VERSION "hnnbnnnynnnnnnnnnnnnnnnnnnnnnnnnnnnnnnnnnn/4/%%%/4/'%**4nnn///"

NS_ :

BS_:

BU_: BAP_Tester Fahrerdisplay_Kombi HUD ICAS1_X_Gateway ICAS3_Gateway ICC_IO_Node Kombi SmartLight_01 ZR_MIB_TOP_ab_Gen3

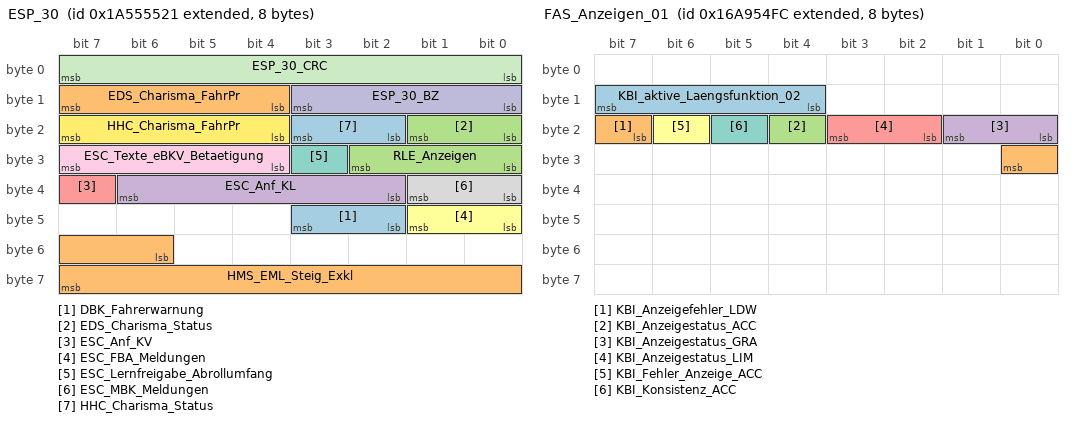
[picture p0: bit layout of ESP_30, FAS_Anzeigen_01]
BO_ 2589283617 ESP_30: 8 ICAS1_X_Gateway
	SG_ DBK_Fahrerwarnung : 42|2@1+ (1,0) [0|3] ""  Fahrerdisplay_Kombi,Kombi
	SG_ EDS_Charisma_FahrPr : 12|4@1+ (1,0) [0|15] ""  Vector__XXX
	SG_ EDS_Charisma_Status : 16|2@1+ (1,0) [0|3] ""  Vector__XXX
	SG_ ESC_Anf_KL : 34|5@1+ (3.22580645,0) [0|99.99999995] "PerCent"  Vector__XXX
	SG_ ESC_Anf_KV : 39|1@1+ (1,0) [0|1] ""  Vector__XXX
	SG_ ESC_FBA_Meldungen : 40|2@1+ (1,0) [0|3] ""  Vector__XXX
	SG_ ESC_Lernfreigabe_Abrollumfang : 27|1@1+ (1,0) [0|1] ""  Vector__XXX
	SG_ ESC_MBK_Meldungen : 32|2@1+ (1,0) [0|3] ""  Kombi
	SG_ ESC_Texte_eBKV_Betaetigung : 28|4@1+ (1,0) [0|15] ""  Vector__XXX
	SG_ ESP_30_BZ : 8|4@1+ (1,0) [0|15] ""  Fahrerdisplay_Kombi,Kombi
	SG_ ESP_30_CRC : 0|8@1+ (1,0) [0|255] ""  Fahrerdisplay_Kombi,Kombi
	SG_ HHC_Charisma_FahrPr : 20|4@1+ (1,0) [0|15] ""  Vector__XXX
	SG_ HHC_Charisma_Status : 18|2@1+ (1,0) [0|3] ""  Vector__XXX
	SG_ HMS_EML_Steig_Exkl : 54|10@1+ (0.2,-102.2) [-102|102.2] "PerCent"  Vector__XXX
	SG_ RLE_Anzeigen : 24|3@1+ (1,0) [0|7] ""  Kombi

BO_ 2527679740 FAS_Anzeigen_01: 8 Kombi
	SG_ KBI_aktive_Laengsfunktion_02 : 12|4@1+ (1,0) [0|15] ""  ICAS1_X_Gateway
	SG_ KBI_Anzeigefehler_LDW : 23|2@1+ (1,0) [0|3] ""  ICAS1_X_Gateway
	SG_ KBI_Anzeigestatus_ACC : 20|1@1+ (1,0) [0|1] ""  ICAS1_X_Gateway
	SG_ KBI_Anzeigestatus_GRA : 16|2@1+ (1,0) [0|3] ""  ICAS1_X_Gateway
	SG_ KBI_Anzeigestatus_LIM : 18|2@1+ (1,0) [0|3] ""  ICAS1_X_Gateway
	SG_ KBI_Fehler_Anzeige_ACC : 22|1@1+ (1,0) [0|1] ""  ICAS1_X_Gateway
	SG_ KBI_Konsistenz_ACC : 21|1@1+ (1,0) [0|1] ""  ICAS1_X_Gateway

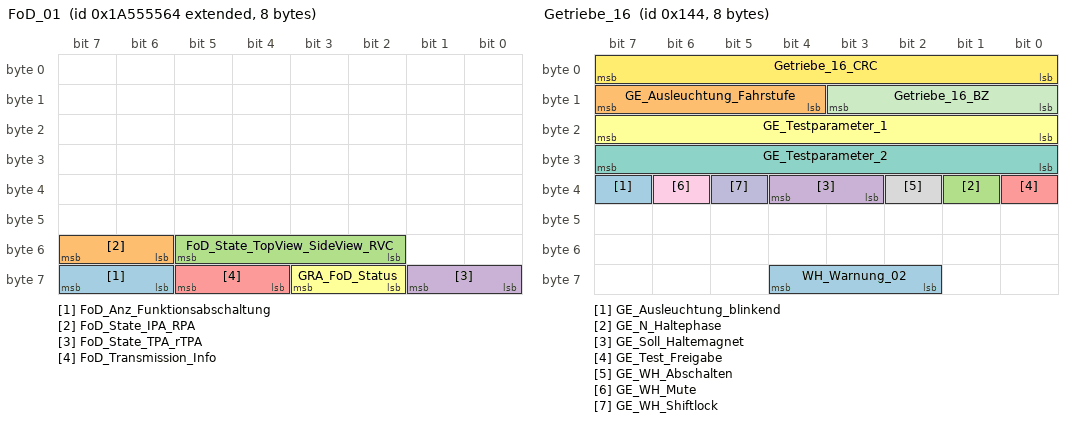
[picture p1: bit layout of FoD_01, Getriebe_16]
BO_ 2589283684 FoD_01: 8 ICAS1_X_Gateway
	SG_ FoD_Anz_Funktionsabschaltung : 62|2@1+ (1,0) [0|3] ""  Kombi
	SG_ FoD_State_IPA_RPA : 54|2@1+ (1,0) [0|3] ""  Vector__XXX
	SG_ FoD_State_TopView_SideView_RVC : 50|4@1+ (1,0) [0|15] ""  Vector__XXX
	SG_ FoD_State_TPA_rTPA : 56|2@1+ (1,0) [0|3] ""  Vector__XXX
	SG_ FoD_Transmission_Info : 60|2@1+ (1,0) [0|3] ""  ICAS3_Gateway,ZR_MIB_TOP_ab_Gen3
	SG_ GRA_FoD_Status : 58|2@1+ (1,0) [0|3] ""  Vector__XXX

BO_ 2549875476 FoD_Kombi_Req: 8 ICAS1_X_Gateway
	SG_ FoD_Kombi_Req_Data : 0|64@1+ (1,0) [0|18446744073709551616] ""  Kombi

BO_ 2550006548 FoD_Kombi_Resp: 8 Kombi
	SG_ FoD_Kombi_Resp_Data : 0|64@1+ (1,0) [0|18446744073709551616] ""  ICAS1_X_Gateway

BO_ 2549875571 FoD_ZR_Req: 8 ICAS1_X_Gateway
	SG_ FoD_ZR_Req_Data : 0|64@1+ (1,0) [0|18446744073709551616] ""  ICAS3_Gateway,ICC_IO_Node,ZR_MIB_TOP_ab_Gen3

BO_ 2550006643 FoD_ZR_Resp: 8 ICAS3_Gateway
	SG_ FoD_ZR_Resp_Data : 0|64@1+ (1,0) [0|18446744073709551616] ""  ICAS1_X_Gateway

BO_ 986 Gateway_71: 8 Vector__XXX
	SG_ ABS_Bremsung : 13|1@1+ (1,0) [0|1] ""  Vector__XXX
	SG_ ECD_Bremslicht : 8|1@1+ (1,0) [0|1] ""  Vector__XXX
	SG_ EPB_01_alt : 1|1@1+ (1,0) [0|1] ""  Vector__XXX
	SG_ EPB_Pedalweg_Kuppl : 16|8@1+ (0.4,0) [8|92] "PerCent"  Vector__XXX
	SG_ EPB_QBit_Pedalweg_Kuppl : 11|1@1+ (1,0) [0|1] ""  Vector__XXX
	SG_ EPB_Status : 9|2@1+ (1,0) [0|3] ""  Vector__XXX
	SG_ ESP_05_alt : 0|1@1+ (1,0) [0|1] ""  Vector__XXX
	SG_ ESP_21_alt : 2|1@1+ (1,0) [0|1] ""  ZR_MIB_TOP_ab_Gen3
	SG_ ESP_Eingriff : 14|1@1+ (1,0) [0|1] ""  Vector__XXX
	SG_ ESP_HDC_Standby : 6|1@1+ (1,0) [0|1] ""  Vector__XXX
	SG_ ESP_MKB_Abbruch_Geschw : 62|1@1+ (1,0) [0|1] ""  Vector__XXX
	SG_ ESP_QBit_v_Signal : 12|1@1+ (1,0) [0|1] ""  ZR_MIB_TOP_ab_Gen3
	SG_ ESP_v_Signal : 24|16@1+ (0.01,0) [0|655.32] "KiloMeterPerHour"  ZR_MIB_TOP_ab_Gen3
	SG_ Kamera_FSH_aktiv : 15|1@1+ (1,0) [0|1] ""  Vector__XXX
	SG_ Kamera_Status_alt : 5|1@1+ (1,0) [0|1] ""  Vector__XXX
	SG_ LWI_01_alt : 3|1@1+ (1,0) [0|1] ""  Vector__XXX
	SG_ LWI_Lenkradwinkel : 43|13@1+ (0.1,0) [0|800] "DegreOfArc"  Vector__XXX
	SG_ LWI_QBit_Lenkradwinkel : 40|1@1+ (1,0) [0|1] ""  Vector__XXX
	SG_ LWI_Sensorstatus : 41|1@1+ (1,0) [0|1] ""  Vector__XXX
	SG_ LWI_VZ_Lenkradwinkel : 42|1@1+ (1,0) [0|1] ""  Vector__XXX
	SG_ Parkhilfe_01_alt : 4|1@1+ (1,0) [0|1] ""  Vector__XXX
	SG_ PH_Anf_Audioabsenkung : 56|1@1+ (1,0) [0|1] ""  Vector__XXX
	SG_ PH_Systemzustand : 57|3@1+ (1,0) [0|7] ""  Vector__XXX
	SG_ PH_Taster : 60|2@1+ (1,0) [0|3] ""  Vector__XXX
	SG_ PLA_Anf_Aufschaltung_RVC : 63|1@1+ (1,0) [0|1] ""  Vector__XXX

BO_ 988 Gateway_73: 8 ICAS1_X_Gateway
	SG_ ACC_18_alt : 59|1@1+ (1,0) [0|1] ""  Vector__XXX
	SG_ ACC_Status_ACC : 56|3@1+ (1,0) [0|7] ""  Vector__XXX
	SG_ EPB_Status_02 : 53|3@1+ (1,0) [0|7] ""  Vector__XXX
	SG_ ESP_07_alt : 1|1@1+ (1,0) [0|1] ""  ICAS3_Gateway,Kombi,ZR_MIB_TOP_ab_Gen3
	SG_ ESP_50_alt : 7|1@1+ (1,0) [0|1] ""  Vector__XXX
	SG_ ESP_Rollenmodus_Deaktivieren : 46|1@1+ (1,0) [0|1] ""  ICAS3_Gateway,Kombi,ZR_MIB_TOP_ab_Gen3
	SG_ ESP_Status_Bremsentemp_02 : 62|2@1+ (1,0) [0|3] ""  Vector__XXX
	SG_ GE_Fahrstufe : 40|4@1+ (1,0) [0|15] ""  ZR_MIB_TOP_ab_Gen3
	SG_ GE_Freilauf_Status : 47|3@1+ (1,0) [0|7] ""  Vector__XXX
	SG_ GE_Notlauf : 45|1@1+ (1,0) [0|1] ""  Vector__XXX
	SG_ GE_Sperr_Info_WFS : 50|1@1+ (1,0) [0|1] ""  Vector__XXX
	SG_ GE_Ursache_Fahrstufe_N : 44|1@1+ (1,0) [0|1] ""  Vector__XXX
	SG_ Getriebe_11_alt : 2|1@1+ (1,0) [0|1] ""  Vector__XXX
	SG_ Getriebe_13_alt : 3|1@1+ (1,0) [0|1] ""  Vector__XXX
	SG_ Getriebe_14_alt : 6|1@1+ (1,0) [0|1] ""  Vector__XXX
	SG_ Getriebe_17_alt : 4|1@1+ (1,0) [0|1] ""  Vector__XXX
	SG_ MKE_Stufe : 11|3@1+ (1,0) [0|7] ""  Vector__XXX
	SG_ MKE_Texte : 9|2@1+ (1,0) [0|3] ""  Vector__XXX
	SG_ MO_Drehzahl_01 : 16|16@1+ (0.25,0) [0|16383] "MinutInver"  Vector__XXX
	SG_ MO_QBit_Drehzahl_01 : 8|1@1+ (1,0) [0|1] ""  ZR_MIB_TOP_ab_Gen3
	SG_ Motor_12_alt : 0|1@1+ (1,0) [0|1] ""  ZR_MIB_TOP_ab_Gen3
	SG_ TSK_06_alt : 5|1@1+ (1,0) [0|1] ""  Vector__XXX
	SG_ TSK_Hauptschalter_GRA_ACC : 14|2@1+ (1,0) [0|3] ""  Vector__XXX
	SG_ TSK_Limiter_ausgewaehlt : 51|1@1+ (1,0) [0|1] ""  Vector__XXX

BO_ 324 Getriebe_16: 8 ICAS1_X_Gateway
	SG_ GE_Ausleuchtung_blinkend : 39|1@1+ (1,0) [0|1] ""  Vector__XXX
	SG_ GE_Ausleuchtung_Fahrstufe : 12|4@1+ (1,0) [0|15] ""  Fahrerdisplay_Kombi,Kombi
	SG_ GE_N_Haltephase : 33|1@1+ (1,0) [0|1] ""  Vector__XXX
	SG_ GE_Soll_Haltemagnet : 35|2@1+ (1,0) [0|3] ""  Vector__XXX
	SG_ GE_Test_Freigabe : 32|1@1+ (1,0) [0|1] ""  Vector__XXX
	SG_ GE_Testparameter_1 : 16|8@1+ (1,0) [0|255] ""  Vector__XXX
	SG_ GE_Testparameter_2 : 24|8@1+ (1,0) [0|255] ""  Vector__XXX
	SG_ GE_WH_Abschalten : 34|1@1+ (1,0) [0|1] ""  Vector__XXX
	SG_ GE_WH_Mute : 38|1@1+ (1,0) [0|1] ""  Vector__XXX
	SG_ GE_WH_Shiftlock : 37|1@1+ (1,0) [0|1] ""  Vector__XXX
	SG_ Getriebe_16_BZ : 8|4@1+ (1,0) [0|15] ""  Fahrerdisplay_Kombi,Kombi
	SG_ Getriebe_16_CRC : 0|8@1+ (1,0) [0|255] ""  Fahrerdisplay_Kombi,Kombi
	SG_ WH_Warnung_02 : 58|3@1+ (1,0) [0|7] ""  Vector__XXX

BO_ 588 Heckradar_01: 16 ICAS1_X_Gateway
	SG_ ASW_Kombiausgabe : 56|3@1+ (1,0) [0|7] ""  Vector__XXX
	SG_ ASW_Kombitexte : 94|3@1+ (1,0) [0|7] ""  Kombi
	SG_ ASW_Modus : 98|3@1+ (1,0) [0|7] ""  Vector__XXX
	SG_ ASW_Status : 86|2@1+ (1,0) [0|3] ""  Vector__XXX
	SG_ ASW_Ton_Richtung_HL : 36|1@1+ (1,0) [0|1] ""  ICAS3_Gateway,ZR_MIB_TOP_ab_Gen3
	SG_ ASW_Ton_Richtung_HR : 37|1@1+ (1,0) [0|1] ""  ICAS3_Gateway,ZR_MIB_TOP_ab_Gen3
	SG_ ASW_Ton_Richtung_VL : 34|1@1+ (1,0) [0|1] ""  ICAS3_Gateway,ZR_MIB_TOP_ab_Gen3
	SG_ ASW_Ton_Richtung_VR : 35|1@1+ (1,0) [0|1] ""  ICAS3_Gateway,ZR_MIB_TOP_ab_Gen3
	SG_ ASW_Warnung_BFS : 93|1@1+ (1,0) [0|1] ""  Vector__XXX
	SG_ ASW_Warnung_FS : 92|1@1+ (1,0) [0|1] ""  Vector__XXX
	SG_ Heckradar_Kombitexte : 120|5@1+ (1,0) [0|31] ""  Kombi
	SG_ HRE_Anzeigetexte : 108|4@1+ (1,0) [0|15] ""  Kombi
	SG_ RCTA_Kombitexte : 125|3@1+ (1,0) [0|7] ""  Kombi
	SG_ SWA_Anzeigen : 76|4@1+ (1,0) [0|15] ""  Kombi
	SG_ SWA_Blindheit_erkannt : 80|1@1+ (1,0) [0|1] ""  Vector__XXX
	SG_ SWA_Blindheitsverdacht : 119|1@1+ (1,0) [0|1] ""  Vector__XXX
	SG_ SWA_Brightness_Mode_FPM : 40|4@1+ (1,0) [0|15] ""  Vector__XXX
	SG_ SWA_FT_RueckLED : 85|1@1+ (1,0) [0|1] ""  Vector__XXX
	SG_ SWA_Gischtzaehler : 112|7@1+ (1,0) [0|100] "PerCent"  Vector__XXX
	SG_ SWA_Infostufe_Assist_li : 46|1@1+ (1,0) [0|1] ""  Vector__XXX
	SG_ SWA_Infostufe_Assist_re : 47|1@1+ (1,0) [0|1] ""  Vector__XXX
	SG_ SWA_Kombiausgabe : 53|3@1+ (1,0) [0|7] ""  Vector__XXX
	SG_ SWA_LED_Hell_BFS : 12|7@1+ (1,0) [0|100] "PerCent"  Vector__XXX
	SG_ SWA_LED_Hell_FS : 19|7@1+ (1,0) [0|100] "PerCent"  Vector__XXX
	SG_ SWA_LED_Modus_BFS : 26|3@1+ (1,0) [0|7] ""  Vector__XXX
	SG_ SWA_LED_Modus_FS : 29|3@1+ (1,0) [0|7] ""  Vector__XXX
	SG_ SWA_Modus : 101|3@1+ (1,0) [0|7] ""  Vector__XXX
	SG_ SWA_Modus_System : 50|3@1+ (1,0) [0|7] ""  Vector__XXX
	SG_ SWA_rel_Fehler : 82|1@1+ (1,0) [0|1] ""  Vector__XXX
	SG_ SWA_rel_Nichtverf : 81|1@1+ (1,0) [0|1] ""  Vector__XXX
	SG_ SWA_Sta_aktiv : 83|1@1+ (1,0) [0|1] ""  Kombi
	SG_ SWA_Sta_passiv : 84|1@1+ (1,0) [0|1] ""  Kombi
	SG_ SWA_Standziele_li : 88|1@1+ (1,0) [0|1] ""  Vector__XXX
	SG_ SWA_Standziele_re : 104|1@1+ (1,0) [0|1] ""  Vector__XXX
	SG_ SWA_Status : 32|2@1+ (1,0) [0|3] ""  Vector__XXX
	SG_ SWA_Status_KuFu : 44|2@1+ (1,0) [0|3] ""  Vector__XXX
	SG_ SWA_Status_System : 38|2@1+ (1,0) [0|3] ""  Vector__XXX
	SG_ SWA_Warnstufe_Assist_li : 48|1@1+ (1,0) [0|1] ""  Vector__XXX
	SG_ SWA_Warnstufe_Assist_re : 49|1@1+ (1,0) [0|1] ""  Vector__XXX

BO_ 589 Heckradar_02: 64 ICAS1_X_Gateway
	SG_ SWA_Infostufe_SWA_li : 60|1@1+ (1,0) [0|1] ""  Kombi
	SG_ SWA_Infostufe_SWA_re : 61|1@1+ (1,0) [0|1] ""  Kombi
	SG_ SWA_Kolonne_li : 57|1@1+ (1,0) [0|1] ""  Vector__XXX
	SG_ SWA_Kolonne_mi : 58|1@1+ (1,0) [0|1] ""  Vector__XXX
	SG_ SWA_Kolonne_re : 59|1@1+ (1,0) [0|1] ""  Vector__XXX
	SG_ SWA_Obj_01_Breite : 137|7@1+ (0.03125,0) [0|3.9375] "Meter"  Vector__XXX
	SG_ SWA_Obj_01_Existenzwahrsch : 153|7@1+ (1,0) [0|100] "PerCent"  Vector__XXX
	SG_ SWA_Obj_01_Gemessen : 92|1@1+ (1,0) [0|1] ""  Vector__XXX
	SG_ SWA_Obj_01_GeschwRelX : 128|9@1+ (0.25,-37.5) [-37.5|90] "MeterPerSecon"  Vector__XXX
	SG_ SWA_Obj_01_GeschwRelY : 144|9@1+ (0.03125,-7.9375) [-7.9375|8] "MeterPerSecon"  Vector__XXX
	SG_ SWA_Obj_01_ID : 93|5@1+ (1,0) [1|30] ""  Vector__XXX
	SG_ SWA_Obj_01_Laenge : 177|7@1+ (0.25,0) [0|31.5] "Meter"  Vector__XXX
	SG_ SWA_Obj_01_Objektklasse : 160|4@1+ (1,0) [0|15] ""  Vector__XXX
	SG_ SWA_Obj_01_PositionX : 168|9@1+ (0.25,-102.5) [-102.5|25] "Meter"  Vector__XXX
	SG_ SWA_Obj_01_PositionY : 184|8@1+ (0.125,-16) [-16|15.75] "Meter"  Vector__XXX
	SG_ SWA_Obj_01_ReferenzPkt : 164|4@1+ (1,0) [0|15] ""  Vector__XXX
	SG_ SWA_Obj_02_Breite : 201|7@1+ (0.03125,0) [0|3.9375] "Meter"  Vector__XXX
	SG_ SWA_Obj_02_Existenzwahrsch : 217|7@1+ (1,0) [0|100] "PerCent"  Vector__XXX
	SG_ SWA_Obj_02_Gemessen : 98|1@1+ (1,0) [0|1] ""  Vector__XXX
	SG_ SWA_Obj_02_GeschwRelX : 192|9@1+ (0.25,-37.5) [-37.5|90] "MeterPerSecon"  Vector__XXX
	SG_ SWA_Obj_02_GeschwRelY : 208|9@1+ (0.03125,-7.9375) [-7.9375|8] "MeterPerSecon"  Vector__XXX
	SG_ SWA_Obj_02_ID : 99|5@1+ (1,0) [1|30] ""  Vector__XXX
	SG_ SWA_Obj_02_Laenge : 241|7@1+ (0.25,0) [0|31.5] "Meter"  Vector__XXX
	SG_ SWA_Obj_02_Objektklasse : 224|4@1+ (1,0) [0|15] ""  Vector__XXX
	SG_ SWA_Obj_02_PositionX : 232|9@1+ (0.25,-102.5) [-102.5|25] "Meter"  Vector__XXX
	SG_ SWA_Obj_02_PositionY : 248|8@1+ (0.125,-16) [-16|15.75] "Meter"  Vector__XXX
	SG_ SWA_Obj_02_ReferenzPkt : 228|4@1+ (1,0) [0|15] ""  Vector__XXX
	SG_ SWA_Obj_03_Breite : 265|7@1+ (0.03125,0) [0|3.9375] "Meter"  Vector__XXX
	SG_ SWA_Obj_03_Existenzwahrsch : 281|7@1+ (1,0) [0|100] "PerCent"  Vector__XXX
	SG_ SWA_Obj_03_Gemessen : 104|1@1+ (1,0) [0|1] ""  Vector__XXX
	SG_ SWA_Obj_03_GeschwRelX : 256|9@1+ (0.25,-37.5) [-37.5|90] "MeterPerSecon"  Vector__XXX
	SG_ SWA_Obj_03_GeschwRelY : 272|9@1+ (0.03125,-7.9375) [-7.9375|8] "MeterPerSecon"  Vector__XXX
	SG_ SWA_Obj_03_ID : 105|5@1+ (1,0) [1|30] ""  Vector__XXX
	SG_ SWA_Obj_03_Laenge : 305|7@1+ (0.25,0) [0|31.5] "Meter"  Vector__XXX
	SG_ SWA_Obj_03_Objektklasse : 288|4@1+ (1,0) [0|15] ""  Vector__XXX
	SG_ SWA_Obj_03_PositionX : 296|9@1+ (0.25,-102.5) [-102.5|25] "Meter"  Vector__XXX
	SG_ SWA_Obj_03_PositionY : 312|8@1+ (0.125,-16) [-16|15.75] "Meter"  Vector__XXX
	SG_ SWA_Obj_03_ReferenzPkt : 292|4@1+ (1,0) [0|15] ""  Vector__XXX
	SG_ SWA_Obj_04_Breite : 329|7@1+ (0.03125,0) [0|3.9375] "Meter"  Vector__XXX
	SG_ SWA_Obj_04_Existenzwahrsch : 345|7@1+ (1,0) [0|100] "PerCent"  Vector__XXX
	SG_ SWA_Obj_04_Gemessen : 110|1@1+ (1,0) [0|1] ""  Vector__XXX
	SG_ SWA_Obj_04_GeschwRelX : 320|9@1+ (0.25,-37.5) [-37.5|90] "MeterPerSecon"  Vector__XXX
	SG_ SWA_Obj_04_GeschwRelY : 336|9@1+ (0.03125,-7.9375) [-7.9375|8] "MeterPerSecon"  Vector__XXX
	SG_ SWA_Obj_04_ID : 111|5@1+ (1,0) [1|30] ""  Vector__XXX
	SG_ SWA_Obj_04_Laenge : 369|7@1+ (0.25,0) [0|31.5] "Meter"  Vector__XXX
	SG_ SWA_Obj_04_Objektklasse : 352|4@1+ (1,0) [0|15] ""  Vector__XXX
	SG_ SWA_Obj_04_PositionX : 360|9@1+ (0.25,-102.5) [-102.5|25] "Meter"  Vector__XXX
	SG_ SWA_Obj_04_PositionY : 376|8@1+ (0.125,-16) [-16|15.75] "Meter"  Vector__XXX
	SG_ SWA_Obj_04_ReferenzPkt : 356|4@1+ (1,0) [0|15] ""  Vector__XXX
	SG_ SWA_Obj_05_Breite : 393|7@1+ (0.03125,0) [0|3.9375] "Meter"  Vector__XXX
	SG_ SWA_Obj_05_Existenzwahrsch : 409|7@1+ (1,0) [0|100] "PerCent"  Vector__XXX
	SG_ SWA_Obj_05_Gemessen : 116|1@1+ (1,0) [0|1] ""  Vector__XXX
	SG_ SWA_Obj_05_GeschwRelX : 384|9@1+ (0.25,-37.5) [-37.5|90] "MeterPerSecon"  Vector__XXX
	SG_ SWA_Obj_05_GeschwRelY : 400|9@1+ (0.03125,-7.9375) [-7.9375|8] "MeterPerSecon"  Vector__XXX
	SG_ SWA_Obj_05_ID : 117|5@1+ (1,0) [1|30] ""  Vector__XXX
	SG_ SWA_Obj_05_Laenge : 433|7@1+ (0.25,0) [0|31.5] "Meter"  Vector__XXX
	SG_ SWA_Obj_05_Objektklasse : 416|4@1+ (1,0) [0|15] ""  Vector__XXX
	SG_ SWA_Obj_05_PositionX : 424|9@1+ (0.25,-102.5) [-102.5|25] "Meter"  Vector__XXX
	SG_ SWA_Obj_05_PositionY : 440|8@1+ (0.125,-16) [-16|15.75] "Meter"  Vector__XXX
	SG_ SWA_Obj_05_ReferenzPkt : 420|4@1+ (1,0) [0|15] ""  Vector__XXX
	SG_ SWA_Obj_06_Breite : 457|7@1+ (0.03125,0) [0|3.9375] "Meter"  Vector__XXX
	SG_ SWA_Obj_06_Existenzwahrsch : 473|7@1+ (1,0) [0|100] "PerCent"  Vector__XXX
	SG_ SWA_Obj_06_Gemessen : 122|1@1+ (1,0) [0|1] ""  Vector__XXX
	SG_ SWA_Obj_06_GeschwRelX : 448|9@1+ (0.25,-37.5) [-37.5|90] "MeterPerSecon"  Vector__XXX
	SG_ SWA_Obj_06_GeschwRelY : 464|9@1+ (0.03125,-7.9375) [-7.9375|8] "MeterPerSecon"  Vector__XXX
	SG_ SWA_Obj_06_ID : 123|5@1+ (1,0) [1|30] ""  Vector__XXX
	SG_ SWA_Obj_06_Laenge : 497|7@1+ (0.25,0) [0|31.5] "Meter"  Vector__XXX
	SG_ SWA_Obj_06_Objektklasse : 480|4@1+ (1,0) [0|15] ""  Vector__XXX
	SG_ SWA_Obj_06_PositionX : 488|9@1+ (0.25,-102.5) [-102.5|25] "Meter"  Vector__XXX
	SG_ SWA_Obj_06_PositionY : 504|8@1+ (0.125,-16) [-16|15.75] "Meter"  Vector__XXX
	SG_ SWA_Obj_06_ReferenzPkt : 484|4@1+ (1,0) [0|15] ""  Vector__XXX
	SG_ SWA_Obj_Kurvenradius : 64|16@1+ (1,-32767) [-32767|32767] "Meter"  Vector__XXX
	SG_ SWA_StrukturLinks_querAbstand : 12|9@1+ (0.03125,0) [0|15.9375] "Meter"  Vector__XXX
	SG_ SWA_StrukturLinks_Typ : 21|3@1+ (1,0) [0|7] ""  Vector__XXX
	SG_ SWA_StrukturRechts_querAbstand : 80|9@1+ (0.03125,0) [0|15.9375] "Meter"  Vector__XXX
	SG_ SWA_StrukturRechts_Typ : 89|3@1+ (1,0) [0|7] ""  Vector__XXX
	SG_ SWA_Umfeld_Zeitstempel : 24|16@1+ (0.1,0) [0|6553.5] "MilliSecon"  Vector__XXX
	SG_ SWA_Umfeld_Zeitstempel_Status : 54|3@1+ (1,0) [0|7] ""  Vector__XXX
	SG_ SWA_Warnung_SWA_li : 62|1@1+ (1,0) [0|1] ""  Kombi
	SG_ SWA_Warnung_SWA_re : 63|1@1+ (1,0) [0|1] ""  Kombi

BO_ 2635073907 HID_DispKBI_FS_ZR_Req_FD: 64 Fahrerdisplay_Kombi
	SG_ HID_DispKBI_FS_ZR_Req_FD_Data : 0|512@1+ (1,0) [0|13407807929942597099574024998205846127479365820592393377723561443721764030073546976801874298166903427690031858186486050853753882811946569946433649006084096] ""  ICAS3_Gateway

BO_ 2635204979 HID_DispKBI_FS_ZR_Resp_FD: 64 ICAS3_Gateway
	SG_ HID_DispKBI_FS_ZR_Resp_FD_Data : 0|512@1+ (1,0) [0|13407807929942597099574024998205846127479365820592393377723561443721764030073546976801874298166903427690031858186486050853753882811946569946433649006084096] ""  Fahrerdisplay_Kombi

BO_ 2634029939 HID_HUD_ZR_Req_FD: 64 HUD
	SG_ HID_HUD_ZR_Req_FD_Data : 0|512@1+ (1,0) [0|13407807929942597099574024998205846127479365820592393377723561443721764030073546976801874298166903427690031858186486050853753882811946569946433649006084096] ""  ICAS3_Gateway,ICC_IO_Node,ZR_MIB_TOP_ab_Gen3

BO_ 2634161011 HID_HUD_ZR_Resp_FD: 64 ICAS3_Gateway
	SG_ HID_HUD_ZR_Resp_FD_Data : 0|512@1+ (1,0) [0|13407807929942597099574024998205846127479365820592393377723561443721764030073546976801874298166903427690031858186486050853753882811946569946433649006084096] ""  HUD

BO_ 2634314505 HID_ZR_DispKBI_FS_Req_FD: 64 ICAS3_Gateway
	SG_ HID_ZR_DispKBI_FS_Req_FD_Data : 0|512@1+ (1,0) [0|13407807929942597099574024998205846127479365820592393377723561443721764030073546976801874298166903427690031858186486050853753882811946569946433649006084096] ""  Fahrerdisplay_Kombi

BO_ 2634445577 HID_ZR_DispKBI_FS_Resp_FD: 64 Fahrerdisplay_Kombi
	SG_ HID_ZR_DispKBI_FS_Resp_FD_Data : 0|512@1+ (1,0) [0|13407807929942597099574024998205846127479365820592393377723561443721764030073546976801874298166903427690031858186486050853753882811946569946433649006084096] ""  ICAS3_Gateway

BO_ 2634052379 HID_ZR_HUD_Req_FD: 64 ICAS3_Gateway
	SG_ HID_ZR_HUD_Req_FD_Data : 0|512@1+ (1,0) [0|13407807929942597099574024998205846127479365820592393377723561443721764030073546976801874298166903427690031858186486050853753882811946569946433649006084096] ""  HUD

BO_ 2634183451 HID_ZR_HUD_Resp_FD: 64 HUD
	SG_ HID_ZR_HUD_Resp_FD_Data : 0|512@1+ (1,0) [0|13407807929942597099574024998205846127479365820592393377723561443721764030073546976801874298166903427690031858186486050853753882811946569946433649006084096] ""  ICAS3_Gateway,ICC_IO_Node,ZR_MIB_TOP_ab_Gen3

BO_ 2629835579 HUD_ARC_Req_FD: 64 HUD
	SG_ HUD_ARC_Req_FD_Data : 0|512@1+ (1,0) [0|13407807929942597099574024998205846127479365820592393377723561443721764030073546976801874298166903427690031858186486050853753882811946569946433649006084096] ""  ICAS3_Gateway,ICC_IO_Node,ZR_MIB_TOP_ab_Gen3

BO_ 2629966651 HUD_ARC_Resp_FD: 64 ICAS3_Gateway
	SG_ HUD_ARC_Resp_FD_Data : 0|512@1+ (1,0) [0|13407807929942597099574024998205846127479365820592393377723561443721764030073546976801874298166903427690031858186486050853753882811946569946433649006084096] ""  HUD

BO_ 1283 HVK_01: 8 ICAS1_X_Gateway
	SG_ HV_Bordnetz_aktiv : 41|1@1+ (1,0) [0|1] ""  Vector__XXX
	SG_ HV_Bordnetz_Fehler : 42|1@1+ (1,0) [0|1] ""  Vector__XXX
	SG_ HVK_01_BZ : 8|4@1+ (1,0) [0|15] ""  Fahrerdisplay_Kombi
	SG_ HVK_01_CRC : 0|8@1+ (1,0) [0|255] ""  Fahrerdisplay_Kombi
	SG_ HVK_AktiveEntladung_Anf : 45|1@1+ (1,0) [0|1] ""  Vector__XXX
	SG_ HVK_BMS_Sollmodus : 24|3@1+ (1,0) [0|7] ""  Vector__XXX
	SG_ HVK_DCDC_Sollmodus : 27|3@1+ (1,0) [0|7] ""  Vector__XXX
	SG_ HVK_EKK_Sollmodus : 30|3@1+ (1,0) [0|7] ""  Vector__XXX
	SG_ HVK_Gesamtst_Spgfreiheit : 43|2@1+ (1,0) [0|3] ""  Kombi
	SG_ HVK_HV_Netz_Warnungen : 39|2@1+ (1,0) [0|3] ""  Fahrerdisplay_Kombi,Kombi
	SG_ HVK_HVEM_Freigabe : 46|2@1+ (1,0) [0|3] ""  Vector__XXX
	SG_ HVK_HVLM_Sollmodus : 36|3@1+ (1,0) [0|7] ""  Vector__XXX
	SG_ HVK_HVPTC_Sollmodus : 33|3@1+ (1,0) [0|7] ""  Vector__XXX
	SG_ HVK_Iso_Messung_Start : 50|3@1+ (1,0) [0|7] ""  Vector__XXX
	SG_ HVK_Istmodus_Anf : 12|1@1+ (1,0) [0|1] ""  Vector__XXX
	SG_ HVK_Ladebereit : 53|3@1+ (1,0) [0|7] ""  Vector__XXX
	SG_ HVK_Notabschaltung_Anf : 48|2@1+ (1,0) [0|3] ""  Vector__XXX
	SG_ HVK_PPulsFreigabe : 56|2@1+ (1,0) [0|3] ""  Vector__XXX
	SG_ HVK_TN1_Sollmodus : 13|2@1+ (1,0) [0|3] ""  Vector__XXX
	SG_ HVK_Vorladung_aktiv : 15|1@1+ (1,0) [0|1] ""  Vector__XXX

BO_ 2527679583 IPA_02: 8 ICAS1_X_Gateway
	SG_ FoD_DTC_IPA_EPH : 17|1@1+ (1,0) [0|1] ""  Vector__XXX
	SG_ FoD_DTC_RPA_EPH : 16|1@1+ (1,0) [0|1] ""  Vector__XXX
	SG_ FoD_DTC_TPA_rTPA_EPH : 18|2@1+ (1,0) [0|3] ""  Vector__XXX
	SG_ IPA_02_BZ : 8|4@1+ (1,0) [0|15] ""  Vector__XXX
	SG_ IPA_02_CRC : 0|8@1+ (1,0) [0|255] ""  Vector__XXX
	SG_ IPA_Anf_Meldungen : 56|8@1+ (1,0) [0|255] ""  Kombi
	SG_ Parken_aktives_System_02 : 24|5@1+ (1,0) [0|31] ""  Vector__XXX
	SG_ Parken_Aktivierungslicht_Anf : 36|1@1+ (1,0) [0|1] ""  Vector__XXX
	SG_ Parken_Bestaetigungsblinken_Anf : 52|2@1+ (1,0) [0|3] ""  Vector__XXX
	SG_ Parken_Fahrbereitschaftlicht_Anf : 54|1@1+ (1,0) [0|1] ""  Vector__XXX
	SG_ Parken_Fahrerhinweise_Anf : 51|1@1+ (1,0) [0|1] ""  Vector__XXX
	SG_ Parken_Fahrtrichtungslicht_Anf : 37|2@1+ (1,0) [0|3] ""  Vector__XXX
	SG_ Parken_FFB_LED_Anf : 32|2@1+ (1,0) [0|3] ""  Vector__XXX
	SG_ Parken_Lichtnachlauf_Anf : 39|1@1+ (1,0) [0|1] ""  Vector__XXX
	SG_ Parken_Lichtsteuerung_Anf : 55|1@1+ (1,0) [0|1] ""  Vector__XXX
	SG_ Parken_Schluesselsuche_Anf : 31|1@1+ (1,0) [0|1] ""  Vector__XXX
	SG_ Parken_Seitenspiegel_Anf : 20|2@1+ (1,0) [0|3] ""  Vector__XXX
	SG_ Parken_Wegfahrsperren_Anf : 34|2@1+ (1,0) [0|3] ""  Vector__XXX
	SG_ Parken_ZR_Sondermodus_Anf : 29|2@1+ (1,0) [0|3] ""  Vector__XXX
	SG_ Parken_ZV_Schliessen : 22|2@1+ (1,0) [0|3] ""  Vector__XXX
	SG_ RA_Anf_Meldung : 40|7@1+ (1,0) [0|127] ""  Vector__XXX

BO_ 1792 ISO_Funktionaler_Req_All: 8 ICAS1_X_Gateway
	SG_ ISO_ALL_01_Req_Data : 0|64@1+ (1,0) [0|18446744073709551616] ""  Fahrerdisplay_Kombi,HUD,ICAS3_Gateway,ICC_IO_Node,Kombi,SmartLight_01,ZR_MIB_TOP_ab_Gen3

BO_ 1819 ISO_HUD_Req: 8 ICAS1_X_Gateway
	SG_ ISO_HUD_Req_Data : 0|64@1+ (1,0) [0|18446744073709551616] ""  HUD

BO_ 1925 ISO_HUD_Resp: 8 HUD
	SG_ ISO_HUD_Resp_Data : 0|64@1+ (1,0) [0|18446744073709551616] ""  ICAS1_X_Gateway

BO_ 1812 ISO_Kombi_Req: 8 ICAS1_X_Gateway
	SG_ ISO_Kombi_Req_Data : 0|64@1+ (1,0) [0|18446744073709551616] ""  Kombi

BO_ 1918 ISO_Kombi_Resp: 8 Kombi
	SG_ ISO_Kombi_Resp_Data : 0|64@1+ (1,0) [0|18446744073709551616] ""  ICAS1_X_Gateway

BO_ 2549358366 ISO_NFCIApp_NFCIServ_Req: 8 Vector__XXX
	SG_ ISO_NFCIApp_NFCIServ_Req_Data : 0|64@1+ (1,0) [0|18446744073709551616] ""  ICAS1_X_Gateway

BO_ 2549489183 ISO_NFCIApp_NFCIServ_Resp: 8 ICAS1_X_Gateway
	SG_ ISO_NFCIApp_NFCIServ_Resp_Data : 0|64@1+ (1,0) [0|18446744073709551616] ""  Vector__XXX

BO_ 2549358111 ISO_NFCIServ_NFCIApp_Req: 8 ICAS1_X_Gateway
	SG_ ISO_NFCIServ_NFCIApp_Req_Data : 0|64@1+ (1,0) [0|18446744073709551616] ""  Vector__XXX

BO_ 2549489438 ISO_NFCIServ_NFCIApp_Resp: 8 Vector__XXX
	SG_ ISO_NFCIServ_NFCIApp_Resp_Data : 0|64@1+ (1,0) [0|18446744073709551616] ""  ICAS1_X_Gateway

BO_ 1901 ISO_TV_Tuner_Req: 8 ICAS1_X_Gateway
	SG_ ISO_TV_Tuner_Req_Data : 0|64@1+ (1,0) [0|18446744073709551616] ""  ZR_MIB_TOP_ab_Gen3

BO_ 2007 ISO_TV_Tuner_Resp: 8 ZR_MIB_TOP_ab_Gen3
	SG_ ISO_TV_Tuner_Resp_Data : 0|64@1+ (1,0) [0|18446744073709551616] ""  ICAS1_X_Gateway

BO_ 2550398985 ISOx_DispKBI_FS_Req: 8 ICAS1_X_Gateway
	SG_ ISOx_DispKBI_FS_Req_Data : 0|64@1+ (1,0) [0|18446744073709551616] ""  Fahrerdisplay_Kombi

BO_ 2621702153 ISOx_DispKBI_FS_Req_FD: 64 ICAS1_X_Gateway
	SG_ ISOx_DispKBI_FS_Req_FD_Data : 0|512@1+ (1,0) [0|13407807929942597099574024998205846127479365820592393377723561443721764030073546976801874298166903427690031858186486050853753882811946569946433649006084096] ""  Fahrerdisplay_Kombi

BO_ 2550530057 ISOx_DispKBI_FS_Resp: 8 Fahrerdisplay_Kombi
	SG_ ISOx_DispKBI_FS_Resp_Data : 0|64@1+ (1,0) [0|18446744073709551616] ""  ICAS1_X_Gateway

BO_ 2621833225 ISOx_DispKBI_FS_Resp_FD: 64 Fahrerdisplay_Kombi
	SG_ ISOx_DispKBI_FS_Resp_FD_Data : 0|512@1+ (1,0) [0|13407807929942597099574024998205846127479365820592393377723561443721764030073546976801874298166903427690031858186486050853753882811946569946433649006084096] ""  ICAS1_X_Gateway

BO_ 2621505536 ISOx_Funkt_Req_All_FD: 64 ICAS1_X_Gateway
	SG_ ISOx_Funkt_Req_All_FD_Data : 0|512@1+ (1,0) [0|13407807929942597099574024998205846127479365820592393377723561443721764030073546976801874298166903427690031858186486050853753882811946569946433649006084096] ""  Fahrerdisplay_Kombi,HUD,ICAS3_Gateway,Kombi,SmartLight_01,ZR_MIB_TOP_ab_Gen3

BO_ 2621440027 ISOx_HUD_Req_FD: 64 ICAS1_X_Gateway
	SG_ ISOx_HUD_Req_FD_Data : 0|512@1+ (1,0) [0|13407807929942597099574024998205846127479365820592393377723561443721764030073546976801874298166903427690031858186486050853753882811946569946433649006084096] ""  HUD

BO_ 2621571099 ISOx_HUD_Resp_FD: 64 HUD
	SG_ ISOx_HUD_Resp_FD_Data : 0|512@1+ (1,0) [0|13407807929942597099574024998205846127479365820592393377723561443721764030073546976801874298166903427690031858186486050853753882811946569946433649006084096] ""  ICAS1_X_Gateway

BO_ 2621440020 ISOx_Kombi_Req_FD: 64 ICAS1_X_Gateway
	SG_ ISOx_Kombi_Req_FD_Data : 0|512@1+ (1,0) [0|13407807929942597099574024998205846127479365820592393377723561443721764030073546976801874298166903427690031858186486050853753882811946569946433649006084096] ""  Kombi

BO_ 2621571092 ISOx_Kombi_Resp_FD: 64 Kombi
	SG_ ISOx_Kombi_Resp_FD_Data : 0|512@1+ (1,0) [0|13407807929942597099574024998205846127479365820592393377723561443721764030073546976801874298166903427690031858186486050853753882811946569946433649006084096] ""  ICAS1_X_Gateway

BO_ 2550398988 ISOx_SmLi_01_Req: 8 ICAS1_X_Gateway
	SG_ ISOx_SmLi_01_Req_Data : 0|64@1+ (1,0) [0|18446744073709551616] ""  SmartLight_01

BO_ 2621702156 ISOx_SmLi_01_Req_FD: 64 ICAS1_X_Gateway
	SG_ ISOx_SmLi_01_Req_FD_Data : 0|512@1+ (1,0) [0|13407807929942597099574024998205846127479365820592393377723561443721764030073546976801874298166903427690031858186486050853753882811946569946433649006084096] ""  SmartLight_01

BO_ 2550530060 ISOx_SmLi_01_Resp: 8 SmartLight_01
	SG_ ISOx_SmLi_01_Resp_Data : 0|64@1+ (1,0) [0|18446744073709551616] ""  ICAS1_X_Gateway

BO_ 2621833228 ISOx_SmLi_01_Resp_FD: 64 SmartLight_01
	SG_ ISOx_SmLi_01_Resp_FD_Data : 0|512@1+ (1,0) [0|13407807929942597099574024998205846127479365820592393377723561443721764030073546976801874298166903427690031858186486050853753882811946569946433649006084096] ""  ICAS1_X_Gateway

BO_ 2549874853 ISOx_WLC1_Req: 8 ICAS1_X_Gateway
	SG_ ISOx_WLC1_Req_Data : 0|64@1+ (1,0) [0|18446744073709551616] ""  ICAS3_Gateway,ICC_IO_Node,ZR_MIB_TOP_ab_Gen3

BO_ 2550005925 ISOx_WLC1_Resp: 8 ICAS3_Gateway
	SG_ ISOx_WLC1_Resp_Data : 0|64@1+ (1,0) [0|18446744073709551616] ""  ICAS1_X_Gateway

BO_ 1426 Kessy_04: 8 ICAS1_X_Gateway
	SG_ KY_Aktive_LFScans : 38|4@1+ (1,0) [0|15] ""  Vector__XXX
	SG_ KY_AnzKoord_Info : 43|2@1+ (1,0) [0|3] ""  Vector__XXX
	SG_ KY_EasyClose_Abbruch : 32|1@1+ (1,0) [0|1] ""  Vector__XXX
	SG_ KY_EasyClose_Status : 33|3@1+ (1,0) [0|7] ""  Vector__XXX
	SG_ KY_Fzg_Verlassen_erkannt : 30|1@1+ (1,0) [0|1] ""  Vector__XXX
	SG_ KY_Fzg_Zugang_erkannt : 31|1@1+ (1,0) [0|1] ""  Vector__XXX
	SG_ KY_Gestik_HD : 27|1@1+ (1,0) [0|1] ""  Vector__XXX
	SG_ KY_Gong_600 : 22|1@1+ (1,0) [0|1] ""  Vector__XXX
	SG_ KY_HD_Auffahrt : 36|1@1+ (1,0) [0|1] ""  Vector__XXX
	SG_ KY_HD_Zufahrt : 37|1@1+ (1,0) [0|1] ""  Vector__XXX
	SG_ KY_ID_Geber1_im_Fzg : 12|1@1+ (1,0) [0|1] ""  Vector__XXX
	SG_ KY_ID_Geber2_im_Fzg : 13|1@1+ (1,0) [0|1] ""  Vector__XXX
	SG_ KY_ID_Geber3_im_Fzg : 14|1@1+ (1,0) [0|1] ""  Vector__XXX
	SG_ KY_ID_Geber4_im_Fzg : 15|1@1+ (1,0) [0|1] ""  Vector__XXX
	SG_ KY_ID_Geber_Suche : 17|1@1+ (1,0) [0|1] ""  Vector__XXX
	SG_ KY_LF_Aktiv : 42|1@1+ (1,0) [0|1] ""  ICAS3_Gateway,ICC_IO_Node,ZR_MIB_TOP_ab_Gen3
	SG_ KY_Meldungen : 18|4@1+ (1,0) [0|15] ""  Vector__XXX
	SG_ KY_Passiv_Autolock : 25|1@1+ (1,0) [0|1] ""  Vector__XXX
	SG_ KY_Passiv_Autolock_Akt : 24|1@1+ (1,0) [0|1] ""  Vector__XXX
	SG_ KY_Passiv_Autolock_Menue : 23|1@1+ (1,0) [0|1] ""  Vector__XXX
	SG_ KY_Passiv_Autounlock : 26|1@1+ (1,0) [0|1] ""  Vector__XXX
	SG_ KY_Schluesselposition_1 : 48|2@1+ (1,0) [0|3] ""  Vector__XXX
	SG_ KY_Schluesselposition_2 : 50|2@1+ (1,0) [0|3] ""  Vector__XXX
	SG_ KY_Schluesselposition_3 : 52|2@1+ (1,0) [0|3] ""  Vector__XXX
	SG_ KY_Schluesselposition_4 : 54|2@1+ (1,0) [0|3] ""  Vector__XXX
	SG_ KY_Schluesselposition_5 : 56|2@1+ (1,0) [0|3] ""  Vector__XXX
	SG_ KY_Schluesselposition_6 : 58|2@1+ (1,0) [0|3] ""  Vector__XXX
	SG_ KY_Schluesselposition_7 : 60|2@1+ (1,0) [0|3] ""  Vector__XXX
	SG_ KY_Schluesselposition_8 : 62|2@1+ (1,0) [0|3] ""  Vector__XXX
	SG_ KY_Schluesselposition_9 : 45|2@1+ (1,0) [0|3] ""  Vector__XXX
	SG_ KY_Startknopf_Bel : 16|1@1+ (1,0) [0|1] ""  Vector__XXX
	SG_ KY_StartStopp_Info : 28|2@1+ (1,0) [0|3] ""  Vector__XXX

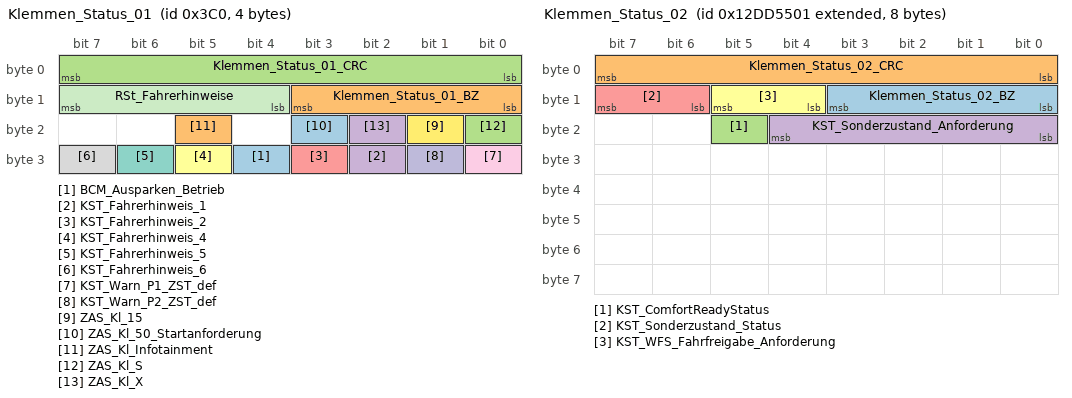
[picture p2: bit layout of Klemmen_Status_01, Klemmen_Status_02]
BO_ 960 Klemmen_Status_01: 4 ICAS1_X_Gateway
	SG_ BCM_Ausparken_Betrieb : 28|1@1+ (1,0) [0|1] ""  ICAS3_Gateway,ICC_IO_Node,ZR_MIB_TOP_ab_Gen3
	SG_ Klemmen_Status_01_BZ : 8|4@1+ (1,0) [0|15] ""  ICAS3_Gateway,ICC_IO_Node,Kombi,ZR_MIB_TOP_ab_Gen3
	SG_ Klemmen_Status_01_CRC : 0|8@1+ (1,0) [0|255] ""  ICAS3_Gateway,ICC_IO_Node,Kombi,ZR_MIB_TOP_ab_Gen3
	SG_ KST_Fahrerhinweis_1 : 26|1@1+ (1,0) [0|1] ""  ICAS3_Gateway,ICC_IO_Node,ZR_MIB_TOP_ab_Gen3
	SG_ KST_Fahrerhinweis_2 : 27|1@1+ (1,0) [0|1] ""  ICAS3_Gateway,ICC_IO_Node,ZR_MIB_TOP_ab_Gen3
	SG_ KST_Fahrerhinweis_4 : 29|1@1+ (1,0) [0|1] ""  ICAS3_Gateway,ICC_IO_Node,ZR_MIB_TOP_ab_Gen3
	SG_ KST_Fahrerhinweis_5 : 30|1@1+ (1,0) [0|1] ""  ICAS3_Gateway,ICC_IO_Node,ZR_MIB_TOP_ab_Gen3
	SG_ KST_Fahrerhinweis_6 : 31|1@1+ (1,0) [0|1] ""  ICAS3_Gateway,ICC_IO_Node,ZR_MIB_TOP_ab_Gen3
	SG_ KST_Warn_P1_ZST_def : 24|1@1+ (1,0) [0|1] ""  ICAS3_Gateway,ICC_IO_Node,ZR_MIB_TOP_ab_Gen3
	SG_ KST_Warn_P2_ZST_def : 25|1@1+ (1,0) [0|1] ""  ICAS3_Gateway,ICC_IO_Node,ZR_MIB_TOP_ab_Gen3
	SG_ RSt_Fahrerhinweise : 12|4@1+ (1,0) [0|15] ""  ICAS3_Gateway,ICC_IO_Node,ZR_MIB_TOP_ab_Gen3
	SG_ ZAS_Kl_15 : 17|1@1+ (1,0) [0|1] ""  Fahrerdisplay_Kombi,HUD,ICAS3_Gateway,ICC_IO_Node,Kombi,SmartLight_01,ZR_MIB_TOP_ab_Gen3
	SG_ ZAS_Kl_50_Startanforderung : 19|1@1+ (1,0) [0|1] ""  ICAS3_Gateway,ICC_IO_Node,ZR_MIB_TOP_ab_Gen3
	SG_ ZAS_Kl_Infotainment : 21|1@1+ (1,0) [0|1] ""  ICAS3_Gateway,ICC_IO_Node,ZR_MIB_TOP_ab_Gen3
	SG_ ZAS_Kl_S : 16|1@1+ (1,0) [0|1] ""  HUD,ICAS3_Gateway,ICC_IO_Node,Kombi,ZR_MIB_TOP_ab_Gen3
	SG_ ZAS_Kl_X : 18|1@1+ (1,0) [0|1] ""  ICAS3_Gateway,ICC_IO_Node,ZR_MIB_TOP_ab_Gen3

BO_ 2463978753 Klemmen_Status_02: 8 ICAS1_X_Gateway
	SG_ Klemmen_Status_02_BZ : 8|4@1+ (1,0) [0|15] ""  Vector__XXX
	SG_ Klemmen_Status_02_CRC : 0|8@1+ (1,0) [0|255] ""  Vector__XXX
	SG_ KST_ComfortReadyStatus : 21|1@1+ (1,0) [0|1] ""  Vector__XXX
	SG_ KST_Sonderzustand_Anforderung : 16|5@1+ (1,0) [0|31] ""  Vector__XXX
	SG_ KST_Sonderzustand_Status : 14|2@1+ (1,0) [0|3] ""  Vector__XXX
	SG_ KST_WFS_Fahrfreigabe_Anforderung : 12|2@1+ (1,0) [0|3] ""  Vector__XXX

BO_ 1420 Klemmen_Steuerung_01: 8 ICAS1_X_Gateway
	SG_ Klemmen_Steuerung_01_BZ : 8|4@1+ (1,0) [0|15] ""  Vector__XXX
	SG_ Klemmen_Steuerung_01_CRC : 0|8@1+ (1,0) [0|255] ""  Vector__XXX
	SG_ KST_Anf_Klemme_15 : 12|1@1+ (1,0) [0|1] ""  Vector__XXX
	SG_ KST_Anf_Klemme_50 : 13|1@1+ (1,0) [0|1] ""  Vector__XXX
	SG_ KST_Anf_Klemme_S : 14|1@1+ (1,0) [0|1] ""  Vector__XXX
	SG_ KST_Anf_Klemmenfreigabe_ELV : 18|1@1+ (1,0) [0|1] ""  Vector__XXX
	SG_ KST_Anf_Klemmenfreigabe_WFS : 23|1@1+ (1,0) [0|1] ""  Vector__XXX
	SG_ KST_Anf_ZV_Verriegelung : 24|1@1+ (1,0) [0|1] ""  Vector__XXX
	SG_ KST_aut_Abschaltung_Zuendung : 22|1@1+ (1,0) [0|1] ""  Vector__XXX
	SG_ KST_Fahrer_Info_Text : 31|3@1+ (1,0) [0|7] ""  Kombi
	SG_ KST_KL15LockStatus : 34|2@1+ (1,0) [0|3] ""  Vector__XXX
	SG_ KST_Txt_Komfortabschaltung : 19|1@1+ (1,0) [0|1] ""  Vector__XXX
	SG_ KST_Txt_P_Gang : 16|1@1+ (1,0) [0|1] ""  Vector__XXX
	SG_ KST_Txt_Panikabschaltung : 17|1@1+ (1,0) [0|1] ""  Kombi
	SG_ KST_Txt_Werkstatt : 15|1@1+ (1,0) [0|1] ""  Kombi
	SG_ KST_Unterdr_Zuendungsmeldung : 21|1@1+ (1,0) [0|1] ""  Vector__XXX
	SG_ KST_ZAT_betaetigt : 20|1@1+ (1,0) [0|1] ""  Vector__XXX
	SG_ KST_Zuendungswarnung : 29|2@1+ (1,0) [0|3] ""  Kombi
	SG_ Relais_VoKo_angesteuert : 25|1@1+ (1,0) [0|1] ""  Vector__XXX
	SG_ RSt_Anforderung_HMS : 26|3@1+ (1,0) [0|7] ""  Vector__XXX

BO_TX_BU_ 2589283617 :ICAS1_X_Gateway;
BO_TX_BU_ 2527679740 :Kombi;
BO_TX_BU_ 2589283684 :ICAS1_X_Gateway;
BO_TX_BU_ 2549875476 :ICAS1_X_Gateway;
BO_TX_BU_ 2550006548 :Kombi;
BO_TX_BU_ 2549875571 :ICAS1_X_Gateway;
BO_TX_BU_ 2550006643 :ICAS3_Gateway,ICC_IO_Node,ZR_MIB_TOP_ab_Gen3;
BO_TX_BU_ 988 :ICAS1_X_Gateway;
BO_TX_BU_ 324 :ICAS1_X_Gateway;
BO_TX_BU_ 588 :ICAS1_X_Gateway;
BO_TX_BU_ 589 :ICAS1_X_Gateway;
BO_TX_BU_ 2635073907 :Fahrerdisplay_Kombi;
BO_TX_BU_ 2635204979 :ICAS3_Gateway;
BO_TX_BU_ 2634029939 :HUD;
BO_TX_BU_ 2634161011 :ICAS3_Gateway,ICC_IO_Node,ZR_MIB_TOP_ab_Gen3;
BO_TX_BU_ 2634314505 :ICAS3_Gateway;
BO_TX_BU_ 2634445577 :Fahrerdisplay_Kombi;
BO_TX_BU_ 2634052379 :ICAS3_Gateway,ICC_IO_Node,ZR_MIB_TOP_ab_Gen3;
BO_TX_BU_ 2634183451 :HUD;
BO_TX_BU_ 2629835579 :HUD;
BO_TX_BU_ 2629966651 :ICAS3_Gateway,ICC_IO_Node,ZR_MIB_TOP_ab_Gen3;
BO_TX_BU_ 1283 :ICAS1_X_Gateway;
BO_TX_BU_ 2527679583 :ICAS1_X_Gateway;
BO_TX_BU_ 1792 :ICAS1_X_Gateway;
BO_TX_BU_ 1819 :ICAS1_X_Gateway;
BO_TX_BU_ 1925 :HUD;
BO_TX_BU_ 1812 :ICAS1_X_Gateway;
BO_TX_BU_ 1918 :Kombi;
BO_TX_BU_ 2549489183 :ICAS1_X_Gateway;
BO_TX_BU_ 2549358111 :ICAS1_X_Gateway;
BO_TX_BU_ 1901 :ICAS1_X_Gateway;
BO_TX_BU_ 2007 :ZR_MIB_TOP_ab_Gen3;
BO_TX_BU_ 2550398985 :ICAS1_X_Gateway;
BO_TX_BU_ 2621702153 :ICAS1_X_Gateway;
BO_TX_BU_ 2550530057 :Fahrerdisplay_Kombi;
BO_TX_BU_ 2621833225 :Fahrerdisplay_Kombi;
BO_TX_BU_ 2621505536 :ICAS1_X_Gateway;
BO_TX_BU_ 2621440027 :ICAS1_X_Gateway;
BO_TX_BU_ 2621571099 :HUD;
BO_TX_BU_ 2621440020 :ICAS1_X_Gateway;
BO_TX_BU_ 2621571092 :Kombi;
BO_TX_BU_ 2550398988 :ICAS1_X_Gateway;
BO_TX_BU_ 2621702156 :ICAS1_X_Gateway;
BO_TX_BU_ 2550530060 :SmartLight_01;
BO_TX_BU_ 2621833228 :SmartLight_01;
BO_TX_BU_ 2549874853 :ICAS1_X_Gateway;
BO_TX_BU_ 2550005925 :ICAS3_Gateway,ICC_IO_Node,ZR_MIB_TOP_ab_Gen3;
BO_TX_BU_ 1426 :ICAS1_X_Gateway;
BO_TX_BU_ 960 :ICAS1_X_Gateway;
BO_TX_BU_ 2463978753 :ICAS1_X_Gateway;
BO_TX_BU_ 1420 :ICAS1_X_Gateway;
CM_ BO_ 986 "Fahrwerk, Extended -> Komfort, Infotainment";
CM_ BO_ 988 "Antrieb, Fahrwerk -> Extended, Infotainment, Komfort";
CM_ BO_ 2527679583 "ehemals ZFAS_01";
CM_ BO_ 2621505536 "VWAG Diagnose funktionaler Request auf CANFD";
CM_ BO_ 960 "MQB";
CM_ SG_ 2589283617 DBK_Fahrerwarnung "Warnt den Fahrer bei erkannter Dampfblase in der Bremsflï?½ssigkeit und fordert ihn zum Anhalten sowie Werkstattbesuch auf (2 Bit):\n0: kein Anfordern (Initwert)\n1: Warnereignis 1 - fordert Warnlampe, Warnmeldung (Aufforderung Anhalten) und Warnton sowie F";
CM_ SG_ 2589283617 EDS_Charisma_FahrPr "Aktuelles Fahrprogramm des Charisma-Teilnehmers Elektronische Differentialsperre EDS";
CM_ SG_ 2589283617 EDS_Charisma_Status "Systemstatus des Charismateilnehmers Elektronische Differentialsperre EDS";
CM_ SG_ 2589283617 ESC_Anf_KL "Nachricht an Motor- bzw. Antriebssteuergerï?½t zur Festlegung der Motorluefterdrehzahl\nAngabe in Prozent der Maximaldrehzahl";
CM_ SG_ 2589283617 ESC_Anf_KV "Nachricht an Motor bzw. Antriebssteuergerï?½t zum ï?½ffnen der Kï?½hlerjalousie.";
CM_ SG_ 2589283617 ESC_FBA_Meldungen "Hinweis an den Fahrer ï?½ber das Kombi, bei dauerhafter Bergabfahrt einen Gang einzulegen um die Motorbremse zu nutzen.\nUnterscheidung zwischen: \nHandschalterfahrzeugen (FBA_Warnung_aktiv_MT)\nAutomatikfahrzeugen (FBA_Warnung_aktiv_AT)";
CM_ SG_ 2589283617 ESC_Lernfreigabe_Abrollumfang "Meldet einen Fahrdynamikzustand, der es zulï?½sst, dass der Abrollumfang der Rï?½der genauer errechnet werden darf.\nDie Verwendung des Signals ist ausschlieï?½lich fï?½r die MQB-Plattform zugelassen.";
CM_ SG_ 2589283617 ESC_MBK_Meldungen "Das Signal steuert die Schaltempfehlung im Kombi, die bei Bergabfahrt den Fahrer darauf hinweist in eine geeignete Fahrstufe zu schalten um eine Rekuperation zu ermï?½glichen.";
CM_ SG_ 2589283617 ESC_Texte_eBKV_Betaetigung "Anweisungen an den Fahrer fï?½r die Betï?½tigung der Bremse ï?½ber den eBKV unter Verwendung der Schaltwippen am Lenkrad.";
CM_ SG_ 2589283617 ESP_30_BZ "4bit Botschaftszï?½hler, wird mit jeder Sendebotschaft inkrementiert";
CM_ SG_ 2589283617 ESP_30_CRC "Fï?½r MLB:\nBerechnung siehe Lastenheft 'Kommunikationsabsicherung fï?½r FlexRay und CAN'\nAb MQB und MLBevo:\nBerechnung siehe Lastenheft 'End-to-End Kommunikationsabsicherung'\n\nEndwerte siehe Begleitdokument 'S-PDU Kennungsfolgen'";
CM_ SG_ 2589283617 HHC_Charisma_FahrPr "Aktuelles Fahrprogramm des Charisma-Teilnehmers Berganfahrassistent HHC";
CM_ SG_ 2589283617 HHC_Charisma_Status "Systemstatus des Charismateilnehmers Berganfahrassistent HHC";
CM_ SG_ 2589283617 HMS_EML_Steig_Exkl "Steigung in Prozent. Das Signal dient der Weiterleitung der Steigung an den Basisdienst EML. \nPositive Werte > bergauf; \nNegative Werte < bergab\n\nBitte Beachten: Das Signal darf  von Kundenfunktionen nicht genutzt werden. Dieses Signal nutzt niemand a";
CM_ SG_ 2589283617 RLE_Anzeigen "Anzeigen fï?½r die Radlï?½seerkennung";
CM_ SG_ 2527679740 KBI_aktive_Laengsfunktion_02 "Auswahl, der vom Fahrer gewï?½nschten Laengsregelfunktion";
CM_ SG_ 2527679740 KBI_Anzeigestatus_ACC "Status der ACC-Anzeige im nicht permanenten Displaybereich";
CM_ SG_ 2527679740 KBI_Anzeigestatus_GRA "Anzeigestatus der GRA High Wunschgeschwindigkeitsanzeige im Kombiinstrument.\nBei VW bedeutet 'nicht vorhanden' GRA-low fï?½hig (LED immer verbaut).\n0 = nicht vorhanden\n1 = Wunschgeschwindigkeits-Anzeigemï?½glichkeit vorhanden\n2 = reserviert\n3 = Fehler (B";
CM_ SG_ 2527679740 KBI_Anzeigestatus_LIM "Anzeigestatus der Speedlimiter Wunschgeschwindigkeitsanzeige im Kombiinstrument (permanenter Anzeigebereich)\n0 = nicht vorhanden\n1 = Wunschgeschwindigkeits-Anzeigemï?½glichkeit vorhanden\n2 = reserviert\n3 = Fehler (Botschaftsï?½berwachung, Timeout, Akustik";
CM_ SG_ 2527679740 KBI_Fehler_Anzeige_ACC "Rï?½ckmeldung an ACC, dass mindestens eine der ACC-relevanten Anzeigen -rote Fahrerï?½bernahme, Mitteldisplay, Gong - fehlerhaft sind.";
CM_ SG_ 2527679740 KBI_Konsistenz_ACC "Rï?½ckmeldung an ACC, dass die Botschaften zur Ansteuerung von Anzeigen nicht bzw. nicht konsistent empfangen wurden (Timeout-, BZ-, CHK- und DLC-Fehler)                                                                                                        ";
CM_ SG_ 2589283684 FoD_Anz_Funktionsabschaltung "Signal triggert Aufschaltung eines Popups, um dem Fahrer die Abschaltung einer Funktion zu melden.";
CM_ SG_ 2589283684 FoD_State_IPA_RPA "Function on Demand Activation State for IPA and RPA";
CM_ SG_ 2589283684 FoD_State_TopView_SideView_RVC "Function on Demand State for TopView and SideView and RearView";
CM_ SG_ 2589283684 FoD_State_TPA_rTPA "Function on Demand Activation State for TPA and rTPA from Function Master";
CM_ SG_ 2589283684 FoD_Transmission_Info "Mit dem Signal zeigt der FoD-Master allen FoD-Slaves den Beginn und das Ende eines Freischaltuebertragungszykluses (FS-ID-Zyklus) an.";
CM_ SG_ 2589283684 GRA_FoD_Status "Verortung des FOD-Slaves fï?½r die Funktion GRA erfolgt im Gateway. Signal ï?½bermittelt den FOD-Status an das MSG.";
CM_ SG_ 2549875476 FoD_Kombi_Req_Data "Function on demand request an Kombiinstrument";
CM_ SG_ 2550006548 FoD_Kombi_Resp_Data "Function on demand response vom Kombiinstrument";
CM_ SG_ 2549875571 FoD_ZR_Req_Data "FoD - Function On Demand\nISO-TP Datenkanal - FID2NA\nRequest Funktion 0x03 FoD-Master\n\nFoD-Master an Zentralrechner";
CM_ SG_ 2550006643 FoD_ZR_Resp_Data "FoD - Function On Demand\nISO-TP Datenkanal - FID2NA\nResponse Knoten 0x73 Zentralrechner\n\nZentralrechner an FoD Master";
CM_ SG_ 986 ABS_Bremsung "Antiblockiersystem, Bit zeigt auch Druckabbau an (z.B. ESP hat zuviel Druck aufgebaut oder ungebremste Regelung auf Bahnï?½bergang)\nWeiterfï?½hrende Informationen im Lastenheft spezifiziert und in der entsprechenden Fachabteilung zu erfragen.";
CM_ SG_ 986 ECD_Bremslicht "Bremslichtansteuerung durch ECD-Funktion";
CM_ SG_ 986 EPB_Pedalweg_Kuppl "Signal entspricht Tastverhï?½ltnis des PWM. Gesamtweg Kupplungspedal 10% bis 90%, damit zu erwartende Werte 25 bis 225. 25 bei Kupplungspedal nicht getreten, 225 bei Kupplungspedal voll durchgetreten.\n2% Toleranz wird im Wertebereich ermï?½glicht (8%-92%).\n";
CM_ SG_ 986 EPB_Status "Gibt den Zustand der EPB-Aktuatoren an.\n\nNur VW526/PAG E2: Wert 0x3 bedeutet 'unbekannt'\n\n";
CM_ SG_ 986 ESP_Eingriff "Eingriff des Fahrdynamikreglers";
CM_ SG_ 986 ESP_HDC_Standby "Verwendung/Bedienung im MQB und AU57x Allroad:\nFlag wird vom ESP gesetzt, wenn ï?½ber den HDC-Taster die HDC-Funktion eingeschalten wurde";
CM_ SG_ 986 ESP_MKB_Abbruch_Geschw "Im Falle einer Multikollisionsbremsung teilt das ESP den Abbruch der MKB aufgrund der unteren Geschwindigkeitsschwelle mit.";
CM_ SG_ 986 ESP_QBit_v_Signal "Geschwindigkeit wird vom ABS/ASR oder ESP aus Ersatzwerten errechnet, wenn Bit gesetzt ist. Gï?½te des Signals ist verï?½ndert.";
CM_ SG_ 986 ESP_v_Signal "Geschwindigkeitssignal vom ABS/ASR oder ESP. Mittelwert der angetriebenen Rï?½der.\nBei MSR oder ABS Eingriffen wird die ABS-Referenzgeschwindigkeit fï?½r >= 200ms eingespiegelt (Zeit wird mit Aktiv-Flanke der Funktionsbits getriggert)\n\nMQB: Bei Frontantrie";
CM_ SG_ 986 Kamera_FSH_aktiv "Bei aktivierter (lokaler) Frontscheibenheizung wird die Scheibentemperaturmessung des Klimafeuchtesensors beeinflusst. ï?½ber das Signal wird dem Klima-SG mitgeteilt, dass die lokale Scheibenheizung aktiviert ist, um entsprechende Korrekturwerte bei der Sch";
CM_ SG_ 986 LWI_Lenkradwinkel "Wertebereich = +/- 800 Grad\nAuflï?½sung = 0,1 Grad\nACHTUNG: spezifizierte Interne Auflï?½sung des Sensors betrï?½gt aber nur Schrittweite 0,5 Grad!\n\nHinweis:\nMLB: Zusï?½tzlich gestellte Winkel bei Dynamiklenkung beachten !\nMQB: Nicht konstante Lenkï?½bersetzu";
CM_ SG_ 986 LWI_QBit_Lenkradwinkel "Das QBit wird auch bei nicht abgeglichenem Lenkradwinkelsensor gesetzt";
CM_ SG_ 986 LWI_VZ_Lenkradwinkel "Vorzeichen Lenkradwinkel gemï?½ss DIN70000; \nNullstellung = +0";
CM_ SG_ 986 PH_Anf_Audioabsenkung "Es gibt zwei unterschiedliche Nachlauftimer fï?½r dieses Bit:\n1. normale Funktion\n2. Demotonausgabe";
CM_ SG_ 986 PH_Systemzustand "Aktivierungsursache wird fï?½r die Dauer der Aktivierung gemeldet.\nIm Fehlerfall bei atkviem System wechselt das Signal auf '7'\n(siehe auch 'Abschaltursache')";
CM_ SG_ 986 PH_Taster "Taster Status (fï?½r RVC/TopView)";
CM_ SG_ 986 PLA_Anf_Aufschaltung_RVC "Anforderung der Aufschaltung RVC durch PLA";
CM_ SG_ 988 ACC_18_alt "Veraltet-Bit";
CM_ SG_ 988 ACC_Status_ACC "'ACC OFF' bedeutet ACC-Hauptschalter ist 'Gerastet Aus\n\n'ACC Reversibler Fehler' bedeutet, daï?½ das ACC aktuell einen \nreversiblen Fehler im ACC-SG selbst oder in einem zum \nACC-System gehï?½renden SG erkennt.\n\n'ACC irreversibler Fehler' bedeutet, daï?½ ";
CM_ SG_ 988 EPB_Status_02 "Erweiterung der Zustï?½nde um ein genaueres Bild des aktuellen Zustandes zu erhalten fï?½r weitergehende Funktionen ( Stillstandsmanager)\n";
CM_ SG_ 988 ESP_50_alt "Veraltet-Bit";
CM_ SG_ 988 ESP_Rollenmodus_Deaktivieren "Zwang zum Abbruch des Rollenmodus mit anschlieï?½ender ESP-Vollfunktion.\nMQB: Zwang zum Abbruch des Rollenmodus in allen Funktionsteilnehmern (Empfï?½nger) mit anschlieï?½ender ESP-Vollfunktion (Sender).\nSignal wird vom ESP dauerhaft mit gï?½ltigen Werten bedat";
CM_ SG_ 988 ESP_Status_Bremsentemp_02 "Bremsscheibentemperaturmodell. Rï?½ckmeldung fï?½r Sender einer Verzï?½gerungsanforderung";
CM_ SG_ 988 GE_Fahrstufe "Fahrprogramm des Getriebes\n\nHinweis: Zwischenstellung '0x0' darf nur fï?½r Zustandswechsel P/R, R/N, N/D ausgegeben werden, nicht fï?½r D/S oder D/Tippgasse wegen Abschaltkriterium GRA/ACC";
CM_ SG_ 988 GE_Freilauf_Status "Freilauf-Status-Signal vom Frailauf-Master an aktive Freilauf-Teilnehmer. In diesem Signal zeigt der Freilauf-Master an, welchen aktuellen Status die Freilauf-Betriebsstrategie hat.";
CM_ SG_ 988 GE_Notlauf "AL/DL: Signalisiert wenn sich das Getriebe (bei DL ein Teilgetriebe) im Notlauf befindet.\nVL: Wird gesetzt wenn kein Kraftschluss mï?½glich ist.";
CM_ SG_ 988 GE_Sperr_Info_WFS "WFS-Sperrinformation";
CM_ SG_ 988 GE_Ursache_Fahrstufe_N "Zeigt an, warum Fahrstufe N angenommen wurde. So kann z.B. die Rollsicherung im Verlassenskonzept aktiv bleiben, wenn das Schalten nach N ohne Fahrerwunsch erfolgte (z.B. Fehlerreaktion).\n\nACHTUNG: Das Signal darf nur ausgewertet werden, wenn GE_Fahrstu";
CM_ SG_ 988 MKE_Stufe "Das Signal bildet die Mï?½digkeitsstufe im Kombi ab:\n0 - deaktiviert\n1 - nicht_verfï?½gbar\n2 - Stufe_1\n3 - Stufe_2\n4 - Stufe_3\n5 - Stufe_4\n6 - reserviert\n7 - reserviert";
CM_ SG_ 988 MKE_Texte "Systemhinweis und Sicherheitshinweis fï?½r Anzeige im Kombi";
CM_ SG_ 988 MO_Drehzahl_01 "Im Fehlerfall wird die Motordrehzahl ï?½ber die Nockenwellendrehzahl als Ersatzgrï?½sse ausgegeben\n\nBei Parallelhybrid: Getriebeeingangsdrehzahl (=E-Maschinen Drehzahl)\n\nHinweis: \nEhemaliger Fehlerwert 0xFFFF wird senderseitig nicht unterstï?½tzt. \nDiesen";
CM_ SG_ 988 MO_QBit_Drehzahl_01 "AUDI D4: Zykluszeit: 10ms (siehe Zykluszeit schnell/Cycletime Fast)\n\nAchtung:\nReduktion der Zykluszeit Motor_03 auf 10ms geplant.\nProjektabhï?½ngig soll kï?½nftig mit 10ms gesendet werden.\nEmpfï?½nger die in weiteren Konzern-Projekten eingesetzt werden mï?½s";
CM_ SG_ 988 TSK_06_alt "Veraltet-Bit fï?½r die BotschaftTSK_06_alt";
CM_ SG_ 988 TSK_Hauptschalter_GRA_ACC "Stellung des GRA/ACC Hauptschalters. Das Signal wird auch bei Fehlerabschaltungen von GRA/ACC weiterhin bedient und ermï?½glicht fï?½r ACC die Steuerung der ACC-Anzeige auch in Fehlerfï?½llen.";
CM_ SG_ 988 TSK_Limiter_ausgewaehlt "ACC/GRA-Betrieb nur bei nicht ausgewï?½hltem Limiter mï?½glich";
CM_ SG_ 324 GE_Ausleuchtung_blinkend "Anforderung einer blinkenden Fahrstufenausleuchtung in der Schaltbetï?½tigung";
CM_ SG_ 324 GE_Ausleuchtung_Fahrstufe "Fahrstufe zur Anzeige in der Schaltbetï?½tigung. Ist die Fahrstufe ungï?½ltig, wird keine Fahrstufe angezeigt.";
CM_ SG_ 324 GE_N_Haltephase "Das Getriebe signalisiert dem Waehlhebel, dass die N-Haltephase aktiv ist. \nDanach kann der Waehlhebel ein Abschalten des I-CAN ermï?½glichen";
CM_ SG_ 324 GE_Soll_Haltemagnet "Sollposition des Parksperren-Haltemagneten fï?½r die Ansteuerung durch den Waehlhebel";
CM_ SG_ 324 GE_Test_Freigabe "Das Bit wird auf 1 gesetzt, wenn gï?½ltige Testparameter gesendet werden.";
CM_ SG_ 324 GE_Testparameter_1 "Testparameter 1 (Frage) zur ï?½berwachung des Wï?½hlhebel-SG";
CM_ SG_ 324 GE_Testparameter_2 "Testparameter 2 (Frage) zur ï?½berwachung des Wï?½hlhebel-SG";
CM_ SG_ 324 GE_WH_Abschalten "Mit diesem Bit kann das Getriebe das Wï?½hlhebel-SG reseten bzw. dauerhaft deaktivieren. Der Wï?½hlhebel geht dann in einen Standby-Modus. ";
CM_ SG_ 324 GE_WH_Mute "Anforderung an die Schaltbetï?½tigung, den Sendebetrieb einzustellen.";
CM_ SG_ 324 GE_WH_Shiftlock "Bit wird auf 1 gesetzt, wenn getriebeseitigen Bedingungen erfï?½llt sind, um Wï?½hlhebel zu bewegen.";
CM_ SG_ 324 Getriebe_16_CRC "Fï?½r MLB:\n'Berechnung siehe Lastenheft 'Kommunikationsabsicherung fï?½r FlexRay und CAN''\n\nAb MQB und MLBevo:\n'Berechnung siehe Lastenheft 'End-to-End Kommunikationsabsicherung''\n\nEndwerte siehe Begleitdokument 'S-PDU Kennungsfolgen'";
CM_ SG_ 324 WH_Warnung_02 "Warnmeldungen vom Waehlhebel an das Kombi";
CM_ SG_ 588 ASW_Kombiausgabe "ASW_Kombiausgabe bestimmt, welcher Text im Kombi angezeigt wird. Darï?½ber hinaus werden auch Kombi-Akkustik durch dieses Signal ausgelï?½st.";
CM_ SG_ 588 ASW_Kombitexte "ASW_Kombitexte bestimmt welcher Text im Kombi angezeigt wird. Darï?½ber hinaus werden auch Kombi-Akkustik durch dieses Signal ausgelï?½st.\n\nDieses Signal ersetzt SWA_Anzeigen fï?½r den ASW-Anteil. Der SWA-Anteil des alten Signals findet sich in SWA-Kombitexte";
CM_ SG_ 588 ASW_Modus "gibt die Verfï?½gbarkeit der ASW Modus an";
CM_ SG_ 588 ASW_Status "Funktionsstatus Ausstiegswarnung (ASW)";
CM_ SG_ 588 ASW_Ton_Richtung_HL "ASW-Warntonausgabe hinten links";
CM_ SG_ 588 ASW_Ton_Richtung_HR "ASW_Warntonausgabe hinten rechts";
CM_ SG_ 588 ASW_Ton_Richtung_VL "ASW-Warntonausgabe vorne links";
CM_ SG_ 588 ASW_Ton_Richtung_VR "ASW-Warntonausgabe vorne rechts";
CM_ SG_ 588 ASW_Warnung_BFS "Modus Beifahrerseite der Funktion Ausstiegswarnung (ASW)";
CM_ SG_ 588 ASW_Warnung_FS "Modus Beifahrerseite der Funktion Ausstiegswarnung (ASW)";
CM_ SG_ 588 Heckradar_Kombitexte "Heckradar_Kombitexte bestimmt welcher Text im Kombi angezeigt wird. Darï?½ber hinaus werden auch Kombi-Akkustik durch dieses Signal ausgelï?½st.\n\nDieses Signal ersetzt SWA_Anzeigen und deckt alle Kombinationsmï?½glichkeiten der Heckradarfunktionen ab. Die Fun";
CM_ SG_ 588 HRE_Anzeigetexte "HRE-Texte und -Akustik zur Anzeige im Kombiinstrument";
CM_ SG_ 588 RCTA_Kombitexte "RCTA_Kombitexte bestimmt welcher Text im Kombi angezeigt wird. Darï?½ber hinaus werden auch Kombi-Akkustik durch dieses Signal ausgelï?½st.";
CM_ SG_ 588 SWA_Anzeigen "SWA- Texte und -Akustik zur Anzeige im Kombiinstrument\n0x7-0xF = reserviert";
CM_ SG_ 588 SWA_Blindheit_erkannt "SWA erkennt selbstï?½ndig eigene Blindheit durch ï?½uï?½ere Einflï?½sse.";
CM_ SG_ 588 SWA_Blindheitsverdacht "Signalwert wird auf Blindheitsverdacht_erkannt gesetzt, wenn ein im Datensatz parametrierbarer Schwellwert ï?½berschritten wurde.\nDas Signal dient als Vorstufe zur SWA Blindheit und schaltet nicht die SWA Funktion ab.";
CM_ SG_ 588 SWA_Brightness_Mode_FPM "Actual mode for brightness settings of function Spurwechselassistent";
CM_ SG_ 588 SWA_FT_RueckLED "SWA/ASW Rï?½ckmelde-LED. Zeigt den Aktivierungszustand der Funktionen SWA/ASW";
CM_ SG_ 588 SWA_Gischtzaehler "Zï?½hler, der die eigene Gischt bei nasser Fahrbahn misst (Kennwert)";
CM_ SG_ 588 SWA_Infostufe_Assist_li "Aktion der SWA-Funktion auf der entsprechenden Fahrzeugseite";
CM_ SG_ 588 SWA_Infostufe_Assist_re "Aktion der SWA-Funktion auf der entsprechenden Fahrzeugseite";
CM_ SG_ 588 SWA_Kombiausgabe "SWA_Kombiausgabe bestimmt, welcher Text im Kombi angezeigt wird.";
CM_ SG_ 588 SWA_LED_Hell_BFS "Helligkeitswert SWA LED Beifahrerseite";
CM_ SG_ 588 SWA_LED_Hell_FS "Helligkeitswert SWA LED Fahrerseite";
CM_ SG_ 588 SWA_LED_Modus_BFS "Ansteuerung SWA LED Beifahrerseite";
CM_ SG_ 588 SWA_LED_Modus_FS "Ansteuerung SWA LED Fahrerseite";
CM_ SG_ 588 SWA_Modus "gibt die Verfï?½gbarkeit der SWA Modus an";
CM_ SG_ 588 SWA_Modus_System "Gibt Zusatzinformationen zum SWA System Status an";
CM_ SG_ 588 SWA_rel_Fehler "Hinweis: In Zukunft das Signal SWA_Modus anstatt SWA_rel_Fehler verwenden!\n\nSWA erkennt einen Fehler, die Objektdetektion betreffend, mit FSP-Eintrag.";
CM_ SG_ 588 SWA_rel_Nichtverf "Hinweis: In Zukunft das Signal SWA_Modus anstatt SWA_rel_Nichtverf verwenden!\n\nSWA erkennt eine Nichtverfuegbarkeit, die Objektdetektion betreffend, ohne FSP-Eintrag";
CM_ SG_ 588 SWA_Sta_aktiv "SWA Status aktiv; Lampenansteuerung im Kombi";
CM_ SG_ 588 SWA_Sta_passiv "Hinweis: In Zukunft das Signal SWA_Status anstatt SWA_Sta_passiv verwenden!\n\nSWA Status passiv; Lampenansteuerung im Kombi";
CM_ SG_ 588 SWA_Standziele_li "Hinweis: In Zukunft das Signal SWA_StrukturLinks_querAbstand anstatt SWA_Standziele_li verwenden!\n\nAbstand zwischen Fahrzeug und Standziele links geringer als ein applizierbarer Wert.";
CM_ SG_ 588 SWA_Standziele_re "Hinweis: In Zukunft das Signal SWA_StrukturRechts_querAbstand anstatt SWA_Standziele_re verwenden!\n\nAbstand zwischen Fahrzeug und Standziele links geringer als ein applizierbarer Wert.";
CM_ SG_ 588 SWA_Status "gibt die Verfï?½gbarkeit der SWA_Status an";
CM_ SG_ 588 SWA_Status_KuFu "Gibt den Status der Kundenfunktion SWA an";
CM_ SG_ 588 SWA_Status_System "Gibt den Status des Systems SWA an";
CM_ SG_ 588 SWA_Warnstufe_Assist_li "Aktion der SWA-Funktion auf der entsprechenden Fahrzeugseite";
CM_ SG_ 588 SWA_Warnstufe_Assist_re "Aktion der SWA-Funktion auf der entsprechenden Fahrzeugseite";
CM_ SG_ 589 SWA_Infostufe_SWA_li "Aktion der SWA-Funktion auf der entsprechenden Fahrzeugseite";
CM_ SG_ 589 SWA_Infostufe_SWA_re "Aktion der SWA-Funktion auf der entsprechenden Fahrzeugseite";
CM_ SG_ 589 SWA_Kolonne_li "Info, dass auf der entspr. Spur mehr als zwei Fahrzeuge zu finden sind. ";
CM_ SG_ 589 SWA_Kolonne_mi "Info, dass auf der entspr. Spur mehr als zwei Fahrzeuge zu finden sind. ";
CM_ SG_ 589 SWA_Kolonne_re "Info, dass auf der entspr. Spur mehr als zwei Fahrzeuge zu finden sind. ";
CM_ SG_ 589 SWA_Obj_01_Breite "Breite des Objektes in Metern";
CM_ SG_ 589 SWA_Obj_01_Existenzwahrsch "Existenzwahrscheinlichkeit des Objektes in Prozent";
CM_ SG_ 589 SWA_Obj_01_Gemessen "Status Objekt gemessen/getrackt";
CM_ SG_ 589 SWA_Obj_01_GeschwRelX "Relative Geschwindigkeit in x (m/s)\nGeschwindigkeiten beziehen sich immer auf den Objektmittelpunkt\nMessung in Radialrichtung";
CM_ SG_ 589 SWA_Obj_01_GeschwRelY "Relative Geschwindigkeit in y (m/s)\nGeschwindigkeiten beziehen sich immer auf den Objektmittelpunkt";
CM_ SG_ 589 SWA_Obj_01_ID "ID des Objektes";
CM_ SG_ 589 SWA_Obj_01_Laenge "Lï?½nge des Objektes in Metern";
CM_ SG_ 589 SWA_Obj_01_Objektklasse "Gibt die Objektklasse an.\nUnbekannt: dynamisches oder statisches Objekt; alle nicht zu klassifizierenden nicht ï?½ber- oder unterfahrbaren Objekte, wie Spielzeug (z.B. Trettraktor) oder Sonderfahrzeuge (u.a. Trike, Quad, Straï?½enbahn, Rikschas, Kutschen)\nD";
CM_ SG_ 589 SWA_Obj_01_PositionX "Position des Objektes in x-Richtung (Referenzpunkt der 3D-Objektbox)";
CM_ SG_ 589 SWA_Obj_01_PositionY "Position des Objektes in y-Richtung (Referenzpunkt der 3D-Objektbox)";
CM_ SG_ 589 SWA_Obj_01_ReferenzPkt "Der Bezugspunkt eines detektierten Objektes zeigt den kï?½rzesten direkten Abstand zur Mitte der EGO-Vorderkante";
CM_ SG_ 589 SWA_Obj_02_Breite "Breite des Objektes in Metern";
CM_ SG_ 589 SWA_Obj_02_Existenzwahrsch "Existenzwahrscheinlichkeit des Objektes in Prozent";
CM_ SG_ 589 SWA_Obj_02_Gemessen "Status der PositionY des Objektes \n0 - ObjektpositionY_geschaetzt (Kalibrierung nicht abgeschlossen, hohe Entfernung, etc.)\n1 - ObjektpositionY_bestaetigt (Messung hinreichend genau)";
CM_ SG_ 589 SWA_Obj_02_GeschwRelX "Relative Geschwindigkeit in x (m/s)\nGeschwindigkeiten beziehen sich immer auf den Objektmittelpunkt\nMessung in Radialrichtung";
CM_ SG_ 589 SWA_Obj_02_GeschwRelY "Relative Geschwindigkeit in y (m/s)\nGeschwindigkeiten beziehen sich immer auf den Objektmittelpunkt";
CM_ SG_ 589 SWA_Obj_02_ID "ID des Objektes";
CM_ SG_ 589 SWA_Obj_02_Laenge "Lï?½nge des Objektes in Metern";
CM_ SG_ 589 SWA_Obj_02_Objektklasse "Gibt die Objektklasse an.\nUnbekannt: dynamisches oder statisches Objekt; alle nicht zu klassifizierenden nicht ï?½ber- oder unterfahrbaren Objekte, wie Spielzeug (z.B. Trettraktor) oder Sonderfahrzeuge (u.a. Trike, Quad, Straï?½enbahn, Rikschas, Kutschen)\nD";
CM_ SG_ 589 SWA_Obj_02_PositionX "Position des Objektes in x-Richtung (Referenzpunkt der 3D-Objektbox)";
CM_ SG_ 589 SWA_Obj_02_PositionY "Position des Objektes in y-Richtung (Referenzpunkt der 3D-Objektbox)";
CM_ SG_ 589 SWA_Obj_02_ReferenzPkt "Der Bezugspunkt eines detektierten Objektes zeigt den kï?½rzesten direkten Abstand zur Mitte der EGO-Vorderkante";
CM_ SG_ 589 SWA_Obj_03_Breite "Breite des Objektes in Metern";
CM_ SG_ 589 SWA_Obj_03_Existenzwahrsch "Existenzwahrscheinlichkeit des Objektes in Prozent";
CM_ SG_ 589 SWA_Obj_03_Gemessen "Status der PositionY des Objektes \n0 - ObjektpositionY_geschaetzt (Kalibrierung nicht abgeschlossen, hohe Entfernung, etc.)\n1 - ObjektpositionY_bestaetigt (Messung hinreichend genau)";
CM_ SG_ 589 SWA_Obj_03_GeschwRelX "Relative Geschwindigkeit in x (m/s)\nGeschwindigkeiten beziehen sich immer auf den Objektmittelpunkt\nMessung in Radialrichtung";
CM_ SG_ 589 SWA_Obj_03_GeschwRelY "Relative Geschwindigkeit in y (m/s)\nGeschwindigkeiten beziehen sich immer auf den Objektmittelpunkt";
CM_ SG_ 589 SWA_Obj_03_ID "ID des Objektes";
CM_ SG_ 589 SWA_Obj_03_Laenge "Lï?½nge des Objektes in Metern";
CM_ SG_ 589 SWA_Obj_03_Objektklasse "Gibt die Objektklasse an.\nUnbekannt: dynamisches oder statisches Objekt; alle nicht zu klassifizierenden nicht ï?½ber- oder unterfahrbaren Objekte, wie Spielzeug (z.B. Trettraktor) oder Sonderfahrzeuge (u.a. Trike, Quad, Straï?½enbahn, Rikschas, Kutschen)\nD";
CM_ SG_ 589 SWA_Obj_03_PositionX "Position des Objektes in x-Richtung (Referenzpunkt der 3D-Objektbox)";
CM_ SG_ 589 SWA_Obj_03_PositionY "Position des Objektes in y-Richtung (Referenzpunkt der 3D-Objektbox)";
CM_ SG_ 589 SWA_Obj_03_ReferenzPkt "Der Bezugspunkt eines detektierten Objektes zeigt den kï?½rzesten direkten Abstand zur Mitte der EGO-Vorderkante";
CM_ SG_ 589 SWA_Obj_04_Breite "Breite des Objektes in Metern";
CM_ SG_ 589 SWA_Obj_04_Existenzwahrsch "Existenzwahrscheinlichkeit des Objektes in Prozent";
CM_ SG_ 589 SWA_Obj_04_Gemessen "Status der PositionY des Objektes \n0 - ObjektpositionY_geschaetzt (Kalibrierung nicht abgeschlossen, hohe Entfernung, etc.)\n1 - ObjektpositionY_bestaetigt (Messung hinreichend genau)";
CM_ SG_ 589 SWA_Obj_04_GeschwRelX "Relative Geschwindigkeit in x (m/s)\nGeschwindigkeiten beziehen sich immer auf den Objektmittelpunkt\nMessung in Radialrichtung";
CM_ SG_ 589 SWA_Obj_04_GeschwRelY "Relative Geschwindigkeit in y (m/s)\nGeschwindigkeiten beziehen sich immer auf den Objektmittelpunkt";
CM_ SG_ 589 SWA_Obj_04_ID "ID des Objektes";
CM_ SG_ 589 SWA_Obj_04_Laenge "Lï?½nge des Objektes in Metern";
CM_ SG_ 589 SWA_Obj_04_Objektklasse "Gibt die Objektklasse an.\nUnbekannt: dynamisches oder statisches Objekt; alle nicht zu klassifizierenden nicht ï?½ber- oder unterfahrbaren Objekte, wie Spielzeug (z.B. Trettraktor) oder Sonderfahrzeuge (u.a. Trike, Quad, Straï?½enbahn, Rikschas, Kutschen)\nD";
CM_ SG_ 589 SWA_Obj_04_PositionX "Position des Objektes in x-Richtung (Referenzpunkt der 3D-Objektbox)";
CM_ SG_ 589 SWA_Obj_04_PositionY "Position des Objektes in y-Richtung (Referenzpunkt der 3D-Objektbox)";
CM_ SG_ 589 SWA_Obj_04_ReferenzPkt "Der Bezugspunkt eines detektierten Objektes zeigt den kï?½rzesten direkten Abstand zur Mitte der EGO-Vorderkante";
CM_ SG_ 589 SWA_Obj_05_Breite "Breite des Objektes in Metern";
CM_ SG_ 589 SWA_Obj_05_Existenzwahrsch "Existenzwahrscheinlichkeit des Objektes in Prozent";
CM_ SG_ 589 SWA_Obj_05_Gemessen "Status der PositionY des Objektes \n0 - ObjektpositionY_geschaetzt (Kalibrierung nicht abgeschlossen, hohe Entfernung, etc.)\n1 - ObjektpositionY_bestaetigt (Messung hinreichend genau)";
CM_ SG_ 589 SWA_Obj_05_GeschwRelX "Relative Geschwindigkeit in x (m/s)\nGeschwindigkeiten beziehen sich immer auf den Objektmittelpunkt\nMessung in Radialrichtung";
CM_ SG_ 589 SWA_Obj_05_GeschwRelY "Relative Geschwindigkeit in y (m/s)\nGeschwindigkeiten beziehen sich immer auf den Objektmittelpunkt";
CM_ SG_ 589 SWA_Obj_05_ID "ID des Objektes";
CM_ SG_ 589 SWA_Obj_05_Laenge "Lï?½nge des Objektes in Metern";
CM_ SG_ 589 SWA_Obj_05_Objektklasse "Gibt die Objektklasse an.\nUnbekannt: dynamisches oder statisches Objekt; alle nicht zu klassifizierenden nicht ï?½ber- oder unterfahrbaren Objekte, wie Spielzeug (z.B. Trettraktor) oder Sonderfahrzeuge (u.a. Trike, Quad, Straï?½enbahn, Rikschas, Kutschen)\nD";
CM_ SG_ 589 SWA_Obj_05_PositionX "Position des Objektes in x-Richtung (Referenzpunkt der 3D-Objektbox)";
CM_ SG_ 589 SWA_Obj_05_PositionY "Position des Objektes in y-Richtung (Referenzpunkt der 3D-Objektbox)";
CM_ SG_ 589 SWA_Obj_05_ReferenzPkt "Der Bezugspunkt eines detektierten Objektes zeigt den kï?½rzesten direkten Abstand zur Mitte der EGO-Vorderkante";
CM_ SG_ 589 SWA_Obj_06_Breite "Breite des Objektes in Metern";
CM_ SG_ 589 SWA_Obj_06_Existenzwahrsch "Existenzwahrscheinlichkeit des Objektes in Prozent";
CM_ SG_ 589 SWA_Obj_06_Gemessen "Status der PositionY des Objektes \n0 - ObjektpositionY_geschaetzt (Kalibrierung nicht abgeschlossen, hohe Entfernung, etc.)\n1 - ObjektpositionY_bestaetigt (Messung hinreichend genau)";
CM_ SG_ 589 SWA_Obj_06_GeschwRelX "Relative Geschwindigkeit in x (m/s)\nGeschwindigkeiten beziehen sich immer auf den Objektmittelpunkt\nMessung in Radialrichtung";
CM_ SG_ 589 SWA_Obj_06_GeschwRelY "Relative Geschwindigkeit in y (m/s)\nGeschwindigkeiten beziehen sich immer auf den Objektmittelpunkt";
CM_ SG_ 589 SWA_Obj_06_ID "ID des Objektes";
CM_ SG_ 589 SWA_Obj_06_Laenge "Lï?½nge des Objektes in Metern";
CM_ SG_ 589 SWA_Obj_06_Objektklasse "Gibt die Objektklasse an.\nUnbekannt: dynamisches oder statisches Objekt; alle nicht zu klassifizierenden nicht ï?½ber- oder unterfahrbaren Objekte, wie Spielzeug (z.B. Trettraktor) oder Sonderfahrzeuge (u.a. Trike, Quad, Straï?½enbahn, Rikschas, Kutschen)\nD";
CM_ SG_ 589 SWA_Obj_06_PositionX "Position des Objektes in x-Richtung (Referenzpunkt der 3D-Objektbox)";
CM_ SG_ 589 SWA_Obj_06_PositionY "Position des Objektes in y-Richtung (Referenzpunkt der 3D-Objektbox)";
CM_ SG_ 589 SWA_Obj_06_ReferenzPkt "Der Bezugspunkt eines detektierten Objektes zeigt den kï?½rzesten direkten Abstand zur Mitte der EGO-Vorderkante";
CM_ SG_ 589 SWA_Obj_Kurvenradius "Kurvenradius ermittelt aus dem zurï?½ckgelegten Streckenverlauf in Metern. Die aktuelle Berechnungsgrundlage fï?½r die kurvenbereinigte PositionY der ausgegebenen Objekte.";
CM_ SG_ 589 SWA_StrukturLinks_querAbstand "Abstand zur Randbebauung auf der entsprechenden Fahrzeugseite bezogen auf die Mitte der Hinterachse von dem Ego-Fahrzeug.";
CM_ SG_ 589 SWA_StrukturLinks_Typ "Typ der vom Heckradar erkannten Randbebauung";
CM_ SG_ 589 SWA_StrukturRechts_querAbstand "Abstand zur Randbebauung auf der entsprechenden Fahrzeugseite bezogen auf die Mitte der Hinterachse von dem Ego-Fahrzeug.";
CM_ SG_ 589 SWA_StrukturRechts_Typ "Typ der vom Heckradar erkannten Randbebauung";
CM_ SG_ 589 SWA_Umfeld_Zeitstempel "Das Signal beschreibt den Messzeitpunkt zu dem die Messdaten erfasst worden sind in Sekunden.";
CM_ SG_ 589 SWA_Umfeld_Zeitstempel_Status "Das Signal beschreibt die Art der Zeitsynchonisierung und ggf. die Fehlerursache bei fehlender Zeitstempelausgabe.";
CM_ SG_ 589 SWA_Warnung_SWA_li "Aktion der SWA-Funktion auf der entsprechenden Fahrzeugseite";
CM_ SG_ 589 SWA_Warnung_SWA_re "Aktion der SWA-Funktion auf der entsprechenden Fahrzeugseite";
CM_ SG_ 2635073907 HID_DispKBI_FS_ZR_Req_FD_Data "Human Interface Device Kommunikation ï?½ber ISO TP (CAN FD)\nzw. i.ID und ICAS3";
CM_ SG_ 2635204979 HID_DispKBI_FS_ZR_Resp_FD_Data "Human Interface Device Kommunikation ï?½ber ISO TP (CAN FD)\nzw. i.ID und ICAS3";
CM_ SG_ 2634029939 HID_HUD_ZR_Req_FD_Data "Human Interface Device Kommunikation ï?½ber ISO TP (CAN FD)\nzw. HUD und ICAS3";
CM_ SG_ 2634161011 HID_HUD_ZR_Resp_FD_Data "Human Interface Device Kommunikation ï?½ber ISO TP (CAN FD)\nzw. HUD und ICAS3";
CM_ SG_ 2634314505 HID_ZR_DispKBI_FS_Req_FD_Data "Human Interface Device Kommunikation ï?½ber ISO TP (CAN FD)\nzw. i.ID und ICAS3";
CM_ SG_ 2634445577 HID_ZR_DispKBI_FS_Resp_FD_Data "Human Interface Device Kommunikation ï?½ber ISO TP (CAN FD)\nzw. i.ID und ICAS3";
CM_ SG_ 2634052379 HID_ZR_HUD_Req_FD_Data "Human Interface Device Kommunikation ï?½ber ISO TP (CAN FD)\nzw. HUD und ICAS3";
CM_ SG_ 2634183451 HID_ZR_HUD_Resp_FD_Data "Human Interface Device Kommunikation ï?½ber ISO TP (CAN FD)\nzw. HUD und ICAS3";
CM_ SG_ 2629835579 HUD_ARC_Req_FD_Data "Knoten HUD (NA 0x1B) ISO-TP Request an AR-Creator (Funktionsblock mit FID 0x3B) \n- Anfrage von Daten\n\nUseCases (Datenaustausch):\n- Exchange of warpingmatrix between ZR and HUD over CAN.";
CM_ SG_ 2629966651 HUD_ARC_Resp_FD_Data "AR-Creator (Funktionsblock mit FID 0x3B) ISO-TP Response an Knoten HUD (NA 0x1B)\n- Ausgabe von Daten gemï?½ï?½ Anfrage\n\nUseCases (Datenaustausch):\n- Exchange of warpingmatrix between ZR and HUD over CAN.";
CM_ SG_ 1283 HV_Bordnetz_aktiv "Signalisiert ein aktives Hochvoltbordnetz. Fï?½r die Belastbarkeit des HV-Netzes mï?½ssen Strom- bzw. Leistungsgrenzen eingehalten werden";
CM_ SG_ 1283 HV_Bordnetz_Fehler "Status ob im  HV-Netz ein Fehler detektiert wurde.";
CM_ SG_ 1283 HVK_01_CRC "Fï?½r MLB:\n'Berechnung siehe Lastenheft 'Kommunikationsabsicherung fï?½r FlexRay und CAN''\n\nAb MQB und MLBevo:\n'Berechnung siehe Lastenheft 'End-to-End Kommunikationsabsicherung''\n\nEndwerte siehe Begleitdokument 'S-PDU Kennungsfolgen'";
CM_ SG_ 1283 HVK_AktiveEntladung_Anf "Anforderung zum aktiven Entladen des HV-Netzes, wï?½hrend der Abschaltung des HV-Netz.";
CM_ SG_ 1283 HVK_BMS_Sollmodus "Angeforderter Sollmodus der HV-Batterie:\n0 : HV_Off                                \n1 : HV_On (HS geschlossen)                \n2 : nicht belegbar                        \n3 : AC-Laden_erw (HS +AC_2-Schï?½tze geschlossen)                         \n4 : AC-";
CM_ SG_ 1283 HVK_DCDC_Sollmodus "angeforderte Soll-Betriebsart des DC/DC-Wandlers: \n0: Standby; Kommunikation aktiv\n1: Zwischenkreis des HV-Netzes wird vorgeladen; HV-Netz wird aktiviert und darf nicht  \nbelastet werden.\n2: Tiefsetzen (HV --> BN 14,4V)\nSollwertvorgabe projek";
CM_ SG_ 1283 HVK_EKK_Sollmodus "Sollmodus elektrischer Klimakompressor";
CM_ SG_ 1283 HVK_Gesamtst_Spgfreiheit "Status des HV-Systems";
CM_ SG_ 1283 HVK_HV_Netz_Warnungen "Anforderung Warnung/Fehler HV-System im Kombi\n0: Keine Warnung/Init\n1:Anforderung_Anzeige_Warnung_HV-Netz (gelbes Symbol)\n2:Anforderung_Anzeige_Fehler_HV-Netz (rotes Symbol)\n3:Anforderung_Anzeige_Warnung_Kein_Wiederstart_mï?½glich";
CM_ SG_ 1283 HVK_HVEM_Freigabe "Der HVK gibt das HVEM frei, um das HV-Netz unter Einhaltung von Leistungsgrenzen in Anspruch zu nehmen.";
CM_ SG_ 1283 HVK_HVLM_Sollmodus "Angeforderter Sollmodus des Lademanagers.";
CM_ SG_ 1283 HVK_HVPTC_Sollmodus "Sollmodus HV-PTC\n0 : keine Freigabe\n1 : Freigabe\n2 : Freigabe_ausgesetzt\n3 : nicht belegbar\n4 : nicht belegbar\n5 : nicht belegbar\n6 : nicht belegbar\n7 : Init   (CAN-Initialisierung)   \n\nInfo: 'nicht belegbar' d.h. Sollmodus nicht relevant fï?½r HV";
CM_ SG_ 1283 HVK_Iso_Messung_Start "Anforderung an die isolationswiderstandsï?½berwachenden HV-Komponenten zur Durchfï?½hrung der Isolations-Widerstandsmessung.";
CM_ SG_ 1283 HVK_Istmodus_Anf "HVK-Anforderung an alle HV-Komponenten deren Istmodus im schnellen Zyklus (Inhibitzeit) zu senden.";
CM_ SG_ 1283 HVK_Ladebereit "Information an das Lademanagement, dass das HV-System aus Sicht des HVKs bereitgestellt werden kann.";
CM_ SG_ 1283 HVK_Notabschaltung_Anf "Aufforderung zur schnellstmï?½glichen Abschaltung des HV-Netzes aufgrund HV-Sicherheit";
CM_ SG_ 1283 HVK_PPulsFreigabe "Prï?½fpuls-Freigabe seitens Hochvoltkoordinator";
CM_ SG_ 1283 HVK_TN1_Sollmodus "Angeforderter Sollmodus der Steuereinheit fï?½r das Schï?½tze des Teilnetz1 'Ladepfad':\n0 : HV_Off                                \n1 : HV_On (Schï?½tz geschlossen)                \n2 : reserviert\n3 : Init   (CAN-Initialisierung)";
CM_ SG_ 1283 HVK_Vorladung_aktiv "Systeminformation, dass aktiv vorgeladen wird";
CM_ SG_ 2527679583 FoD_DTC_IPA_EPH "Function on Demand DTC for IPA from EPH to Function Master";
CM_ SG_ 2527679583 FoD_DTC_RPA_EPH "Function on Demand DTC for RPA from EPH to Function Master";
CM_ SG_ 2527679583 FoD_DTC_TPA_rTPA_EPH "Function on Demand DTC for TPA and rTPA from EPH to Function Master";
CM_ SG_ 2527679583 IPA_02_BZ "4bit Botschaftszï?½hler, wird mit jeder Sendebotschaft inkrementiert";
CM_ SG_ 2527679583 IPA_02_CRC "Fï?½r MLB:\nBerechnung siehe Lastenheft 'Kommunikationsabsicherung fï?½r FlexRay und CAN'\nAb MQB und MLBevo:\nBerechnung siehe Lastenheft 'End-to-End Kommunikationsabsicherung'\n\nEndwerte siehe Begleitdokument 'S-PDU Kennungsfolgen'";
CM_ SG_ 2527679583 IPA_Anf_Meldungen "Das Signal fordert die Anzeige einer Meldung an. Jedem Signalwert ist eine Meldung zugeordnet. Das Signal ist derzeit fï?½r die Funktionen IPA/RPA und TPA implementiert.";
CM_ SG_ 2527679583 Parken_aktives_System_02 "zeigt an welches parkendes System aktiv ist";
CM_ SG_ 2527679583 Parken_Aktivierungslicht_Anf "Anforderung des Aktivierungslichts nach erfolgreicher Aktivierungshandlung seitens Pilotiertem Parken.";
CM_ SG_ 2527679583 Parken_Bestaetigungsblinken_Anf "Anforderung seitens Pilotiertem Parken fï?½r ein Erfolgsblinken nach dem Erreichen der Zielposition bzw. fï?½r ein Abbruchsblinken bei Eintreten einer Abbruchsbedingung.";
CM_ SG_ 2527679583 Parken_Fahrbereitschaftlicht_Anf "Anforderung des Fahrbereitschaftslichts";
CM_ SG_ 2527679583 Parken_Fahrerhinweise_Anf "Anforderung zur erneuten Lampenaufprï?½fung und Anzeige von Warnhinweisen nach einem pilotierten Ausparkvorgang.";
CM_ SG_ 2527679583 Parken_Fahrtrichtungslicht_Anf "Anforderung seitens Pilotiertem Parken fï?½r die Anzeige der initialen Fahrtrichtung nach Systemaktivierung.";
CM_ SG_ 2527679583 Parken_FFB_LED_Anf "Statusinformation des Pilotierten Parkens fï?½r die Ansteuerung der LED auf der Funkfernbedienung.";
CM_ SG_ 2527679583 Parken_Lichtnachlauf_Anf "Anforderung des Lichtnachlaufs beim BCM1 (analog Verlassenskonzept) fï?½r das Pilotierte Parken. ";
CM_ SG_ 2527679583 Parken_Lichtsteuerung_Anf "Anforderung zum Setzen des Lichtmodus des Fahrzeuges von der Parkfunktion";
CM_ SG_ 2527679583 Parken_Schluesselsuche_Anf "Ansteuerung der Schlï?½sselsuche fï?½r das pilotierte Parken.";
CM_ SG_ 2527679583 Parken_Seitenspiegel_Anf "Anforderung fï?½r Seitenspiegel an- oder abklappen beim PiloPa";
CM_ SG_ 2527679583 Parken_Wegfahrsperren_Anf "Ansteuerung der Wegfahrsperren Komponenten fï?½r das pilotierte Parken.  ";
CM_ SG_ 2527679583 Parken_ZR_Sondermodus_Anf "Anforderung Sondermodus, um beim ï?½pilotierten Parkenï?½ spezielle Funktionsanpassungen im Infotainment-Bereich zu ermï?½glichen (u.a. schnellerer Startup, Abschaltung BT)";
CM_ SG_ 2527679583 Parken_ZV_Schliessen "Anforderung fï?½r Zentralverriegelung verriegeln oder safen beim PiloPa";
CM_ SG_ 2527679583 RA_Anf_Meldung "Das Signal fordert die Anzeige einer Meldung an. Jedem Signalwert ist eine Meldung zugeordnet. Das Signal ist derzeit fï?½r die Funktionsrealisierung RA implementiert.";
CM_ SG_ 1792 ISO_ALL_01_Req_Data "Funktionaler Request ALL";
CM_ SG_ 1819 ISO_HUD_Req_Data "OffBoard Tester Diagnose Request HUD";
CM_ SG_ 1925 ISO_HUD_Resp_Data "OffBoard Tester Diagnose Response HUD";
CM_ SG_ 1812 ISO_Kombi_Req_Data "Diagnose Request Kombiinstrument";
CM_ SG_ 1918 ISO_Kombi_Resp_Data "Diagnose Response Kombiinstrument";
CM_ SG_ 2549358366 ISO_NFCIApp_NFCIServ_Req_Data "Near Field Communication Infotainment\nISO-TP Datenkanal - FID2FID\nRequest Funktion 0x1F NFCIApp an Funktion 0x1E NFCIServ\nNFC Infotainment Applikation -> NFC Infotainment Server";
CM_ SG_ 2549489183 ISO_NFCIApp_NFCIServ_Resp_Data "Near Field Communication Infotainment\nISO-TP Datenkanal - FID2FID\nResponse Funktion 0x1E NFCIServ an Funktion 0x1F NFCIApp\nNFC Infotainment Server -> NFC Infotainment Applikation";
CM_ SG_ 2549358111 ISO_NFCIServ_NFCIApp_Req_Data "Near Field Communication Infotainment\nISO-TP Datenkanal - FID2FID\nRequest Funktion 0x1E NFCIServ an Funktion 0x1F NFCIApp\nNFC Infotainment Server -> NFC Infotainment Applikation";
CM_ SG_ 2549489438 ISO_NFCIServ_NFCIApp_Resp_Data "Near Field Communication Infotainment\nISO-TP Datenkanal - FID2FID\nResponse Funktion 0x1F NFCIApp an Funktion 0x1E NFCIServ\nNFC Infotainment Applikation -> NFC Infotainment Server";
CM_ SG_ 1901 ISO_TV_Tuner_Req_Data "Diagnose Request TV-Tuner";
CM_ SG_ 2007 ISO_TV_Tuner_Resp_Data "Diagnose Response TV-Tuner";
CM_ SG_ 2550398985 ISOx_DispKBI_FS_Req_Data "OffBoard Tester Diagnose Request DispKBI_FS";
CM_ SG_ 2621702153 ISOx_DispKBI_FS_Req_FD_Data "OffBoard Tester Diagnose Response DispKBI_FS";
CM_ SG_ 2550530057 ISOx_DispKBI_FS_Resp_Data "Diagnose Response DispKBI_FS";
CM_ SG_ 2621833225 ISOx_DispKBI_FS_Resp_FD_Data "OffBoard Tester Diagnose Response DispKBI_FS";
CM_ SG_ 2621505536 ISOx_Funkt_Req_All_FD_Data "OffBoard Tester funktionaler Diagnose Request ALL CANFD";
CM_ SG_ 2621440027 ISOx_HUD_Req_FD_Data "OffBoard Tester Diagnose Response HUD";
CM_ SG_ 2621571099 ISOx_HUD_Resp_FD_Data "OffBoard Tester Diagnose Response HUD";
CM_ SG_ 2621440020 ISOx_Kombi_Req_FD_Data "Diagnose Request FD Kombi";
CM_ SG_ 2621571092 ISOx_Kombi_Resp_FD_Data "Diagnose Response FD Kombi";
CM_ SG_ 2550398988 ISOx_SmLi_01_Req_Data "Diagnose Request";
CM_ SG_ 2621702156 ISOx_SmLi_01_Req_FD_Data "OffBoard Tester Diagnose Response SmLi_01";
CM_ SG_ 2550530060 ISOx_SmLi_01_Resp_Data "OffBoard Tester Diagnose Response SmLi_01";
CM_ SG_ 2621833228 ISOx_SmLi_01_Resp_FD_Data "OffBoard Tester Diagnose Response SmLi_01";
CM_ SG_ 2549874853 ISOx_WLC1_Req_Data "OffBoard Tester Diagnose Request WLC1";
CM_ SG_ 2550005925 ISOx_WLC1_Resp_Data "OffBoard Tester Diagnose Response WLC1";
CM_ SG_ 1426 KY_Aktive_LFScans "Signalisierung eines aktiven Kessy-Scans (LF auf 125kHz) mit Angabe der Scanart";
CM_ SG_ 1426 KY_AnzKoord_Info "Signalisierung, ob beim Kessy-Scan ein Schlï?½ssel gefunden wurde (1) oder nicht (2)";
CM_ SG_ 1426 KY_EasyClose_Abbruch "ID-Geber wï?½hrend HD-Zufahrt im Nahbereich EasyClose erkannt";
CM_ SG_ 1426 KY_EasyClose_Status "Signal zur LED Ansteuerung im HD-Verriegelungstaster fï?½r die Funktion EasyClose.";
CM_ SG_ 1426 KY_Fzg_Verlassen_erkannt "Fahrer/Schlï?½ssel hat das Fahrzeug verlassen und FT wurde geschlossen";
CM_ SG_ 1426 KY_Fzg_Zugang_erkannt "Fahrer/Schlï?½ssel hat Fahrzeug betreten und die FT geschlossen";
CM_ SG_ 1426 KY_Gestik_HD "Aktive Funktion (Gestikgesteuerte Heckklappe) im Kessy-SG";
CM_ SG_ 1426 KY_Gong_600 "Gong zum Meldungstext (1=aktiv)";
CM_ SG_ 1426 KY_HD_Auffahrt "Auffahrt HD nach Wiedereintritt ID-Geber in EasyClose Nahbereich";
CM_ SG_ 1426 KY_HD_Zufahrt "Zufahrt HD nach erfolgreicher Funktion EasyClose";
CM_ SG_ 1426 KY_ID_Geber1_im_Fzg "1 = ID-Geber 1 im Innenraum erkannt";
CM_ SG_ 1426 KY_ID_Geber2_im_Fzg "1 = ID-Geber 2 im Innenraum erkannt";
CM_ SG_ 1426 KY_ID_Geber3_im_Fzg "1 = ID-Geber 3 im Innenraum erkannt";
CM_ SG_ 1426 KY_ID_Geber4_im_Fzg "1 = ID-Geber 4 im Innenraum erkannt";
CM_ SG_ 1426 KY_ID_Geber_Suche "1 = Transponder Scan aktiv";
CM_ SG_ 1426 KY_LF_Aktiv "LF Schluesselkommunikation\n";
CM_ SG_ 1426 KY_Meldungen "Kessy-Meldungen:\n0 = keine Meldung\n1 = Meldung: 'Schlï?½ssel nicht gefunden!' bei Kl.15 ein\n2= Meldung: 'Schlï?½ssel im Kofferraum!'\n3 = Meldung: 'Schlï?½ssel im Fahrzeug'\n4 = Meldung: 'KESSY defekt'\n5-15: tbd";
CM_ SG_ 1426 KY_Passiv_Autolock "Aktive Funktion (Passiv Autolock) im Kessy-SG";
CM_ SG_ 1426 KY_Passiv_Autolock_Akt "1 = Funktionszustand im Kessy-SG: 'Passiv Autolock / Autounlock'";
CM_ SG_ 1426 KY_Passiv_Autolock_Menue "1 = Menue-Eintrag 'Passiv Autolock / Autounlock' aktivieren";
CM_ SG_ 1426 KY_Passiv_Autounlock "Aktive Funktion (Passiv Autounlock) im Kessy-SG";
CM_ SG_ 1426 KY_Schluesselposition_1 "Status des ID-Gebers 1 aus der letzten durchgefï?½hrten Schlï?½sselsuche fï?½r Remote Parkfunktionen\n\n0 = nicht_gefunden\n1 = im_Innenraum_gefunden\n2 = im_Auï?½enraum_gefunden_nah, Distanz <= parametrierter Schwelle\n3 = im_Auï?½enraum_gefunden_fern, Distanz > p";
CM_ SG_ 1426 KY_Schluesselposition_2 "Status des ID-Gebers 2 aus der letzten durchgefï?½hrten Schlï?½sselsuche fï?½r Remote Parkfunktionen\n\n0 = nicht_gefunden\n1 = im_Innenraum_gefunden\n2 = im_Auï?½enraum_gefunden_nah, Distanz <= parametrierter Schwelle\n3 = im_Auï?½enraum_gefunden_fern, Distanz > p";
CM_ SG_ 1426 KY_Schluesselposition_3 "Status des ID-Gebers 3 aus der letzten durchgefï?½hrten Schlï?½sselsuche fï?½r Remote Parkfunktionen\n\n0 = nicht_gefunden\n1 = im_Innenraum_gefunden\n2 = im_Auï?½enraum_gefunden_nah, Distanz <= parametrierter Schwelle\n3 = im_Auï?½enraum_gefunden_fern, Distanz > p";
CM_ SG_ 1426 KY_Schluesselposition_4 "Status des ID-Gebers 4 aus der letzten durchgefï?½hrten Schlï?½sselsuche fï?½r Remote Parkfunktionen\n\n0 = nicht_gefunden\n1 = im_Innenraum_gefunden\n2 = im_Auï?½enraum_gefunden_nah, Distanz <= parametrierter Schwelle\n3 = im_Auï?½enraum_gefunden_fern, Distanz > p";
CM_ SG_ 1426 KY_Schluesselposition_5 "Status des ID-Gebers 5 aus der letzten durchgefï?½hrten Schlï?½sselsuche fï?½r Remote Parkfunktionen\n\n0 = nicht_gefunden\n1 = im_Innenraum_gefunden\n2 = im_Auï?½enraum_gefunden_nah, Distanz <= parametrierter Schwelle\n3 = im_Auï?½enraum_gefunden_fern, Distanz > p";
CM_ SG_ 1426 KY_Schluesselposition_6 "Status des ID-Gebers 6 aus der letzten durchgefï?½hrten Schlï?½sselsuche fï?½r Remote Parkfunktionen\n\n0 = nicht_gefunden\n1 = im_Innenraum_gefunden\n2 = im_Auï?½enraum_gefunden_nah, Distanz <= parametrierter Schwelle\n3 = im_Auï?½enraum_gefunden_fern, Distanz > p";
CM_ SG_ 1426 KY_Schluesselposition_7 "Status des ID-Gebers 7 aus der letzten durchgefï?½hrten Schlï?½sselsuche fï?½r Remote Parkfunktionen\n\n0 = nicht_gefunden\n1 = im_Innenraum_gefunden\n2 = im_Auï?½enraum_gefunden_nah, Distanz <= parametrierter Schwelle\n3 = im_Auï?½enraum_gefunden_fern, Distanz > p";
CM_ SG_ 1426 KY_Schluesselposition_8 "Status des ID-Gebers 8 aus der letzten durchgefï?½hrten Schlï?½sselsuche fï?½r Remote Parkfunktionen\n\n0 = nicht_gefunden\n1 = im_Innenraum_gefunden\n2 = im_Auï?½enraum_gefunden_nah, Distanz <= parametrierter Schwelle\n3 = im_Auï?½enraum_gefunden_fern, Distanz > p";
CM_ SG_ 1426 KY_Schluesselposition_9 "Status des ID-Gebers 9 (MDK) aus der letzten durchgefï?½hrten Schlï?½sselsuche fï?½r Remote Parkfunktionen\n\n0 = nicht_gefunden\n1 = im_Innenraum_gefunden\n2 = im_Auï?½enraum_gefunden_nah, Distanz <= parametrierter Schwelle\n3 = im_Auï?½enraum_gefunden_fern, Dista";
CM_ SG_ 1426 KY_Startknopf_Bel "Startknopf beleuchten";
CM_ SG_ 1426 KY_StartStopp_Info "Stopp-Freigabe und Start-Anforderung an den Start-Stopp-Koordinator";
CM_ SG_ 960 BCM_Ausparken_Betrieb "Anforderung zur erneuten Lampenaufprï?½fung und Anzeige von Warnhinweisen nach einem pilotierten Ausparkvorgang (Trigger: fallende Flanke)";
CM_ SG_ 960 Klemmen_Status_01_BZ "4bit Botschaftszaehler; wird in jeder Sendebotschaft inkrementiert";
CM_ SG_ 960 Klemmen_Status_01_CRC "Fï?½r MLB:\n'Berechnung siehe Lastenheft 'Kommunikationsabsicherung fï?½r FlexRay und CAN''\n\nAb MQB und MLBevo:\n'Berechnung siehe Lastenheft 'End-to-End Kommunikationsabsicherung''\n\nEndwerte siehe Begleitdokument 'S-PDU Kennungsfolgen'";
CM_ SG_ 960 KST_Fahrerhinweis_1 "Signalisierung Fahrerhinweis 1 der Klemmensteuerung an das Kombi";
CM_ SG_ 960 KST_Fahrerhinweis_2 "Signalisierung Fahrerhinweis 2 der Klemmensteuerung an das Kombi";
CM_ SG_ 960 KST_Fahrerhinweis_4 "Signalisierung Fahrerhinweis 4 der Klemmensteuerung an das Kombi";
CM_ SG_ 960 KST_Fahrerhinweis_5 "Anzeigesignal fï?½r RemoteStart";
CM_ SG_ 960 KST_Fahrerhinweis_6 "Signal aktiviert die Kombi-Anzeigeinstrumente (Drehzahl, Tankinhalt, Kï?½hlmitteltemperatur) wï?½hrend aktiviertem RemoteStart-Betrieb";
CM_ SG_ 960 KST_Warn_P1_ZST_def "Kombi Prio Warnung Klemmensteuerung \nZï?½ndschloï?½ defekt, Service aufsuchen!";
CM_ SG_ 960 KST_Warn_P2_ZST_def "Kombi Prio Warnung Klemmensteuerung\nZï?½ndschloï?½ defekt!\n";
CM_ SG_ 960 RSt_Fahrerhinweise "ï?½ber das Signal fordert das BCM Fahrerhinweise im Kombi fï?½r die Funktion RemoteStart an.";
CM_ SG_ 960 ZAS_Kl_15 "Klemme 15: Zuendung (SW-Kl.15)\n";
CM_ SG_ 960 ZAS_Kl_50_Startanforderung "Klemme 50: Startwunsch Fahrer\n";
CM_ SG_ 960 ZAS_Kl_Infotainment "Separate Klemmeninformation fï?½r das Infotainment. Signal entspricht im wesentlichen einer Klemme S Information, kann aber ï?½ber einen Vor - bzw. Nachlauf zu Klemme S verfï?½gen. \nEin konkreter Anwendungsfall fï?½r einen Nachlauf ist die Abschaltung der Klemme";
CM_ SG_ 960 ZAS_Kl_S "Klemme S: S-Kontakt (Schluessel steckt)\n";
CM_ SG_ 960 ZAS_Kl_X "Klemme 75\n";
CM_ SG_ 2463978753 Klemmen_Status_02_BZ "4bit Botschaftszï?½hler, wird mit jeder Sendebotschaft inkrementiert";
CM_ SG_ 2463978753 Klemmen_Status_02_CRC "Fï?½r MLB:\nBerechnung siehe Lastenheft 'Kommunikationsabsicherung fï?½r FlexRay und CAN'\nAb MQB und MLBevo:\nBerechnung siehe Lastenheft 'End-to-End Kommunikationsabsicherung'\n\nEndwerte siehe Begleitdokument 'S-PDU Kennungsfolgen'";
CM_ SG_ 2463978753 KST_ComfortReadyStatus "Zustand des ComfortReadyStatus ï?½ber den Komfortfunktionen aktiviert werden kï?½nnen.";
CM_ SG_ 2463978753 KST_Sonderzustand_Anforderung "Hiermit wird die aktive bzw. aktuell angeforderte (s. KST_Sonderzustand_Status) Sonderfunktion identifiziert";
CM_ SG_ 2463978753 KST_Sonderzustand_Status "Hiermit wird signalisiert, dass eine Sonderfunktion aktiv ist und die Klemme 15 durch diese angefordert wurde bzw. ein ï?½bergang von Sonderfunktionen stattfindet";
CM_ SG_ 2463978753 KST_WFS_Fahrfreigabe_Anforderung "Hiermit wird den Wegfahrsperren-Teilnehmern signalisiert welche Art der Fahrfreigabe von der anfordernden Sonderfunktion benï?½tigt wird";
CM_ SG_ 1420 Klemmen_Steuerung_01_BZ "4bit Botschaftszaehler; wird in jeder Sendebotschaft inkrementiert";
CM_ SG_ 1420 Klemmen_Steuerung_01_CRC "Ab MQB und MLBevo:\n'Berechnung siehe Lastenheft 'End-to-End Kommunikationsabsicherung''\n\nEndwerte siehe Begleitdokument 'S-PDU Kennungsfolgen'";
CM_ SG_ 1420 KST_Anf_Klemme_15 "Anforderung der Klemme 15 an das BCM. Signal wird zur Plausibilisierung parallel zum Klemmensignal auf dem CAN ï?½bertragen.";
CM_ SG_ 1420 KST_Anf_Klemme_50 "Anforderung der Klemme 50 an das MSG. Signal wird zur Plausibilisierung parallel zum Klemmensignal auf dem CAN ï?½bertragen.";
CM_ SG_ 1420 KST_Anf_Klemme_S "Anforderung der Klemme S an das BCM. Signal wird zur Plausibilisierung parallel zum Klemmensignal auf dem CAN ï?½bertragen.";
CM_ SG_ 1420 KST_Anf_Klemmenfreigabe_ELV "Klemmensteuerung fordert Klemmen-Freigabe durch die ELV an.";
CM_ SG_ 1420 KST_Anf_Klemmenfreigabe_WFS "Anforderung der Freigabe von der WFS zum Einschalten von Klemme 15 und Klemme S";
CM_ SG_ 1420 KST_Anf_ZV_Verriegelung "Neuer Verriegelungstrigger fï?½r die ZV nach der automatischen Klemmenabschaltung.\n\nWird bei Kessyfahrzeugen mit StartStop ein aktiver Stop-Mode und Fahrerverlassen erkannt, startet ein 30 Sekunden-Timer. Innerhalb dieser 30 Sekunden hat der Fahrer die Mï?½";
CM_ SG_ 1420 KST_aut_Abschaltung_Zuendung "Falls bei eingeschalteter Zï?½ndung das Abblendlicht aktiv war, muss nach der automatischen Abschaltung der Kl_15 & Kl_S, dass Standlicht aktiv bleiben. Das Signal sendet die Information, dass eine automatische Abschaltung der Kl_15 und Kl_S erfogt.";
CM_ SG_ 1420 KST_Fahrer_Info_Text "Hinweise fï?½r den Fahrer fï?½r die Fahrzeugaktivierung / -deaktivierung";
CM_ SG_ 1420 KST_KL15LockStatus "KST_KL15LockStatus";
CM_ SG_ 1420 KST_Txt_Komfortabschaltung "Dieses Signal fordert im Kombi die Meldung an, die den Fahrer ï?½ber die ausgefï?½hrte automatische Zï?½ndungsabschaltung informiert. Signal wird fï?½r10s gesendet.";
CM_ SG_ 1420 KST_Txt_P_Gang "Text: 'Wï?½hlhebel in Position P bringen!'";
CM_ SG_ 1420 KST_Txt_Panikabschaltung "Text: 'Notabschaltung''";
CM_ SG_ 1420 KST_Txt_Werkstatt "Text: 'Klemmensteuerung! Werkstatt!'";
CM_ SG_ 1420 KST_Unterdr_Zuendungsmeldung "Bei aktivem Signal soll die Zï?½ndungsmeldung durch das Kombi unterdrï?½ckt werden.";
CM_ SG_ 1420 KST_ZAT_betaetigt "Zï?½ndanlass-Taster (ZAT) betï?½tigt";
CM_ SG_ 1420 KST_Zuendungswarnung "Bei aktivem Signal soll je nach gesetztem Status eine Warnung durch das Kombi ausgegeben werden";
CM_ SG_ 1420 Relais_VoKo_angesteuert "Signal zur Rï?½ckmeldung, ob das Relais fï?½r die Verbraucher von erweiterte Voko / RemoteStart angesteuert wird.";
CM_ SG_ 1420 RSt_Anforderung_HMS "Anforderung vom RSt (Remote Start) an das HMS (Haltemanagement System)";
BA_DEF_ BO_ "CANFD_BRS" ENUM "0", "1";
BA_DEF_ BO_ "DiagRequest" ENUM "No", "Yes";
BA_DEF_ BO_ "DiagResponse" ENUM "No", "Yes";
BA_DEF_ BO_ "DiagState" ENUM "No", "Yes";
BA_DEF_ BO_ "GenMsgChkConstant" HEX 0 4095;
BA_DEF_ BO_ "GenMsgCycleTime" INT 0 65535;
BA_DEF_ BO_ "GenMsgCycleTimeFast" INT 0 65535;
BA_DEF_ BO_ "GenMsgDelayTime" INT 0 100000;
BA_DEF_ BO_ "GenMsgILSupport" ENUM "No", "Yes";
BA_DEF_ BO_ "GenMsgNrOfRepetition" INT 0 100;
BA_DEF_ BO_ "GenMsgPDUConstants" STRING;
BA_DEF_ BO_ "GenMsgSendType" ENUM "Cyclic", "not_used", "not_used", "not_used", "not_used", "not_used", "not_used", "IfActive", "NoMsgSendType";
BA_DEF_ BO_ "GenMsgStartDelayTime" INT 0 100000;
BA_DEF_ BO_ "MsgType" ENUM "Application", "NM ", "NMH", "TP2.0", "ISO-TP ", "BAP", "EID", "KS", "XCP_PRE_CONFIGURED", "XCP_RUNTIME_CONFIGURED";
BA_DEF_ BO_ "NmMessage" ENUM "No", "Yes";
BA_DEF_ BO_ "NmhMessage" ENUM "No", "Yes";
BA_DEF_ BO_ "VAGTP20_API" HEX 0 255;
BA_DEF_ BO_ "VAGTP20_DynConnection" ENUM "No", "Yes";
BA_DEF_ BO_ "VAGTP20_DynSetup" ENUM "No", "Yes";
BA_DEF_ BO_ "VAGTP20_StatConnection" ENUM "No", "Yes";
BA_DEF_ BO_ "VFrameFormat" ENUM "StandardCAN", "ExtendedCAN", "reserved", "reserved", "reserved", "reserved", "reserved", "reserved", "reserved", "reserved", "reserved", "reserved", "reserved", "reserved", "StandardCAN_FD", "ExtendedCAN_FD";
BA_DEF_ SG_ "Fehlerwert" HEX 0 2147483647;
BA_DEF_ SG_ "GenSigActiveRepetitions" INT -2147483648 2147483647;
BA_DEF_ SG_ "GenSigFuncType" ENUM "NoFunction", "MsgCounter", "CRC-8", "XOR", "XOR-2", "DatedBit", "SW-Kl15", "CHK", "Constant", "Protocol", "CRC-8-SAE_J1850", "CRC-32", "DataLength", "DataID", "MsgCounter16", "SOK-Signatur", "Cluster";
BA_DEF_ SG_ "GenSigInactiveValue" INT -2147483648 2147483647;
BA_DEF_ SG_ "GenSigMissingSourceValue" HEX 0 2147483647;
BA_DEF_ SG_ "GenSigSendType" ENUM "Cyclic", "OnWrite", "OnWriteWithRepetition", "OnChange", "OnChangeWithRepetition", "IfActive", "IfActiveWithRepetition", "NoSigSendType", "OnChangeAndIfActive", "OnChangeAndIfActiveWithRepetition";
BA_DEF_ SG_ "GenSigStartValue" INT -2147483648 2147483647;
BA_DEF_ SG_ "GenSigSwitchedByIgnition" ENUM "No", "Yes";
BA_DEF_ SG_ "NWM-WakeupAllowed" ENUM "No", "Yes";

BA_DEF_REL_ BU_SG_REL_ "GenSigTimeoutTime" INT 0 65535;
BA_DEF_DEF_ "CANFD_BRS" "1";
BA_DEF_DEF_ "DiagRequest" "No";
BA_DEF_DEF_ "DiagResponse" "No";
BA_DEF_DEF_ "DiagState" "No";
BA_DEF_DEF_ "Fehlerwert" 0;
BA_DEF_DEF_ "GenMsgChkConstant" 0;
BA_DEF_DEF_ "GenMsgCycleTime" 0;
BA_DEF_DEF_ "GenMsgCycleTimeFast" 0;
BA_DEF_DEF_ "GenMsgDelayTime" 0;
BA_DEF_DEF_ "GenMsgILSupport" "No";
BA_DEF_DEF_ "GenMsgNrOfRepetition" 0;
BA_DEF_DEF_ "GenMsgPDUConstants" "";
BA_DEF_DEF_ "GenMsgSendType" "NoMsgSendType";
BA_DEF_DEF_ "GenMsgStartDelayTime" 0;
BA_DEF_DEF_ "GenSigActiveRepetitions" 0;
BA_DEF_DEF_ "GenSigFuncType" "NoFunction";
BA_DEF_DEF_ "GenSigInactiveValue" 0;
BA_DEF_DEF_ "GenSigMissingSourceValue" 0;
BA_DEF_DEF_ "GenSigSendType" "NoSigSendType";
BA_DEF_DEF_ "GenSigStartValue" 0;
BA_DEF_DEF_ "GenSigSwitchedByIgnition" "Yes";
BA_DEF_DEF_ "MsgType" "Application";
BA_DEF_DEF_ "NWM-WakeupAllowed" "No";
BA_DEF_DEF_ "NmMessage" "No";
BA_DEF_DEF_ "NmhMessage" "No";
BA_DEF_DEF_ "VAGTP20_API" 0;
BA_DEF_DEF_ "VAGTP20_DynConnection" "No";
BA_DEF_DEF_ "VAGTP20_DynSetup" "No";
BA_DEF_DEF_ "VAGTP20_StatConnection" "No";
BA_DEF_DEF_ "VFrameFormat" "StandardCAN";
BA_DEF_DEF_REL_ "GenSigTimeoutTime" 0;
BA_ "GenMsgCycleTime" BO_ 2589283617 1000;
BA_ "GenMsgDelayTime" BO_ 2589283617 50;
BA_ "GenMsgILSupport" BO_ 2589283617 1;
BA_ "GenMsgPDUConstants" BO_ 2589283617 "0xad,0xbd,0x5e,0x44,0x5b,0x90,0xb4,0x8d,0x9a,0x74,0xba,0xfa,0x2b,0x91,0xe2,0x89";
BA_ "GenMsgSendType" BO_ 2589283617 0;
BA_ "VFrameFormat" BO_ 2589283617 15;
BA_ "GenMsgCycleTime" BO_ 2527679740 200;
BA_ "GenMsgDelayTime" BO_ 2527679740 50;
BA_ "GenMsgILSupport" BO_ 2527679740 1;
BA_ "GenMsgSendType" BO_ 2527679740 0;
BA_ "VFrameFormat" BO_ 2527679740 15;
BA_ "GenMsgCycleTime" BO_ 2589283684 1000;
BA_ "GenMsgDelayTime" BO_ 2589283684 200;
BA_ "GenMsgILSupport" BO_ 2589283684 1;
BA_ "GenMsgSendType" BO_ 2589283684 0;
BA_ "VFrameFormat" BO_ 2589283684 15;
BA_ "MsgType" BO_ 2549875476 4;
BA_ "VFrameFormat" BO_ 2549875476 15;
BA_ "MsgType" BO_ 2550006548 4;
BA_ "VFrameFormat" BO_ 2550006548 15;
BA_ "MsgType" BO_ 2549875571 4;
BA_ "VFrameFormat" BO_ 2549875571 15;
BA_ "MsgType" BO_ 2550006643 4;
BA_ "VFrameFormat" BO_ 2550006643 15;
BA_ "GenMsgCycleTime" BO_ 986 100;
BA_ "GenMsgDelayTime" BO_ 986 10;
BA_ "GenMsgILSupport" BO_ 986 1;
BA_ "GenMsgSendType" BO_ 986 0;
BA_ "VFrameFormat" BO_ 986 14;
BA_ "GenMsgCycleTime" BO_ 988 50;
BA_ "GenMsgDelayTime" BO_ 988 10;
BA_ "GenMsgILSupport" BO_ 988 1;
BA_ "GenMsgSendType" BO_ 988 0;
BA_ "VFrameFormat" BO_ 988 14;
BA_ "GenMsgChkConstant" BO_ 324 227;
BA_ "GenMsgCycleTime" BO_ 324 20;
BA_ "GenMsgILSupport" BO_ 324 1;
BA_ "GenMsgPDUConstants" BO_ 324 "0xe3,0xe3,0xe3,0xe3,0xe3,0xe3,0xe3,0xe3,0xe3,0xe3,0xe3,0xe3,0xe3,0xe3,0xe3,0xe3";
BA_ "GenMsgSendType" BO_ 324 0;
BA_ "VFrameFormat" BO_ 324 14;
BA_ "GenMsgCycleTime" BO_ 588 50;
BA_ "GenMsgILSupport" BO_ 588 1;
BA_ "GenMsgSendType" BO_ 588 0;
BA_ "VFrameFormat" BO_ 588 14;
BA_ "GenMsgCycleTime" BO_ 589 50;
BA_ "GenMsgILSupport" BO_ 589 1;
BA_ "GenMsgSendType" BO_ 589 0;
BA_ "VFrameFormat" BO_ 589 14;
BA_ "MsgType" BO_ 2635073907 4;
BA_ "VFrameFormat" BO_ 2635073907 15;
BA_ "MsgType" BO_ 2635204979 4;
BA_ "VFrameFormat" BO_ 2635204979 15;
BA_ "MsgType" BO_ 2634029939 4;
BA_ "VFrameFormat" BO_ 2634029939 15;
BA_ "MsgType" BO_ 2634161011 4;
BA_ "VFrameFormat" BO_ 2634161011 15;
BA_ "MsgType" BO_ 2634314505 4;
BA_ "VFrameFormat" BO_ 2634314505 15;
BA_ "MsgType" BO_ 2634445577 4;
BA_ "VFrameFormat" BO_ 2634445577 15;
BA_ "MsgType" BO_ 2634052379 4;
BA_ "VFrameFormat" BO_ 2634052379 15;
BA_ "MsgType" BO_ 2634183451 4;
BA_ "VFrameFormat" BO_ 2634183451 15;
BA_ "MsgType" BO_ 2629835579 4;
BA_ "VFrameFormat" BO_ 2629835579 15;
BA_ "MsgType" BO_ 2629966651 4;
BA_ "VFrameFormat" BO_ 2629966651 15;
BA_ "GenMsgCycleTime" BO_ 1283 100;
BA_ "GenMsgDelayTime" BO_ 1283 10;
BA_ "GenMsgILSupport" BO_ 1283 1;
BA_ "GenMsgPDUConstants" BO_ 1283 "0xed,0xd6,0x96,0x63,0xa5,0x12,0xd5,0x9a,0x1e,0x0d,0x24,0xcd,0x8c,0xa6,0x2f,0x41";
BA_ "GenMsgSendType" BO_ 1283 0;
BA_ "VFrameFormat" BO_ 1283 14;
BA_ "GenMsgCycleTime" BO_ 2527679583 1000;
BA_ "GenMsgCycleTimeFast" BO_ 2527679583 100;
BA_ "GenMsgDelayTime" BO_ 2527679583 50;
BA_ "GenMsgILSupport" BO_ 2527679583 1;
BA_ "GenMsgNrOfRepetition" BO_ 2527679583 5;
BA_ "GenMsgPDUConstants" BO_ 2527679583 "0xc6,0x7f,0x85,0xb6,0xe6,0xae,0xf8,0x26,0xb0,0x8c,0x19,0x10,0x5b,0x33,0x64,0x6c";
BA_ "GenMsgSendType" BO_ 2527679583 0;
BA_ "VFrameFormat" BO_ 2527679583 15;
BA_ "DiagState" BO_ 1792 1;
BA_ "MsgType" BO_ 1792 4;
BA_ "VFrameFormat" BO_ 1792 14;
BA_ "DiagRequest" BO_ 1819 1;
BA_ "MsgType" BO_ 1819 4;
BA_ "VFrameFormat" BO_ 1819 14;
BA_ "DiagResponse" BO_ 1925 1;
BA_ "MsgType" BO_ 1925 4;
BA_ "VFrameFormat" BO_ 1925 14;
BA_ "DiagRequest" BO_ 1812 1;
BA_ "MsgType" BO_ 1812 4;
BA_ "VFrameFormat" BO_ 1812 14;
BA_ "DiagResponse" BO_ 1918 1;
BA_ "MsgType" BO_ 1918 4;
BA_ "VFrameFormat" BO_ 1918 14;
BA_ "MsgType" BO_ 2549358366 4;
BA_ "VFrameFormat" BO_ 2549358366 15;
BA_ "MsgType" BO_ 2549489183 4;
BA_ "VFrameFormat" BO_ 2549489183 15;
BA_ "MsgType" BO_ 2549358111 4;
BA_ "VFrameFormat" BO_ 2549358111 15;
BA_ "MsgType" BO_ 2549489438 4;
BA_ "VFrameFormat" BO_ 2549489438 15;
BA_ "DiagRequest" BO_ 1901 1;
BA_ "MsgType" BO_ 1901 4;
BA_ "VFrameFormat" BO_ 1901 14;
BA_ "DiagResponse" BO_ 2007 1;
BA_ "MsgType" BO_ 2007 4;
BA_ "VFrameFormat" BO_ 2007 14;
BA_ "DiagRequest" BO_ 2550398985 1;
BA_ "MsgType" BO_ 2550398985 4;
BA_ "VFrameFormat" BO_ 2550398985 15;
BA_ "DiagRequest" BO_ 2621702153 1;
BA_ "MsgType" BO_ 2621702153 4;
BA_ "VFrameFormat" BO_ 2621702153 15;
BA_ "DiagResponse" BO_ 2550530057 1;
BA_ "MsgType" BO_ 2550530057 4;
BA_ "VFrameFormat" BO_ 2550530057 15;
BA_ "DiagResponse" BO_ 2621833225 1;
BA_ "MsgType" BO_ 2621833225 4;
BA_ "VFrameFormat" BO_ 2621833225 15;
BA_ "DiagState" BO_ 2621505536 1;
BA_ "MsgType" BO_ 2621505536 4;
BA_ "VFrameFormat" BO_ 2621505536 15;
BA_ "DiagRequest" BO_ 2621440027 1;
BA_ "MsgType" BO_ 2621440027 4;
BA_ "VFrameFormat" BO_ 2621440027 15;
BA_ "DiagResponse" BO_ 2621571099 1;
BA_ "MsgType" BO_ 2621571099 4;
BA_ "VFrameFormat" BO_ 2621571099 15;
BA_ "DiagRequest" BO_ 2621440020 1;
BA_ "MsgType" BO_ 2621440020 4;
BA_ "VFrameFormat" BO_ 2621440020 15;
BA_ "DiagResponse" BO_ 2621571092 1;
BA_ "MsgType" BO_ 2621571092 4;
BA_ "VFrameFormat" BO_ 2621571092 15;
BA_ "DiagRequest" BO_ 2550398988 1;
BA_ "MsgType" BO_ 2550398988 4;
BA_ "VFrameFormat" BO_ 2550398988 15;
BA_ "DiagRequest" BO_ 2621702156 1;
BA_ "MsgType" BO_ 2621702156 4;
BA_ "VFrameFormat" BO_ 2621702156 15;
BA_ "DiagResponse" BO_ 2550530060 1;
BA_ "MsgType" BO_ 2550530060 4;
BA_ "VFrameFormat" BO_ 2550530060 15;
BA_ "DiagResponse" BO_ 2621833228 1;
BA_ "MsgType" BO_ 2621833228 4;
BA_ "VFrameFormat" BO_ 2621833228 15;
BA_ "DiagRequest" BO_ 2549874853 1;
BA_ "MsgType" BO_ 2549874853 4;
BA_ "VFrameFormat" BO_ 2549874853 15;
BA_ "DiagResponse" BO_ 2550005925 1;
BA_ "MsgType" BO_ 2550005925 4;
BA_ "VFrameFormat" BO_ 2550005925 15;
BA_ "GenMsgCycleTime" BO_ 1426 200;
BA_ "GenMsgDelayTime" BO_ 1426 20;
BA_ "GenMsgILSupport" BO_ 1426 1;
BA_ "GenMsgSendType" BO_ 1426 0;
BA_ "VFrameFormat" BO_ 1426 14;
BA_ "GenMsgChkConstant" BO_ 960 195;
BA_ "GenMsgCycleTime" BO_ 960 100;
BA_ "GenMsgDelayTime" BO_ 960 10;
BA_ "GenMsgILSupport" BO_ 960 1;
BA_ "GenMsgPDUConstants" BO_ 960 "0xc3,0xc3,0xc3,0xc3,0xc3,0xc3,0xc3,0xc3,0xc3,0xc3,0xc3,0xc3,0xc3,0xc3,0xc3,0xc3";
BA_ "GenMsgSendType" BO_ 960 0;
BA_ "VFrameFormat" BO_ 960 14;
BA_ "GenMsgCycleTime" BO_ 2463978753 1000;
BA_ "GenMsgCycleTimeFast" BO_ 2463978753 100;
BA_ "GenMsgDelayTime" BO_ 2463978753 10;
BA_ "GenMsgILSupport" BO_ 2463978753 1;
BA_ "GenMsgNrOfRepetition" BO_ 2463978753 5;
BA_ "GenMsgPDUConstants" BO_ 2463978753 "0x80,0xf1,0xa5,0xaf,0x94,0x59,0xe8,0x8c,0x03,0xd4,0xf5,0x5e,0xec,0x73,0x81,0x50";
BA_ "GenMsgSendType" BO_ 2463978753 0;
BA_ "VFrameFormat" BO_ 2463978753 15;
BA_ "GenMsgCycleTime" BO_ 1420 1000;
BA_ "GenMsgCycleTimeFast" BO_ 1420 20;
BA_ "GenMsgDelayTime" BO_ 1420 10;
BA_ "GenMsgILSupport" BO_ 1420 1;
BA_ "GenMsgNrOfRepetition" BO_ 1420 5;
BA_ "GenMsgPDUConstants" BO_ 1420 "0x9b,0xb5,0x9d,0x06,0x01,0xe7,0x8f,0xc1,0xd0,0x10,0x47,0xe9,0xd3,0xca,0x05,0xf0";
BA_ "GenMsgSendType" BO_ 1420 0;
BA_ "VFrameFormat" BO_ 1420 14;
BA_ "GenSigSendType" SG_ 2589283617 DBK_Fahrerwarnung 0;
BA_ "GenSigSwitchedByIgnition" SG_ 2589283617 DBK_Fahrerwarnung 0;
BA_ "GenSigSendType" SG_ 2589283617 EDS_Charisma_FahrPr 3;
BA_ "GenSigSwitchedByIgnition" SG_ 2589283617 EDS_Charisma_FahrPr 0;
BA_ "GenSigSendType" SG_ 2589283617 EDS_Charisma_Status 3;
BA_ "GenSigSwitchedByIgnition" SG_ 2589283617 EDS_Charisma_Status 0;
BA_ "GenSigSendType" SG_ 2589283617 ESC_Anf_KL 0;
BA_ "GenSigSwitchedByIgnition" SG_ 2589283617 ESC_Anf_KL 0;
BA_ "GenSigSendType" SG_ 2589283617 ESC_Anf_KV 0;
BA_ "GenSigSwitchedByIgnition" SG_ 2589283617 ESC_Anf_KV 0;
BA_ "GenSigSendType" SG_ 2589283617 ESC_FBA_Meldungen 3;
BA_ "GenSigSwitchedByIgnition" SG_ 2589283617 ESC_FBA_Meldungen 0;
BA_ "GenSigSendType" SG_ 2589283617 ESC_Lernfreigabe_Abrollumfang 3;
BA_ "GenSigSwitchedByIgnition" SG_ 2589283617 ESC_Lernfreigabe_Abrollumfang 0;
BA_ "GenSigSendType" SG_ 2589283617 ESC_MBK_Meldungen 3;
BA_ "GenSigSwitchedByIgnition" SG_ 2589283617 ESC_MBK_Meldungen 0;
BA_ "GenSigSendType" SG_ 2589283617 ESC_Texte_eBKV_Betaetigung 3;
BA_ "GenSigSwitchedByIgnition" SG_ 2589283617 ESC_Texte_eBKV_Betaetigung 0;
BA_ "GenSigFuncType" SG_ 2589283617 ESP_30_BZ 1;
BA_ "GenSigSendType" SG_ 2589283617 ESP_30_BZ 0;
BA_ "GenSigSwitchedByIgnition" SG_ 2589283617 ESP_30_BZ 0;
BA_ "GenSigFuncType" SG_ 2589283617 ESP_30_CRC 2;
BA_ "GenSigSendType" SG_ 2589283617 ESP_30_CRC 0;
BA_ "GenSigSwitchedByIgnition" SG_ 2589283617 ESP_30_CRC 0;
BA_ "GenSigSendType" SG_ 2589283617 HHC_Charisma_FahrPr 3;
BA_ "GenSigSwitchedByIgnition" SG_ 2589283617 HHC_Charisma_FahrPr 0;
BA_ "GenSigSendType" SG_ 2589283617 HHC_Charisma_Status 3;
BA_ "GenSigSwitchedByIgnition" SG_ 2589283617 HHC_Charisma_Status 0;
BA_ "Fehlerwert" SG_ 2589283617 HMS_EML_Steig_Exkl 1023;
BA_ "GenSigSendType" SG_ 2589283617 HMS_EML_Steig_Exkl 0;
BA_ "GenSigSwitchedByIgnition" SG_ 2589283617 HMS_EML_Steig_Exkl 0;
BA_ "GenSigSendType" SG_ 2589283617 RLE_Anzeigen 0;
BA_ "GenSigSwitchedByIgnition" SG_ 2589283617 RLE_Anzeigen 0;
BA_ "GenSigSendType" SG_ 2527679740 KBI_aktive_Laengsfunktion_02 3;
BA_ "GenSigSendType" SG_ 2527679740 KBI_Anzeigefehler_LDW 3;
BA_ "GenSigSwitchedByIgnition" SG_ 2527679740 KBI_Anzeigefehler_LDW 0;
BA_ "GenSigSendType" SG_ 2527679740 KBI_Anzeigestatus_ACC 3;
BA_ "GenSigSwitchedByIgnition" SG_ 2527679740 KBI_Anzeigestatus_ACC 0;
BA_ "Fehlerwert" SG_ 2527679740 KBI_Anzeigestatus_GRA 3;
BA_ "GenSigSendType" SG_ 2527679740 KBI_Anzeigestatus_GRA 3;
BA_ "GenSigSwitchedByIgnition" SG_ 2527679740 KBI_Anzeigestatus_GRA 0;
BA_ "Fehlerwert" SG_ 2527679740 KBI_Anzeigestatus_LIM 3;
BA_ "GenSigSendType" SG_ 2527679740 KBI_Anzeigestatus_LIM 3;
BA_ "GenSigSwitchedByIgnition" SG_ 2527679740 KBI_Anzeigestatus_LIM 0;
BA_ "GenSigSendType" SG_ 2527679740 KBI_Fehler_Anzeige_ACC 3;
BA_ "GenSigSwitchedByIgnition" SG_ 2527679740 KBI_Fehler_Anzeige_ACC 0;
BA_ "GenSigSendType" SG_ 2527679740 KBI_Konsistenz_ACC 3;
BA_ "GenSigSwitchedByIgnition" SG_ 2527679740 KBI_Konsistenz_ACC 0;
BA_ "GenSigSendType" SG_ 2589283684 FoD_Anz_Funktionsabschaltung 3;
BA_ "GenSigSwitchedByIgnition" SG_ 2589283684 FoD_Anz_Funktionsabschaltung 0;
BA_ "GenSigSendType" SG_ 2589283684 FoD_State_IPA_RPA 0;
BA_ "GenSigSwitchedByIgnition" SG_ 2589283684 FoD_State_IPA_RPA 0;
BA_ "GenSigSendType" SG_ 2589283684 FoD_State_TopView_SideView_RVC 0;
BA_ "GenSigSwitchedByIgnition" SG_ 2589283684 FoD_State_TopView_SideView_RVC 0;
BA_ "GenSigSendType" SG_ 2589283684 FoD_State_TPA_rTPA 0;
BA_ "GenSigSwitchedByIgnition" SG_ 2589283684 FoD_State_TPA_rTPA 0;
BA_ "GenSigSendType" SG_ 2589283684 FoD_Transmission_Info 3;
BA_ "GenSigSwitchedByIgnition" SG_ 2589283684 FoD_Transmission_Info 0;
BA_ "GenSigSendType" SG_ 2589283684 GRA_FoD_Status 3;
BA_ "GenSigSwitchedByIgnition" SG_ 2589283684 GRA_FoD_Status 0;
BA_ "GenSigFuncType" SG_ 2549875476 FoD_Kombi_Req_Data 9;
BA_ "GenSigSendType" SG_ 2549875476 FoD_Kombi_Req_Data 3;
BA_ "GenSigSwitchedByIgnition" SG_ 2549875476 FoD_Kombi_Req_Data 0;
BA_ "GenSigFuncType" SG_ 2550006548 FoD_Kombi_Resp_Data 9;
BA_ "GenSigSendType" SG_ 2550006548 FoD_Kombi_Resp_Data 3;
BA_ "GenSigSwitchedByIgnition" SG_ 2550006548 FoD_Kombi_Resp_Data 0;
BA_ "GenSigFuncType" SG_ 2549875571 FoD_ZR_Req_Data 9;
BA_ "GenSigSendType" SG_ 2549875571 FoD_ZR_Req_Data 3;
BA_ "GenSigSwitchedByIgnition" SG_ 2549875571 FoD_ZR_Req_Data 0;
BA_ "GenSigFuncType" SG_ 2550006643 FoD_ZR_Resp_Data 9;
BA_ "GenSigSendType" SG_ 2550006643 FoD_ZR_Resp_Data 3;
BA_ "GenSigSwitchedByIgnition" SG_ 2550006643 FoD_ZR_Resp_Data 0;
BA_ "GenSigSendType" SG_ 986 ABS_Bremsung 0;
BA_ "GenSigSendType" SG_ 986 ECD_Bremslicht 3;
BA_ "GenSigFuncType" SG_ 986 EPB_01_alt 5;
BA_ "GenSigSendType" SG_ 986 EPB_01_alt 0;
BA_ "GenSigStartValue" SG_ 986 EPB_01_alt 1;
BA_ "Fehlerwert" SG_ 986 EPB_Pedalweg_Kuppl 255;
BA_ "GenSigSendType" SG_ 986 EPB_Pedalweg_Kuppl 0;
BA_ "GenSigSendType" SG_ 986 EPB_QBit_Pedalweg_Kuppl 0;
BA_ "GenSigStartValue" SG_ 986 EPB_QBit_Pedalweg_Kuppl 1;
BA_ "GenSigSendType" SG_ 986 EPB_Status 0;
BA_ "GenSigFuncType" SG_ 986 ESP_05_alt 5;
BA_ "GenSigSendType" SG_ 986 ESP_05_alt 0;
BA_ "GenSigStartValue" SG_ 986 ESP_05_alt 1;
BA_ "GenSigFuncType" SG_ 986 ESP_21_alt 5;
BA_ "GenSigSendType" SG_ 986 ESP_21_alt 0;
BA_ "GenSigStartValue" SG_ 986 ESP_21_alt 1;
BA_ "GenSigSwitchedByIgnition" SG_ 986 ESP_21_alt 0;
BA_ "GenSigSendType" SG_ 986 ESP_Eingriff 0;
BA_ "GenSigSendType" SG_ 986 ESP_HDC_Standby 0;
BA_ "GenSigSendType" SG_ 986 ESP_MKB_Abbruch_Geschw 3;
BA_ "GenSigSendType" SG_ 986 ESP_QBit_v_Signal 0;
BA_ "GenSigStartValue" SG_ 986 ESP_QBit_v_Signal 1;
BA_ "GenSigSwitchedByIgnition" SG_ 986 ESP_QBit_v_Signal 0;
BA_ "Fehlerwert" SG_ 986 ESP_v_Signal 65535;
BA_ "GenSigMissingSourceValue" SG_ 986 ESP_v_Signal 65534;
BA_ "GenSigSendType" SG_ 986 ESP_v_Signal 0;
BA_ "GenSigStartValue" SG_ 986 ESP_v_Signal 65534;
BA_ "GenSigSwitchedByIgnition" SG_ 986 ESP_v_Signal 0;
BA_ "GenSigSendType" SG_ 986 Kamera_FSH_aktiv 0;
BA_ "GenSigFuncType" SG_ 986 Kamera_Status_alt 5;
BA_ "GenSigSendType" SG_ 986 Kamera_Status_alt 0;
BA_ "GenSigFuncType" SG_ 986 LWI_01_alt 5;
BA_ "GenSigSendType" SG_ 986 LWI_01_alt 0;
BA_ "GenSigStartValue" SG_ 986 LWI_01_alt 1;
BA_ "Fehlerwert" SG_ 986 LWI_Lenkradwinkel 8191;
BA_ "GenSigSendType" SG_ 986 LWI_Lenkradwinkel 0;
BA_ "GenSigStartValue" SG_ 986 LWI_Lenkradwinkel 8190;
BA_ "GenSigSendType" SG_ 986 LWI_QBit_Lenkradwinkel 0;
BA_ "GenSigStartValue" SG_ 986 LWI_QBit_Lenkradwinkel 1;
BA_ "GenSigSendType" SG_ 986 LWI_Sensorstatus 0;
BA_ "GenSigSendType" SG_ 986 LWI_VZ_Lenkradwinkel 0;
BA_ "GenSigFuncType" SG_ 986 Parkhilfe_01_alt 5;
BA_ "GenSigSendType" SG_ 986 Parkhilfe_01_alt 0;
BA_ "GenSigStartValue" SG_ 986 Parkhilfe_01_alt 1;
BA_ "GenSigSendType" SG_ 986 PH_Anf_Audioabsenkung 0;
BA_ "GenSigSendType" SG_ 986 PH_Systemzustand 0;
BA_ "Fehlerwert" SG_ 986 PH_Taster 3;
BA_ "GenSigSendType" SG_ 986 PH_Taster 3;
BA_ "GenSigSendType" SG_ 986 PLA_Anf_Aufschaltung_RVC 3;
BA_ "GenSigFuncType" SG_ 988 ACC_18_alt 5;
BA_ "GenSigSendType" SG_ 988 ACC_18_alt 0;
BA_ "GenSigStartValue" SG_ 988 ACC_18_alt 1;
BA_ "GenSigSendType" SG_ 988 ACC_Status_ACC 0;
BA_ "GenSigSendType" SG_ 988 EPB_Status_02 0;
BA_ "GenSigStartValue" SG_ 988 EPB_Status_02 6;
BA_ "GenSigFuncType" SG_ 988 ESP_07_alt 5;
BA_ "GenSigSendType" SG_ 988 ESP_07_alt 0;
BA_ "GenSigStartValue" SG_ 988 ESP_07_alt 1;
BA_ "GenSigSwitchedByIgnition" SG_ 988 ESP_07_alt 0;
BA_ "GenSigFuncType" SG_ 988 ESP_50_alt 5;
BA_ "GenSigSendType" SG_ 988 ESP_50_alt 0;
BA_ "GenSigStartValue" SG_ 988 ESP_50_alt 1;
BA_ "GenSigSendType" SG_ 988 ESP_Rollenmodus_Deaktivieren 0;
BA_ "GenSigSwitchedByIgnition" SG_ 988 ESP_Rollenmodus_Deaktivieren 0;
BA_ "GenSigSendType" SG_ 988 ESP_Status_Bremsentemp_02 0;
BA_ "Fehlerwert" SG_ 988 GE_Fahrstufe 15;
BA_ "GenSigSendType" SG_ 988 GE_Fahrstufe 3;
BA_ "GenSigStartValue" SG_ 988 GE_Fahrstufe 1;
BA_ "GenSigSwitchedByIgnition" SG_ 988 GE_Fahrstufe 0;
BA_ "Fehlerwert" SG_ 988 GE_Freilauf_Status 7;
BA_ "GenSigSendType" SG_ 988 GE_Freilauf_Status 0;
BA_ "GenSigSendType" SG_ 988 GE_Notlauf 3;
BA_ "GenSigSendType" SG_ 988 GE_Sperr_Info_WFS 3;
BA_ "GenSigSendType" SG_ 988 GE_Ursache_Fahrstufe_N 0;
BA_ "GenSigFuncType" SG_ 988 Getriebe_11_alt 5;
BA_ "GenSigSendType" SG_ 988 Getriebe_11_alt 0;
BA_ "GenSigStartValue" SG_ 988 Getriebe_11_alt 1;
BA_ "GenSigSwitchedByIgnition" SG_ 988 Getriebe_11_alt 0;
BA_ "GenSigFuncType" SG_ 988 Getriebe_13_alt 5;
BA_ "GenSigSendType" SG_ 988 Getriebe_13_alt 0;
BA_ "GenSigStartValue" SG_ 988 Getriebe_13_alt 1;
BA_ "GenSigFuncType" SG_ 988 Getriebe_14_alt 5;
BA_ "GenSigSendType" SG_ 988 Getriebe_14_alt 0;
BA_ "GenSigStartValue" SG_ 988 Getriebe_14_alt 1;
BA_ "GenSigFuncType" SG_ 988 Getriebe_17_alt 5;
BA_ "GenSigSendType" SG_ 988 Getriebe_17_alt 0;
BA_ "GenSigStartValue" SG_ 988 Getriebe_17_alt 1;
BA_ "GenSigSendType" SG_ 988 MKE_Stufe 0;
BA_ "GenSigSendType" SG_ 988 MKE_Texte 0;
BA_ "GenSigSendType" SG_ 988 MO_Drehzahl_01 0;
BA_ "GenSigSendType" SG_ 988 MO_QBit_Drehzahl_01 0;
BA_ "GenSigStartValue" SG_ 988 MO_QBit_Drehzahl_01 1;
BA_ "GenSigSwitchedByIgnition" SG_ 988 MO_QBit_Drehzahl_01 0;
BA_ "GenSigFuncType" SG_ 988 Motor_12_alt 5;
BA_ "GenSigSendType" SG_ 988 Motor_12_alt 0;
BA_ "GenSigStartValue" SG_ 988 Motor_12_alt 1;
BA_ "GenSigSwitchedByIgnition" SG_ 988 Motor_12_alt 0;
BA_ "GenSigSendType" SG_ 988 TSK_06_alt 0;
BA_ "GenSigStartValue" SG_ 988 TSK_06_alt 1;
BA_ "GenSigSwitchedByIgnition" SG_ 988 TSK_06_alt 0;
BA_ "Fehlerwert" SG_ 988 TSK_Hauptschalter_GRA_ACC 3;
BA_ "GenSigSendType" SG_ 988 TSK_Hauptschalter_GRA_ACC 0;
BA_ "GenSigSwitchedByIgnition" SG_ 988 TSK_Hauptschalter_GRA_ACC 0;
BA_ "GenSigSendType" SG_ 988 TSK_Limiter_ausgewaehlt 0;
BA_ "GenSigSwitchedByIgnition" SG_ 988 TSK_Limiter_ausgewaehlt 0;
BA_ "GenSigSendType" SG_ 324 GE_Ausleuchtung_blinkend 0;
BA_ "GenSigSwitchedByIgnition" SG_ 324 GE_Ausleuchtung_blinkend 0;
BA_ "Fehlerwert" SG_ 324 GE_Ausleuchtung_Fahrstufe 15;
BA_ "GenSigSendType" SG_ 324 GE_Ausleuchtung_Fahrstufe 0;
BA_ "GenSigSwitchedByIgnition" SG_ 324 GE_Ausleuchtung_Fahrstufe 0;
BA_ "GenSigSendType" SG_ 324 GE_N_Haltephase 0;
BA_ "GenSigSwitchedByIgnition" SG_ 324 GE_N_Haltephase 0;
BA_ "GenSigSendType" SG_ 324 GE_Soll_Haltemagnet 0;
BA_ "GenSigSwitchedByIgnition" SG_ 324 GE_Soll_Haltemagnet 0;
BA_ "GenSigSendType" SG_ 324 GE_Test_Freigabe 0;
BA_ "GenSigSwitchedByIgnition" SG_ 324 GE_Test_Freigabe 0;
BA_ "GenSigSendType" SG_ 324 GE_Testparameter_1 0;
BA_ "GenSigSwitchedByIgnition" SG_ 324 GE_Testparameter_1 0;
BA_ "GenSigSendType" SG_ 324 GE_Testparameter_2 0;
BA_ "GenSigSwitchedByIgnition" SG_ 324 GE_Testparameter_2 0;
BA_ "GenSigSendType" SG_ 324 GE_WH_Abschalten 0;
BA_ "GenSigSwitchedByIgnition" SG_ 324 GE_WH_Abschalten 0;
BA_ "GenSigSendType" SG_ 324 GE_WH_Mute 0;
BA_ "GenSigSwitchedByIgnition" SG_ 324 GE_WH_Mute 0;
BA_ "GenSigSendType" SG_ 324 GE_WH_Shiftlock 0;
BA_ "GenSigStartValue" SG_ 324 GE_WH_Shiftlock 1;
BA_ "GenSigSwitchedByIgnition" SG_ 324 GE_WH_Shiftlock 0;
BA_ "GenSigFuncType" SG_ 324 Getriebe_16_BZ 1;
BA_ "GenSigSendType" SG_ 324 Getriebe_16_BZ 0;
BA_ "GenSigSwitchedByIgnition" SG_ 324 Getriebe_16_BZ 0;
BA_ "GenSigFuncType" SG_ 324 Getriebe_16_CRC 2;
BA_ "GenSigSendType" SG_ 324 Getriebe_16_CRC 0;
BA_ "GenSigSwitchedByIgnition" SG_ 324 Getriebe_16_CRC 0;
BA_ "GenSigSendType" SG_ 324 WH_Warnung_02 3;
BA_ "GenSigSwitchedByIgnition" SG_ 324 WH_Warnung_02 0;
BA_ "GenSigSendType" SG_ 588 ASW_Kombiausgabe 0;
BA_ "GenSigSendType" SG_ 588 ASW_Kombitexte 0;
BA_ "GenSigSwitchedByIgnition" SG_ 588 ASW_Kombitexte 0;
BA_ "GenSigSendType" SG_ 588 ASW_Modus 0;
BA_ "GenSigStartValue" SG_ 588 ASW_Modus 4;
BA_ "Fehlerwert" SG_ 588 ASW_Status 2;
BA_ "GenSigSendType" SG_ 588 ASW_Status 0;
BA_ "GenSigSwitchedByIgnition" SG_ 588 ASW_Status 0;
BA_ "GenSigSendType" SG_ 588 ASW_Ton_Richtung_HL 0;
BA_ "GenSigSwitchedByIgnition" SG_ 588 ASW_Ton_Richtung_HL 0;
BA_ "GenSigSendType" SG_ 588 ASW_Ton_Richtung_HR 0;
BA_ "GenSigSwitchedByIgnition" SG_ 588 ASW_Ton_Richtung_HR 0;
BA_ "GenSigSendType" SG_ 588 ASW_Ton_Richtung_VL 0;
BA_ "GenSigSwitchedByIgnition" SG_ 588 ASW_Ton_Richtung_VL 0;
BA_ "GenSigSendType" SG_ 588 ASW_Ton_Richtung_VR 0;
BA_ "GenSigSwitchedByIgnition" SG_ 588 ASW_Ton_Richtung_VR 0;
BA_ "GenSigSendType" SG_ 588 ASW_Warnung_BFS 0;
BA_ "GenSigSwitchedByIgnition" SG_ 588 ASW_Warnung_BFS 0;
BA_ "GenSigSendType" SG_ 588 ASW_Warnung_FS 0;
BA_ "GenSigSwitchedByIgnition" SG_ 588 ASW_Warnung_FS 0;
BA_ "GenSigSendType" SG_ 588 Heckradar_Kombitexte 0;
BA_ "GenSigSwitchedByIgnition" SG_ 588 Heckradar_Kombitexte 0;
BA_ "GenSigSendType" SG_ 588 HRE_Anzeigetexte 0;
BA_ "GenSigSwitchedByIgnition" SG_ 588 HRE_Anzeigetexte 0;
BA_ "GenSigSendType" SG_ 588 RCTA_Kombitexte 0;
BA_ "GenSigSwitchedByIgnition" SG_ 588 RCTA_Kombitexte 0;
BA_ "GenSigSendType" SG_ 588 SWA_Anzeigen 0;
BA_ "GenSigSwitchedByIgnition" SG_ 588 SWA_Anzeigen 0;
BA_ "GenSigSendType" SG_ 588 SWA_Blindheit_erkannt 0;
BA_ "GenSigSendType" SG_ 588 SWA_Blindheitsverdacht 0;
BA_ "GenSigSwitchedByIgnition" SG_ 588 SWA_Blindheitsverdacht 0;
BA_ "Fehlerwert" SG_ 588 SWA_Brightness_Mode_FPM 15;
BA_ "GenSigSendType" SG_ 588 SWA_Brightness_Mode_FPM 0;
BA_ "GenSigSwitchedByIgnition" SG_ 588 SWA_Brightness_Mode_FPM 0;
BA_ "GenSigSendType" SG_ 588 SWA_FT_RueckLED 0;
BA_ "GenSigSwitchedByIgnition" SG_ 588 SWA_FT_RueckLED 0;
BA_ "GenSigSendType" SG_ 588 SWA_Gischtzaehler 0;
BA_ "GenSigSendType" SG_ 588 SWA_Infostufe_Assist_li 0;
BA_ "GenSigSendType" SG_ 588 SWA_Infostufe_Assist_re 0;
BA_ "GenSigSendType" SG_ 588 SWA_Kombiausgabe 0;
BA_ "Fehlerwert" SG_ 588 SWA_LED_Hell_BFS 127;
BA_ "GenSigSendType" SG_ 588 SWA_LED_Hell_BFS 0;
BA_ "GenSigStartValue" SG_ 588 SWA_LED_Hell_BFS 126;
BA_ "Fehlerwert" SG_ 588 SWA_LED_Hell_FS 127;
BA_ "GenSigSendType" SG_ 588 SWA_LED_Hell_FS 0;
BA_ "GenSigStartValue" SG_ 588 SWA_LED_Hell_FS 126;
BA_ "GenSigSendType" SG_ 588 SWA_LED_Modus_BFS 0;
BA_ "GenSigSendType" SG_ 588 SWA_LED_Modus_FS 0;
BA_ "GenSigSendType" SG_ 588 SWA_Modus 0;
BA_ "GenSigSendType" SG_ 588 SWA_Modus_System 0;
BA_ "Fehlerwert" SG_ 588 SWA_rel_Fehler 1;
BA_ "GenSigSendType" SG_ 588 SWA_rel_Fehler 0;
BA_ "GenSigSendType" SG_ 588 SWA_rel_Nichtverf 0;
BA_ "GenSigSendType" SG_ 588 SWA_Sta_aktiv 0;
BA_ "GenSigSendType" SG_ 588 SWA_Sta_passiv 0;
BA_ "GenSigSendType" SG_ 588 SWA_Standziele_li 0;
BA_ "GenSigSendType" SG_ 588 SWA_Standziele_re 0;
BA_ "Fehlerwert" SG_ 588 SWA_Status 3;
BA_ "GenSigSendType" SG_ 588 SWA_Status 0;
BA_ "Fehlerwert" SG_ 588 SWA_Status_KuFu 3;
BA_ "GenSigSendType" SG_ 588 SWA_Status_KuFu 0;
BA_ "Fehlerwert" SG_ 588 SWA_Status_System 3;
BA_ "GenSigSendType" SG_ 588 SWA_Status_System 0;
BA_ "GenSigSendType" SG_ 588 SWA_Warnstufe_Assist_li 0;
BA_ "GenSigSendType" SG_ 588 SWA_Warnstufe_Assist_re 0;
BA_ "GenSigSendType" SG_ 589 SWA_Infostufe_SWA_li 0;
BA_ "GenSigSendType" SG_ 589 SWA_Infostufe_SWA_re 0;
BA_ "GenSigSendType" SG_ 589 SWA_Kolonne_li 0;
BA_ "GenSigSendType" SG_ 589 SWA_Kolonne_mi 0;
BA_ "GenSigSendType" SG_ 589 SWA_Kolonne_re 0;
BA_ "GenSigSendType" SG_ 589 SWA_Obj_01_Breite 0;
BA_ "GenSigStartValue" SG_ 589 SWA_Obj_01_Breite 127;
BA_ "GenSigSendType" SG_ 589 SWA_Obj_01_Existenzwahrsch 0;
BA_ "GenSigStartValue" SG_ 589 SWA_Obj_01_Existenzwahrsch 127;
BA_ "GenSigSendType" SG_ 589 SWA_Obj_01_Gemessen 0;
BA_ "GenSigSendType" SG_ 589 SWA_Obj_01_GeschwRelX 0;
BA_ "GenSigStartValue" SG_ 589 SWA_Obj_01_GeschwRelX 511;
BA_ "GenSigSendType" SG_ 589 SWA_Obj_01_GeschwRelY 0;
BA_ "GenSigStartValue" SG_ 589 SWA_Obj_01_GeschwRelY 511;
BA_ "GenSigSendType" SG_ 589 SWA_Obj_01_ID 0;
BA_ "GenSigStartValue" SG_ 589 SWA_Obj_01_ID 31;
BA_ "GenSigSwitchedByIgnition" SG_ 589 SWA_Obj_01_ID 0;
BA_ "GenSigSendType" SG_ 589 SWA_Obj_01_Laenge 0;
BA_ "GenSigStartValue" SG_ 589 SWA_Obj_01_Laenge 127;
BA_ "GenSigSendType" SG_ 589 SWA_Obj_01_Objektklasse 0;
BA_ "GenSigStartValue" SG_ 589 SWA_Obj_01_Objektklasse 15;
BA_ "GenSigSendType" SG_ 589 SWA_Obj_01_PositionX 0;
BA_ "GenSigStartValue" SG_ 589 SWA_Obj_01_PositionX 511;
BA_ "GenSigSendType" SG_ 589 SWA_Obj_01_PositionY 0;
BA_ "GenSigStartValue" SG_ 589 SWA_Obj_01_PositionY 255;
BA_ "GenSigSendType" SG_ 589 SWA_Obj_01_ReferenzPkt 0;
BA_ "GenSigStartValue" SG_ 589 SWA_Obj_01_ReferenzPkt 15;
BA_ "GenSigSendType" SG_ 589 SWA_Obj_02_Breite 0;
BA_ "GenSigStartValue" SG_ 589 SWA_Obj_02_Breite 127;
BA_ "GenSigSendType" SG_ 589 SWA_Obj_02_Existenzwahrsch 0;
BA_ "GenSigStartValue" SG_ 589 SWA_Obj_02_Existenzwahrsch 127;
BA_ "GenSigSendType" SG_ 589 SWA_Obj_02_Gemessen 0;
BA_ "GenSigSendType" SG_ 589 SWA_Obj_02_GeschwRelX 0;
BA_ "GenSigStartValue" SG_ 589 SWA_Obj_02_GeschwRelX 511;
BA_ "GenSigSendType" SG_ 589 SWA_Obj_02_GeschwRelY 0;
BA_ "GenSigStartValue" SG_ 589 SWA_Obj_02_GeschwRelY 511;
BA_ "GenSigSendType" SG_ 589 SWA_Obj_02_ID 0;
BA_ "GenSigStartValue" SG_ 589 SWA_Obj_02_ID 31;
BA_ "GenSigSwitchedByIgnition" SG_ 589 SWA_Obj_02_ID 0;
BA_ "GenSigSendType" SG_ 589 SWA_Obj_02_Laenge 0;
BA_ "GenSigStartValue" SG_ 589 SWA_Obj_02_Laenge 127;
BA_ "GenSigSendType" SG_ 589 SWA_Obj_02_Objektklasse 0;
BA_ "GenSigStartValue" SG_ 589 SWA_Obj_02_Objektklasse 15;
BA_ "GenSigSendType" SG_ 589 SWA_Obj_02_PositionX 0;
BA_ "GenSigStartValue" SG_ 589 SWA_Obj_02_PositionX 511;
BA_ "GenSigSendType" SG_ 589 SWA_Obj_02_PositionY 0;
BA_ "GenSigStartValue" SG_ 589 SWA_Obj_02_PositionY 255;
BA_ "GenSigSendType" SG_ 589 SWA_Obj_02_ReferenzPkt 0;
BA_ "GenSigStartValue" SG_ 589 SWA_Obj_02_ReferenzPkt 15;
BA_ "GenSigSendType" SG_ 589 SWA_Obj_03_Breite 0;
BA_ "GenSigStartValue" SG_ 589 SWA_Obj_03_Breite 127;
BA_ "GenSigSendType" SG_ 589 SWA_Obj_03_Existenzwahrsch 0;
BA_ "GenSigStartValue" SG_ 589 SWA_Obj_03_Existenzwahrsch 127;
BA_ "GenSigSendType" SG_ 589 SWA_Obj_03_Gemessen 0;
BA_ "GenSigSendType" SG_ 589 SWA_Obj_03_GeschwRelX 0;
BA_ "GenSigStartValue" SG_ 589 SWA_Obj_03_GeschwRelX 511;
BA_ "GenSigSendType" SG_ 589 SWA_Obj_03_GeschwRelY 0;
BA_ "GenSigStartValue" SG_ 589 SWA_Obj_03_GeschwRelY 511;
BA_ "GenSigSendType" SG_ 589 SWA_Obj_03_ID 0;
BA_ "GenSigStartValue" SG_ 589 SWA_Obj_03_ID 31;
BA_ "GenSigSwitchedByIgnition" SG_ 589 SWA_Obj_03_ID 0;
BA_ "GenSigSendType" SG_ 589 SWA_Obj_03_Laenge 0;
BA_ "GenSigStartValue" SG_ 589 SWA_Obj_03_Laenge 127;
BA_ "GenSigSendType" SG_ 589 SWA_Obj_03_Objektklasse 0;
BA_ "GenSigStartValue" SG_ 589 SWA_Obj_03_Objektklasse 15;
BA_ "GenSigSendType" SG_ 589 SWA_Obj_03_PositionX 0;
BA_ "GenSigStartValue" SG_ 589 SWA_Obj_03_PositionX 511;
BA_ "GenSigSendType" SG_ 589 SWA_Obj_03_PositionY 0;
BA_ "GenSigStartValue" SG_ 589 SWA_Obj_03_PositionY 255;
BA_ "GenSigSendType" SG_ 589 SWA_Obj_03_ReferenzPkt 0;
BA_ "GenSigStartValue" SG_ 589 SWA_Obj_03_ReferenzPkt 15;
BA_ "GenSigSendType" SG_ 589 SWA_Obj_04_Breite 0;
BA_ "GenSigStartValue" SG_ 589 SWA_Obj_04_Breite 127;
BA_ "GenSigSendType" SG_ 589 SWA_Obj_04_Existenzwahrsch 0;
BA_ "GenSigStartValue" SG_ 589 SWA_Obj_04_Existenzwahrsch 127;
BA_ "GenSigSendType" SG_ 589 SWA_Obj_04_Gemessen 0;
BA_ "GenSigSendType" SG_ 589 SWA_Obj_04_GeschwRelX 0;
BA_ "GenSigStartValue" SG_ 589 SWA_Obj_04_GeschwRelX 511;
BA_ "GenSigSendType" SG_ 589 SWA_Obj_04_GeschwRelY 0;
BA_ "GenSigStartValue" SG_ 589 SWA_Obj_04_GeschwRelY 511;
BA_ "GenSigSendType" SG_ 589 SWA_Obj_04_ID 0;
BA_ "GenSigStartValue" SG_ 589 SWA_Obj_04_ID 31;
BA_ "GenSigSwitchedByIgnition" SG_ 589 SWA_Obj_04_ID 0;
BA_ "GenSigSendType" SG_ 589 SWA_Obj_04_Laenge 0;
BA_ "GenSigStartValue" SG_ 589 SWA_Obj_04_Laenge 127;
BA_ "GenSigSendType" SG_ 589 SWA_Obj_04_Objektklasse 0;
BA_ "GenSigStartValue" SG_ 589 SWA_Obj_04_Objektklasse 15;
BA_ "GenSigSendType" SG_ 589 SWA_Obj_04_PositionX 0;
BA_ "GenSigStartValue" SG_ 589 SWA_Obj_04_PositionX 511;
BA_ "GenSigSendType" SG_ 589 SWA_Obj_04_PositionY 0;
BA_ "GenSigStartValue" SG_ 589 SWA_Obj_04_PositionY 255;
BA_ "GenSigSendType" SG_ 589 SWA_Obj_04_ReferenzPkt 0;
BA_ "GenSigStartValue" SG_ 589 SWA_Obj_04_ReferenzPkt 15;
BA_ "GenSigSendType" SG_ 589 SWA_Obj_05_Breite 0;
BA_ "GenSigStartValue" SG_ 589 SWA_Obj_05_Breite 127;
BA_ "GenSigSendType" SG_ 589 SWA_Obj_05_Existenzwahrsch 0;
BA_ "GenSigStartValue" SG_ 589 SWA_Obj_05_Existenzwahrsch 127;
BA_ "GenSigSendType" SG_ 589 SWA_Obj_05_Gemessen 0;
BA_ "GenSigSendType" SG_ 589 SWA_Obj_05_GeschwRelX 0;
BA_ "GenSigStartValue" SG_ 589 SWA_Obj_05_GeschwRelX 511;
BA_ "GenSigSendType" SG_ 589 SWA_Obj_05_GeschwRelY 0;
BA_ "GenSigStartValue" SG_ 589 SWA_Obj_05_GeschwRelY 511;
BA_ "GenSigSendType" SG_ 589 SWA_Obj_05_ID 0;
BA_ "GenSigStartValue" SG_ 589 SWA_Obj_05_ID 31;
BA_ "GenSigSwitchedByIgnition" SG_ 589 SWA_Obj_05_ID 0;
BA_ "GenSigSendType" SG_ 589 SWA_Obj_05_Laenge 0;
BA_ "GenSigStartValue" SG_ 589 SWA_Obj_05_Laenge 127;
BA_ "GenSigSendType" SG_ 589 SWA_Obj_05_Objektklasse 0;
BA_ "GenSigStartValue" SG_ 589 SWA_Obj_05_Objektklasse 15;
BA_ "GenSigSendType" SG_ 589 SWA_Obj_05_PositionX 0;
BA_ "GenSigStartValue" SG_ 589 SWA_Obj_05_PositionX 511;
BA_ "GenSigSendType" SG_ 589 SWA_Obj_05_PositionY 0;
BA_ "GenSigStartValue" SG_ 589 SWA_Obj_05_PositionY 255;
BA_ "GenSigSendType" SG_ 589 SWA_Obj_05_ReferenzPkt 0;
BA_ "GenSigStartValue" SG_ 589 SWA_Obj_05_ReferenzPkt 15;
BA_ "GenSigSendType" SG_ 589 SWA_Obj_06_Breite 0;
BA_ "GenSigStartValue" SG_ 589 SWA_Obj_06_Breite 127;
BA_ "GenSigSendType" SG_ 589 SWA_Obj_06_Existenzwahrsch 0;
BA_ "GenSigStartValue" SG_ 589 SWA_Obj_06_Existenzwahrsch 127;
BA_ "GenSigSendType" SG_ 589 SWA_Obj_06_Gemessen 0;
BA_ "GenSigSendType" SG_ 589 SWA_Obj_06_GeschwRelX 0;
BA_ "GenSigStartValue" SG_ 589 SWA_Obj_06_GeschwRelX 511;
BA_ "GenSigSendType" SG_ 589 SWA_Obj_06_GeschwRelY 0;
BA_ "GenSigStartValue" SG_ 589 SWA_Obj_06_GeschwRelY 511;
BA_ "GenSigSendType" SG_ 589 SWA_Obj_06_ID 0;
BA_ "GenSigStartValue" SG_ 589 SWA_Obj_06_ID 31;
BA_ "GenSigSwitchedByIgnition" SG_ 589 SWA_Obj_06_ID 0;
BA_ "GenSigSendType" SG_ 589 SWA_Obj_06_Laenge 0;
BA_ "GenSigStartValue" SG_ 589 SWA_Obj_06_Laenge 127;
BA_ "GenSigSendType" SG_ 589 SWA_Obj_06_Objektklasse 0;
BA_ "GenSigStartValue" SG_ 589 SWA_Obj_06_Objektklasse 15;
BA_ "GenSigSendType" SG_ 589 SWA_Obj_06_PositionX 0;
BA_ "GenSigStartValue" SG_ 589 SWA_Obj_06_PositionX 511;
BA_ "GenSigSendType" SG_ 589 SWA_Obj_06_PositionY 0;
BA_ "GenSigStartValue" SG_ 589 SWA_Obj_06_PositionY 255;
BA_ "GenSigSendType" SG_ 589 SWA_Obj_06_ReferenzPkt 0;
BA_ "GenSigStartValue" SG_ 589 SWA_Obj_06_ReferenzPkt 15;
BA_ "GenSigSendType" SG_ 589 SWA_Obj_Kurvenradius 0;
BA_ "GenSigStartValue" SG_ 589 SWA_Obj_Kurvenradius 65535;
BA_ "GenSigSendType" SG_ 589 SWA_StrukturLinks_querAbstand 0;
BA_ "GenSigStartValue" SG_ 589 SWA_StrukturLinks_querAbstand 511;
BA_ "GenSigSendType" SG_ 589 SWA_StrukturLinks_Typ 0;
BA_ "GenSigSendType" SG_ 589 SWA_StrukturRechts_querAbstand 0;
BA_ "GenSigStartValue" SG_ 589 SWA_StrukturRechts_querAbstand 511;
BA_ "GenSigSendType" SG_ 589 SWA_StrukturRechts_Typ 0;
BA_ "GenSigSendType" SG_ 589 SWA_Umfeld_Zeitstempel 0;
BA_ "GenSigStartValue" SG_ 589 SWA_Umfeld_Zeitstempel 65535;
BA_ "GenSigSendType" SG_ 589 SWA_Umfeld_Zeitstempel_Status 0;
BA_ "GenSigStartValue" SG_ 589 SWA_Umfeld_Zeitstempel_Status 7;
BA_ "GenSigSendType" SG_ 589 SWA_Warnung_SWA_li 0;
BA_ "GenSigSendType" SG_ 589 SWA_Warnung_SWA_re 0;
BA_ "GenSigFuncType" SG_ 2635073907 HID_DispKBI_FS_ZR_Req_FD_Data 9;
BA_ "GenSigSendType" SG_ 2635073907 HID_DispKBI_FS_ZR_Req_FD_Data 3;
BA_ "GenSigSwitchedByIgnition" SG_ 2635073907 HID_DispKBI_FS_ZR_Req_FD_Data 0;
BA_ "GenSigFuncType" SG_ 2635204979 HID_DispKBI_FS_ZR_Resp_FD_Data 9;
BA_ "GenSigSendType" SG_ 2635204979 HID_DispKBI_FS_ZR_Resp_FD_Data 3;
BA_ "GenSigSwitchedByIgnition" SG_ 2635204979 HID_DispKBI_FS_ZR_Resp_FD_Data 0;
BA_ "GenSigFuncType" SG_ 2634029939 HID_HUD_ZR_Req_FD_Data 9;
BA_ "GenSigSendType" SG_ 2634029939 HID_HUD_ZR_Req_FD_Data 3;
BA_ "GenSigSwitchedByIgnition" SG_ 2634029939 HID_HUD_ZR_Req_FD_Data 0;
BA_ "GenSigFuncType" SG_ 2634161011 HID_HUD_ZR_Resp_FD_Data 9;
BA_ "GenSigSendType" SG_ 2634161011 HID_HUD_ZR_Resp_FD_Data 3;
BA_ "GenSigSwitchedByIgnition" SG_ 2634161011 HID_HUD_ZR_Resp_FD_Data 0;
BA_ "GenSigFuncType" SG_ 2634314505 HID_ZR_DispKBI_FS_Req_FD_Data 9;
BA_ "GenSigSendType" SG_ 2634314505 HID_ZR_DispKBI_FS_Req_FD_Data 3;
BA_ "GenSigSwitchedByIgnition" SG_ 2634314505 HID_ZR_DispKBI_FS_Req_FD_Data 0;
BA_ "GenSigFuncType" SG_ 2634445577 HID_ZR_DispKBI_FS_Resp_FD_Data 9;
BA_ "GenSigSendType" SG_ 2634445577 HID_ZR_DispKBI_FS_Resp_FD_Data 3;
BA_ "GenSigSwitchedByIgnition" SG_ 2634445577 HID_ZR_DispKBI_FS_Resp_FD_Data 0;
BA_ "GenSigFuncType" SG_ 2634052379 HID_ZR_HUD_Req_FD_Data 9;
BA_ "GenSigSendType" SG_ 2634052379 HID_ZR_HUD_Req_FD_Data 3;
BA_ "GenSigSwitchedByIgnition" SG_ 2634052379 HID_ZR_HUD_Req_FD_Data 0;
BA_ "GenSigFuncType" SG_ 2634183451 HID_ZR_HUD_Resp_FD_Data 9;
BA_ "GenSigSendType" SG_ 2634183451 HID_ZR_HUD_Resp_FD_Data 3;
BA_ "GenSigSwitchedByIgnition" SG_ 2634183451 HID_ZR_HUD_Resp_FD_Data 0;
BA_ "GenSigFuncType" SG_ 2629835579 HUD_ARC_Req_FD_Data 9;
BA_ "GenSigSendType" SG_ 2629835579 HUD_ARC_Req_FD_Data 3;
BA_ "GenSigSwitchedByIgnition" SG_ 2629835579 HUD_ARC_Req_FD_Data 0;
BA_ "GenSigFuncType" SG_ 2629966651 HUD_ARC_Resp_FD_Data 9;
BA_ "GenSigSendType" SG_ 2629966651 HUD_ARC_Resp_FD_Data 3;
BA_ "GenSigSwitchedByIgnition" SG_ 2629966651 HUD_ARC_Resp_FD_Data 0;
BA_ "GenSigSendType" SG_ 1283 HV_Bordnetz_aktiv 3;
BA_ "GenSigSwitchedByIgnition" SG_ 1283 HV_Bordnetz_aktiv 0;
BA_ "Fehlerwert" SG_ 1283 HV_Bordnetz_Fehler 1;
BA_ "GenSigSendType" SG_ 1283 HV_Bordnetz_Fehler 3;
BA_ "GenSigSwitchedByIgnition" SG_ 1283 HV_Bordnetz_Fehler 0;
BA_ "GenSigFuncType" SG_ 1283 HVK_01_BZ 1;
BA_ "GenSigSendType" SG_ 1283 HVK_01_BZ 0;
BA_ "GenSigSwitchedByIgnition" SG_ 1283 HVK_01_BZ 0;
BA_ "GenSigFuncType" SG_ 1283 HVK_01_CRC 2;
BA_ "GenSigSendType" SG_ 1283 HVK_01_CRC 0;
BA_ "GenSigSwitchedByIgnition" SG_ 1283 HVK_01_CRC 0;
BA_ "GenSigSendType" SG_ 1283 HVK_AktiveEntladung_Anf 3;
BA_ "GenSigSwitchedByIgnition" SG_ 1283 HVK_AktiveEntladung_Anf 0;
BA_ "GenSigSendType" SG_ 1283 HVK_BMS_Sollmodus 3;
BA_ "GenSigStartValue" SG_ 1283 HVK_BMS_Sollmodus 7;
BA_ "GenSigSwitchedByIgnition" SG_ 1283 HVK_BMS_Sollmodus 0;
BA_ "GenSigSendType" SG_ 1283 HVK_DCDC_Sollmodus 3;
BA_ "GenSigStartValue" SG_ 1283 HVK_DCDC_Sollmodus 7;
BA_ "GenSigSwitchedByIgnition" SG_ 1283 HVK_DCDC_Sollmodus 0;
BA_ "GenSigSendType" SG_ 1283 HVK_EKK_Sollmodus 3;
BA_ "GenSigStartValue" SG_ 1283 HVK_EKK_Sollmodus 7;
BA_ "GenSigSwitchedByIgnition" SG_ 1283 HVK_EKK_Sollmodus 0;
BA_ "Fehlerwert" SG_ 1283 HVK_Gesamtst_Spgfreiheit 3;
BA_ "GenSigSendType" SG_ 1283 HVK_Gesamtst_Spgfreiheit 0;
BA_ "GenSigSwitchedByIgnition" SG_ 1283 HVK_Gesamtst_Spgfreiheit 0;
BA_ "GenSigSendType" SG_ 1283 HVK_HV_Netz_Warnungen 3;
BA_ "GenSigSwitchedByIgnition" SG_ 1283 HVK_HV_Netz_Warnungen 0;
BA_ "GenSigSendType" SG_ 1283 HVK_HVEM_Freigabe 3;
BA_ "GenSigStartValue" SG_ 1283 HVK_HVEM_Freigabe 2;
BA_ "GenSigSwitchedByIgnition" SG_ 1283 HVK_HVEM_Freigabe 0;
BA_ "GenSigSendType" SG_ 1283 HVK_HVLM_Sollmodus 3;
BA_ "GenSigStartValue" SG_ 1283 HVK_HVLM_Sollmodus 7;
BA_ "GenSigSwitchedByIgnition" SG_ 1283 HVK_HVLM_Sollmodus 0;
BA_ "GenSigSendType" SG_ 1283 HVK_HVPTC_Sollmodus 3;
BA_ "GenSigStartValue" SG_ 1283 HVK_HVPTC_Sollmodus 7;
BA_ "GenSigSwitchedByIgnition" SG_ 1283 HVK_HVPTC_Sollmodus 0;
BA_ "GenSigSendType" SG_ 1283 HVK_Iso_Messung_Start 0;
BA_ "GenSigSwitchedByIgnition" SG_ 1283 HVK_Iso_Messung_Start 0;
BA_ "GenSigSendType" SG_ 1283 HVK_Istmodus_Anf 3;
BA_ "GenSigSwitchedByIgnition" SG_ 1283 HVK_Istmodus_Anf 0;
BA_ "GenSigSendType" SG_ 1283 HVK_Ladebereit 3;
BA_ "GenSigSwitchedByIgnition" SG_ 1283 HVK_Ladebereit 0;
BA_ "GenSigSendType" SG_ 1283 HVK_Notabschaltung_Anf 3;
BA_ "GenSigSwitchedByIgnition" SG_ 1283 HVK_Notabschaltung_Anf 0;
BA_ "GenSigSendType" SG_ 1283 HVK_PPulsFreigabe 0;
BA_ "GenSigStartValue" SG_ 1283 HVK_PPulsFreigabe 3;
BA_ "GenSigSwitchedByIgnition" SG_ 1283 HVK_PPulsFreigabe 0;
BA_ "GenSigSendType" SG_ 1283 HVK_TN1_Sollmodus 3;
BA_ "GenSigStartValue" SG_ 1283 HVK_TN1_Sollmodus 3;
BA_ "GenSigSwitchedByIgnition" SG_ 1283 HVK_TN1_Sollmodus 0;
BA_ "GenSigSendType" SG_ 1283 HVK_Vorladung_aktiv 3;
BA_ "GenSigSwitchedByIgnition" SG_ 1283 HVK_Vorladung_aktiv 0;
BA_ "GenSigSendType" SG_ 2527679583 FoD_DTC_IPA_EPH 0;
BA_ "GenSigSwitchedByIgnition" SG_ 2527679583 FoD_DTC_IPA_EPH 0;
BA_ "GenSigSendType" SG_ 2527679583 FoD_DTC_RPA_EPH 0;
BA_ "GenSigSwitchedByIgnition" SG_ 2527679583 FoD_DTC_RPA_EPH 0;
BA_ "GenSigSendType" SG_ 2527679583 FoD_DTC_TPA_rTPA_EPH 0;
BA_ "GenSigSwitchedByIgnition" SG_ 2527679583 FoD_DTC_TPA_rTPA_EPH 0;
BA_ "GenSigFuncType" SG_ 2527679583 IPA_02_BZ 1;
BA_ "GenSigSendType" SG_ 2527679583 IPA_02_BZ 0;
BA_ "GenSigSwitchedByIgnition" SG_ 2527679583 IPA_02_BZ 0;
BA_ "GenSigFuncType" SG_ 2527679583 IPA_02_CRC 2;
BA_ "GenSigSendType" SG_ 2527679583 IPA_02_CRC 0;
BA_ "GenSigSwitchedByIgnition" SG_ 2527679583 IPA_02_CRC 0;
BA_ "GenSigActiveRepetitions" SG_ 2527679583 IPA_Anf_Meldungen 5;
BA_ "GenSigSendType" SG_ 2527679583 IPA_Anf_Meldungen 4;
BA_ "GenSigSwitchedByIgnition" SG_ 2527679583 IPA_Anf_Meldungen 0;
BA_ "GenSigActiveRepetitions" SG_ 2527679583 Parken_aktives_System_02 5;
BA_ "GenSigSendType" SG_ 2527679583 Parken_aktives_System_02 4;
BA_ "GenSigSwitchedByIgnition" SG_ 2527679583 Parken_aktives_System_02 0;
BA_ "GenSigActiveRepetitions" SG_ 2527679583 Parken_Aktivierungslicht_Anf 5;
BA_ "GenSigSendType" SG_ 2527679583 Parken_Aktivierungslicht_Anf 4;
BA_ "GenSigSwitchedByIgnition" SG_ 2527679583 Parken_Aktivierungslicht_Anf 0;
BA_ "GenSigActiveRepetitions" SG_ 2527679583 Parken_Bestaetigungsblinken_Anf 5;
BA_ "GenSigSendType" SG_ 2527679583 Parken_Bestaetigungsblinken_Anf 4;
BA_ "GenSigSwitchedByIgnition" SG_ 2527679583 Parken_Bestaetigungsblinken_Anf 0;
BA_ "GenSigActiveRepetitions" SG_ 2527679583 Parken_Fahrbereitschaftlicht_Anf 5;
BA_ "GenSigSendType" SG_ 2527679583 Parken_Fahrbereitschaftlicht_Anf 4;
BA_ "GenSigActiveRepetitions" SG_ 2527679583 Parken_Fahrerhinweise_Anf 5;
BA_ "GenSigSendType" SG_ 2527679583 Parken_Fahrerhinweise_Anf 4;
BA_ "GenSigSwitchedByIgnition" SG_ 2527679583 Parken_Fahrerhinweise_Anf 0;
BA_ "GenSigActiveRepetitions" SG_ 2527679583 Parken_Fahrtrichtungslicht_Anf 5;
BA_ "GenSigSendType" SG_ 2527679583 Parken_Fahrtrichtungslicht_Anf 4;
BA_ "GenSigActiveRepetitions" SG_ 2527679583 Parken_FFB_LED_Anf 5;
BA_ "GenSigSendType" SG_ 2527679583 Parken_FFB_LED_Anf 4;
BA_ "GenSigActiveRepetitions" SG_ 2527679583 Parken_Lichtnachlauf_Anf 5;
BA_ "GenSigSendType" SG_ 2527679583 Parken_Lichtnachlauf_Anf 4;
BA_ "GenSigActiveRepetitions" SG_ 2527679583 Parken_Lichtsteuerung_Anf 5;
BA_ "GenSigSendType" SG_ 2527679583 Parken_Lichtsteuerung_Anf 4;
BA_ "GenSigSwitchedByIgnition" SG_ 2527679583 Parken_Lichtsteuerung_Anf 0;
BA_ "GenSigActiveRepetitions" SG_ 2527679583 Parken_Schluesselsuche_Anf 5;
BA_ "GenSigSendType" SG_ 2527679583 Parken_Schluesselsuche_Anf 4;
BA_ "GenSigActiveRepetitions" SG_ 2527679583 Parken_Seitenspiegel_Anf 5;
BA_ "GenSigSendType" SG_ 2527679583 Parken_Seitenspiegel_Anf 4;
BA_ "GenSigActiveRepetitions" SG_ 2527679583 Parken_Wegfahrsperren_Anf 5;
BA_ "GenSigSendType" SG_ 2527679583 Parken_Wegfahrsperren_Anf 4;
BA_ "GenSigActiveRepetitions" SG_ 2527679583 Parken_ZR_Sondermodus_Anf 5;
BA_ "GenSigSendType" SG_ 2527679583 Parken_ZR_Sondermodus_Anf 4;
BA_ "GenSigSwitchedByIgnition" SG_ 2527679583 Parken_ZR_Sondermodus_Anf 0;
BA_ "GenSigActiveRepetitions" SG_ 2527679583 Parken_ZV_Schliessen 5;
BA_ "GenSigSendType" SG_ 2527679583 Parken_ZV_Schliessen 4;
BA_ "GenSigSendType" SG_ 2527679583 RA_Anf_Meldung 3;
BA_ "GenSigSwitchedByIgnition" SG_ 2527679583 RA_Anf_Meldung 0;
BA_ "GenSigFuncType" SG_ 1792 ISO_ALL_01_Req_Data 9;
BA_ "GenSigSendType" SG_ 1792 ISO_ALL_01_Req_Data 3;
BA_ "GenSigSwitchedByIgnition" SG_ 1792 ISO_ALL_01_Req_Data 0;
BA_ "GenSigFuncType" SG_ 1819 ISO_HUD_Req_Data 9;
BA_ "GenSigSendType" SG_ 1819 ISO_HUD_Req_Data 3;
BA_ "GenSigSwitchedByIgnition" SG_ 1819 ISO_HUD_Req_Data 0;
BA_ "GenSigFuncType" SG_ 1925 ISO_HUD_Resp_Data 9;
BA_ "GenSigSendType" SG_ 1925 ISO_HUD_Resp_Data 3;
BA_ "GenSigSwitchedByIgnition" SG_ 1925 ISO_HUD_Resp_Data 0;
BA_ "GenSigFuncType" SG_ 1812 ISO_Kombi_Req_Data 9;
BA_ "GenSigSendType" SG_ 1812 ISO_Kombi_Req_Data 3;
BA_ "GenSigSwitchedByIgnition" SG_ 1812 ISO_Kombi_Req_Data 0;
BA_ "GenSigFuncType" SG_ 1918 ISO_Kombi_Resp_Data 9;
BA_ "GenSigSendType" SG_ 1918 ISO_Kombi_Resp_Data 3;
BA_ "GenSigSwitchedByIgnition" SG_ 1918 ISO_Kombi_Resp_Data 0;
BA_ "GenSigFuncType" SG_ 2549358366 ISO_NFCIApp_NFCIServ_Req_Data 9;
BA_ "GenSigSendType" SG_ 2549358366 ISO_NFCIApp_NFCIServ_Req_Data 3;
BA_ "GenSigSwitchedByIgnition" SG_ 2549358366 ISO_NFCIApp_NFCIServ_Req_Data 0;
BA_ "GenSigFuncType" SG_ 2549489183 ISO_NFCIApp_NFCIServ_Resp_Data 9;
BA_ "GenSigSendType" SG_ 2549489183 ISO_NFCIApp_NFCIServ_Resp_Data 3;
BA_ "GenSigSwitchedByIgnition" SG_ 2549489183 ISO_NFCIApp_NFCIServ_Resp_Data 0;
BA_ "GenSigFuncType" SG_ 2549358111 ISO_NFCIServ_NFCIApp_Req_Data 9;
BA_ "GenSigSendType" SG_ 2549358111 ISO_NFCIServ_NFCIApp_Req_Data 3;
BA_ "GenSigSwitchedByIgnition" SG_ 2549358111 ISO_NFCIServ_NFCIApp_Req_Data 0;
BA_ "GenSigFuncType" SG_ 2549489438 ISO_NFCIServ_NFCIApp_Resp_Data 9;
BA_ "GenSigSendType" SG_ 2549489438 ISO_NFCIServ_NFCIApp_Resp_Data 3;
BA_ "GenSigSwitchedByIgnition" SG_ 2549489438 ISO_NFCIServ_NFCIApp_Resp_Data 0;
BA_ "GenSigFuncType" SG_ 1901 ISO_TV_Tuner_Req_Data 9;
BA_ "GenSigSendType" SG_ 1901 ISO_TV_Tuner_Req_Data 3;
BA_ "GenSigSwitchedByIgnition" SG_ 1901 ISO_TV_Tuner_Req_Data 0;
BA_ "GenSigFuncType" SG_ 2007 ISO_TV_Tuner_Resp_Data 9;
BA_ "GenSigSendType" SG_ 2007 ISO_TV_Tuner_Resp_Data 3;
BA_ "GenSigSwitchedByIgnition" SG_ 2007 ISO_TV_Tuner_Resp_Data 0;
BA_ "GenSigFuncType" SG_ 2550398985 ISOx_DispKBI_FS_Req_Data 9;
BA_ "GenSigSendType" SG_ 2550398985 ISOx_DispKBI_FS_Req_Data 3;
BA_ "GenSigSwitchedByIgnition" SG_ 2550398985 ISOx_DispKBI_FS_Req_Data 0;
BA_ "GenSigFuncType" SG_ 2621702153 ISOx_DispKBI_FS_Req_FD_Data 9;
BA_ "GenSigSendType" SG_ 2621702153 ISOx_DispKBI_FS_Req_FD_Data 3;
BA_ "GenSigSwitchedByIgnition" SG_ 2621702153 ISOx_DispKBI_FS_Req_FD_Data 0;
BA_ "GenSigFuncType" SG_ 2550530057 ISOx_DispKBI_FS_Resp_Data 9;
BA_ "GenSigSendType" SG_ 2550530057 ISOx_DispKBI_FS_Resp_Data 3;
BA_ "GenSigSwitchedByIgnition" SG_ 2550530057 ISOx_DispKBI_FS_Resp_Data 0;
BA_ "GenSigFuncType" SG_ 2621833225 ISOx_DispKBI_FS_Resp_FD_Data 9;
BA_ "GenSigSendType" SG_ 2621833225 ISOx_DispKBI_FS_Resp_FD_Data 3;
BA_ "GenSigSwitchedByIgnition" SG_ 2621833225 ISOx_DispKBI_FS_Resp_FD_Data 0;
BA_ "GenSigFuncType" SG_ 2621505536 ISOx_Funkt_Req_All_FD_Data 9;
BA_ "GenSigSendType" SG_ 2621505536 ISOx_Funkt_Req_All_FD_Data 3;
BA_ "GenSigSwitchedByIgnition" SG_ 2621505536 ISOx_Funkt_Req_All_FD_Data 0;
BA_ "GenSigFuncType" SG_ 2621440027 ISOx_HUD_Req_FD_Data 9;
BA_ "GenSigSendType" SG_ 2621440027 ISOx_HUD_Req_FD_Data 3;
BA_ "GenSigSwitchedByIgnition" SG_ 2621440027 ISOx_HUD_Req_FD_Data 0;
BA_ "GenSigFuncType" SG_ 2621571099 ISOx_HUD_Resp_FD_Data 9;
BA_ "GenSigSendType" SG_ 2621571099 ISOx_HUD_Resp_FD_Data 3;
BA_ "GenSigSwitchedByIgnition" SG_ 2621571099 ISOx_HUD_Resp_FD_Data 0;
BA_ "GenSigFuncType" SG_ 2621440020 ISOx_Kombi_Req_FD_Data 9;
BA_ "GenSigSendType" SG_ 2621440020 ISOx_Kombi_Req_FD_Data 3;
BA_ "GenSigSwitchedByIgnition" SG_ 2621440020 ISOx_Kombi_Req_FD_Data 0;
BA_ "GenSigFuncType" SG_ 2621571092 ISOx_Kombi_Resp_FD_Data 9;
BA_ "GenSigSendType" SG_ 2621571092 ISOx_Kombi_Resp_FD_Data 3;
BA_ "GenSigSwitchedByIgnition" SG_ 2621571092 ISOx_Kombi_Resp_FD_Data 0;
BA_ "GenSigFuncType" SG_ 2550398988 ISOx_SmLi_01_Req_Data 9;
BA_ "GenSigSendType" SG_ 2550398988 ISOx_SmLi_01_Req_Data 3;
BA_ "GenSigSwitchedByIgnition" SG_ 2550398988 ISOx_SmLi_01_Req_Data 0;
BA_ "GenSigFuncType" SG_ 2621702156 ISOx_SmLi_01_Req_FD_Data 9;
BA_ "GenSigSendType" SG_ 2621702156 ISOx_SmLi_01_Req_FD_Data 3;
BA_ "GenSigSwitchedByIgnition" SG_ 2621702156 ISOx_SmLi_01_Req_FD_Data 0;
BA_ "GenSigFuncType" SG_ 2550530060 ISOx_SmLi_01_Resp_Data 9;
BA_ "GenSigSendType" SG_ 2550530060 ISOx_SmLi_01_Resp_Data 3;
BA_ "GenSigSwitchedByIgnition" SG_ 2550530060 ISOx_SmLi_01_Resp_Data 0;
BA_ "GenSigFuncType" SG_ 2621833228 ISOx_SmLi_01_Resp_FD_Data 9;
BA_ "GenSigSendType" SG_ 2621833228 ISOx_SmLi_01_Resp_FD_Data 3;
BA_ "GenSigSwitchedByIgnition" SG_ 2621833228 ISOx_SmLi_01_Resp_FD_Data 0;
BA_ "GenSigFuncType" SG_ 2549874853 ISOx_WLC1_Req_Data 9;
BA_ "GenSigSendType" SG_ 2549874853 ISOx_WLC1_Req_Data 3;
BA_ "GenSigSwitchedByIgnition" SG_ 2549874853 ISOx_WLC1_Req_Data 0;
BA_ "GenSigFuncType" SG_ 2550005925 ISOx_WLC1_Resp_Data 9;
BA_ "GenSigSendType" SG_ 2550005925 ISOx_WLC1_Resp_Data 3;
BA_ "GenSigSwitchedByIgnition" SG_ 2550005925 ISOx_WLC1_Resp_Data 0;
BA_ "GenSigSendType" SG_ 1426 KY_Aktive_LFScans 3;
BA_ "GenSigSwitchedByIgnition" SG_ 1426 KY_Aktive_LFScans 0;
BA_ "GenSigSendType" SG_ 1426 KY_AnzKoord_Info 3;
BA_ "GenSigSwitchedByIgnition" SG_ 1426 KY_AnzKoord_Info 0;
BA_ "GenSigSendType" SG_ 1426 KY_EasyClose_Abbruch 3;
BA_ "GenSigSwitchedByIgnition" SG_ 1426 KY_EasyClose_Abbruch 0;
BA_ "GenSigSendType" SG_ 1426 KY_EasyClose_Status 3;
BA_ "GenSigSwitchedByIgnition" SG_ 1426 KY_EasyClose_Status 0;
BA_ "GenSigSendType" SG_ 1426 KY_Fzg_Verlassen_erkannt 3;
BA_ "GenSigSwitchedByIgnition" SG_ 1426 KY_Fzg_Verlassen_erkannt 0;
BA_ "GenSigSendType" SG_ 1426 KY_Fzg_Zugang_erkannt 3;
BA_ "GenSigSwitchedByIgnition" SG_ 1426 KY_Fzg_Zugang_erkannt 0;
BA_ "GenSigSendType" SG_ 1426 KY_Gestik_HD 3;
BA_ "GenSigSwitchedByIgnition" SG_ 1426 KY_Gestik_HD 0;
BA_ "GenSigSendType" SG_ 1426 KY_Gong_600 3;
BA_ "GenSigSwitchedByIgnition" SG_ 1426 KY_Gong_600 0;
BA_ "GenSigSendType" SG_ 1426 KY_HD_Auffahrt 3;
BA_ "GenSigSwitchedByIgnition" SG_ 1426 KY_HD_Auffahrt 0;
BA_ "GenSigSendType" SG_ 1426 KY_HD_Zufahrt 3;
BA_ "GenSigSwitchedByIgnition" SG_ 1426 KY_HD_Zufahrt 0;
BA_ "GenSigSendType" SG_ 1426 KY_ID_Geber1_im_Fzg 3;
BA_ "GenSigSwitchedByIgnition" SG_ 1426 KY_ID_Geber1_im_Fzg 0;
BA_ "GenSigSendType" SG_ 1426 KY_ID_Geber2_im_Fzg 3;
BA_ "GenSigSwitchedByIgnition" SG_ 1426 KY_ID_Geber2_im_Fzg 0;
BA_ "GenSigSendType" SG_ 1426 KY_ID_Geber3_im_Fzg 3;
BA_ "GenSigSwitchedByIgnition" SG_ 1426 KY_ID_Geber3_im_Fzg 0;
BA_ "GenSigSendType" SG_ 1426 KY_ID_Geber4_im_Fzg 3;
BA_ "GenSigSwitchedByIgnition" SG_ 1426 KY_ID_Geber4_im_Fzg 0;
BA_ "GenSigSendType" SG_ 1426 KY_ID_Geber_Suche 3;
BA_ "GenSigSwitchedByIgnition" SG_ 1426 KY_ID_Geber_Suche 0;
BA_ "GenSigSendType" SG_ 1426 KY_LF_Aktiv 3;
BA_ "GenSigSwitchedByIgnition" SG_ 1426 KY_LF_Aktiv 0;
BA_ "GenSigSendType" SG_ 1426 KY_Meldungen 3;
BA_ "GenSigSwitchedByIgnition" SG_ 1426 KY_Meldungen 0;
BA_ "GenSigSendType" SG_ 1426 KY_Passiv_Autolock 3;
BA_ "GenSigSwitchedByIgnition" SG_ 1426 KY_Passiv_Autolock 0;
BA_ "GenSigSendType" SG_ 1426 KY_Passiv_Autolock_Akt 3;
BA_ "GenSigSwitchedByIgnition" SG_ 1426 KY_Passiv_Autolock_Akt 0;
BA_ "GenSigSendType" SG_ 1426 KY_Passiv_Autolock_Menue 3;
BA_ "GenSigSwitchedByIgnition" SG_ 1426 KY_Passiv_Autolock_Menue 0;
BA_ "GenSigSendType" SG_ 1426 KY_Passiv_Autounlock 3;
BA_ "GenSigSwitchedByIgnition" SG_ 1426 KY_Passiv_Autounlock 0;
BA_ "GenSigSendType" SG_ 1426 KY_Schluesselposition_1 3;
BA_ "GenSigSwitchedByIgnition" SG_ 1426 KY_Schluesselposition_1 0;
BA_ "GenSigSendType" SG_ 1426 KY_Schluesselposition_2 3;
BA_ "GenSigSwitchedByIgnition" SG_ 1426 KY_Schluesselposition_2 0;
BA_ "GenSigSendType" SG_ 1426 KY_Schluesselposition_3 3;
BA_ "GenSigSwitchedByIgnition" SG_ 1426 KY_Schluesselposition_3 0;
BA_ "GenSigSendType" SG_ 1426 KY_Schluesselposition_4 3;
BA_ "GenSigSwitchedByIgnition" SG_ 1426 KY_Schluesselposition_4 0;
BA_ "GenSigSendType" SG_ 1426 KY_Schluesselposition_5 3;
BA_ "GenSigSwitchedByIgnition" SG_ 1426 KY_Schluesselposition_5 0;
BA_ "GenSigSendType" SG_ 1426 KY_Schluesselposition_6 3;
BA_ "GenSigSwitchedByIgnition" SG_ 1426 KY_Schluesselposition_6 0;
BA_ "GenSigSendType" SG_ 1426 KY_Schluesselposition_7 3;
BA_ "GenSigSwitchedByIgnition" SG_ 1426 KY_Schluesselposition_7 0;
BA_ "GenSigSendType" SG_ 1426 KY_Schluesselposition_8 3;
BA_ "GenSigSwitchedByIgnition" SG_ 1426 KY_Schluesselposition_8 0;
BA_ "GenSigSendType" SG_ 1426 KY_Schluesselposition_9 3;
BA_ "GenSigSwitchedByIgnition" SG_ 1426 KY_Schluesselposition_9 0;
BA_ "GenSigSendType" SG_ 1426 KY_Startknopf_Bel 3;
BA_ "GenSigSwitchedByIgnition" SG_ 1426 KY_Startknopf_Bel 0;
BA_ "GenSigSendType" SG_ 1426 KY_StartStopp_Info 3;
BA_ "GenSigSwitchedByIgnition" SG_ 1426 KY_StartStopp_Info 0;
BA_ "GenSigSendType" SG_ 960 BCM_Ausparken_Betrieb 3;
BA_ "GenSigSwitchedByIgnition" SG_ 960 BCM_Ausparken_Betrieb 0;
BA_ "GenSigFuncType" SG_ 960 Klemmen_Status_01_BZ 1;
BA_ "GenSigSendType" SG_ 960 Klemmen_Status_01_BZ 0;
BA_ "GenSigSwitchedByIgnition" SG_ 960 Klemmen_Status_01_BZ 0;
BA_ "GenSigFuncType" SG_ 960 Klemmen_Status_01_CRC 2;
BA_ "GenSigSendType" SG_ 960 Klemmen_Status_01_CRC 0;
BA_ "GenSigSwitchedByIgnition" SG_ 960 Klemmen_Status_01_CRC 0;
BA_ "GenSigSendType" SG_ 960 KST_Fahrerhinweis_1 3;
BA_ "GenSigSwitchedByIgnition" SG_ 960 KST_Fahrerhinweis_1 0;
BA_ "GenSigSendType" SG_ 960 KST_Fahrerhinweis_2 3;
BA_ "GenSigSwitchedByIgnition" SG_ 960 KST_Fahrerhinweis_2 0;
BA_ "GenSigSendType" SG_ 960 KST_Fahrerhinweis_4 3;
BA_ "GenSigSwitchedByIgnition" SG_ 960 KST_Fahrerhinweis_4 0;
BA_ "GenSigSendType" SG_ 960 KST_Fahrerhinweis_5 3;
BA_ "GenSigSwitchedByIgnition" SG_ 960 KST_Fahrerhinweis_5 0;
BA_ "GenSigSendType" SG_ 960 KST_Fahrerhinweis_6 3;
BA_ "GenSigSwitchedByIgnition" SG_ 960 KST_Fahrerhinweis_6 0;
BA_ "GenSigSendType" SG_ 960 KST_Warn_P1_ZST_def 3;
BA_ "GenSigSwitchedByIgnition" SG_ 960 KST_Warn_P1_ZST_def 0;
BA_ "GenSigSendType" SG_ 960 KST_Warn_P2_ZST_def 3;
BA_ "GenSigSwitchedByIgnition" SG_ 960 KST_Warn_P2_ZST_def 0;
BA_ "GenSigSendType" SG_ 960 RSt_Fahrerhinweise 3;
BA_ "GenSigSwitchedByIgnition" SG_ 960 RSt_Fahrerhinweise 0;
BA_ "GenSigFuncType" SG_ 960 ZAS_Kl_15 6;
BA_ "GenSigSendType" SG_ 960 ZAS_Kl_15 3;
BA_ "GenSigSwitchedByIgnition" SG_ 960 ZAS_Kl_15 0;
BA_ "NWM-WakeupAllowed" SG_ 960 ZAS_Kl_15 1;
BA_ "GenSigSendType" SG_ 960 ZAS_Kl_50_Startanforderung 3;
BA_ "GenSigSwitchedByIgnition" SG_ 960 ZAS_Kl_50_Startanforderung 0;
BA_ "GenSigSendType" SG_ 960 ZAS_Kl_Infotainment 3;
BA_ "GenSigSwitchedByIgnition" SG_ 960 ZAS_Kl_Infotainment 0;
BA_ "GenSigSendType" SG_ 960 ZAS_Kl_S 3;
BA_ "GenSigSwitchedByIgnition" SG_ 960 ZAS_Kl_S 0;
BA_ "GenSigSendType" SG_ 960 ZAS_Kl_X 3;
BA_ "GenSigSwitchedByIgnition" SG_ 960 ZAS_Kl_X 0;
BA_ "GenSigFuncType" SG_ 2463978753 Klemmen_Status_02_BZ 1;
BA_ "GenSigSendType" SG_ 2463978753 Klemmen_Status_02_BZ 0;
BA_ "GenSigSwitchedByIgnition" SG_ 2463978753 Klemmen_Status_02_BZ 0;
BA_ "GenSigFuncType" SG_ 2463978753 Klemmen_Status_02_CRC 2;
BA_ "GenSigSendType" SG_ 2463978753 Klemmen_Status_02_CRC 0;
BA_ "GenSigSwitchedByIgnition" SG_ 2463978753 Klemmen_Status_02_CRC 0;
BA_ "GenSigSendType" SG_ 2463978753 KST_ComfortReadyStatus 4;
BA_ "GenSigSwitchedByIgnition" SG_ 2463978753 KST_ComfortReadyStatus 0;
BA_ "Fehlerwert" SG_ 2463978753 KST_Sonderzustand_Anforderung 31;
BA_ "GenSigSendType" SG_ 2463978753 KST_Sonderzustand_Anforderung 4;
BA_ "GenSigSwitchedByIgnition" SG_ 2463978753 KST_Sonderzustand_Anforderung 0;
BA_ "Fehlerwert" SG_ 2463978753 KST_Sonderzustand_Status 3;
BA_ "GenSigSendType" SG_ 2463978753 KST_Sonderzustand_Status 4;
BA_ "GenSigSwitchedByIgnition" SG_ 2463978753 KST_Sonderzustand_Status 0;
BA_ "GenSigSendType" SG_ 2463978753 KST_WFS_Fahrfreigabe_Anforderung 4;
BA_ "GenSigSwitchedByIgnition" SG_ 2463978753 KST_WFS_Fahrfreigabe_Anforderung 0;
BA_ "GenSigFuncType" SG_ 1420 Klemmen_Steuerung_01_BZ 1;
BA_ "GenSigSendType" SG_ 1420 Klemmen_Steuerung_01_BZ 0;
BA_ "GenSigSwitchedByIgnition" SG_ 1420 Klemmen_Steuerung_01_BZ 0;
BA_ "GenSigFuncType" SG_ 1420 Klemmen_Steuerung_01_CRC 2;
BA_ "GenSigSendType" SG_ 1420 Klemmen_Steuerung_01_CRC 0;
BA_ "GenSigSwitchedByIgnition" SG_ 1420 Klemmen_Steuerung_01_CRC 0;
BA_ "GenSigSendType" SG_ 1420 KST_Anf_Klemme_15 4;
BA_ "GenSigSwitchedByIgnition" SG_ 1420 KST_Anf_Klemme_15 0;
BA_ "GenSigSendType" SG_ 1420 KST_Anf_Klemme_50 4;
BA_ "GenSigSwitchedByIgnition" SG_ 1420 KST_Anf_Klemme_50 0;
BA_ "GenSigSendType" SG_ 1420 KST_Anf_Klemme_S 3;
BA_ "GenSigSwitchedByIgnition" SG_ 1420 KST_Anf_Klemme_S 0;
BA_ "GenSigSendType" SG_ 1420 KST_Anf_Klemmenfreigabe_ELV 3;
BA_ "GenSigSwitchedByIgnition" SG_ 1420 KST_Anf_Klemmenfreigabe_ELV 0;
BA_ "GenSigSendType" SG_ 1420 KST_Anf_Klemmenfreigabe_WFS 3;
BA_ "GenSigSwitchedByIgnition" SG_ 1420 KST_Anf_Klemmenfreigabe_WFS 0;
BA_ "GenSigSendType" SG_ 1420 KST_Anf_ZV_Verriegelung 3;
BA_ "GenSigSwitchedByIgnition" SG_ 1420 KST_Anf_ZV_Verriegelung 0;
BA_ "GenSigSendType" SG_ 1420 KST_aut_Abschaltung_Zuendung 4;
BA_ "GenSigSwitchedByIgnition" SG_ 1420 KST_aut_Abschaltung_Zuendung 0;
BA_ "GenSigSendType" SG_ 1420 KST_Fahrer_Info_Text 3;
BA_ "GenSigSwitchedByIgnition" SG_ 1420 KST_Fahrer_Info_Text 0;
BA_ "GenSigSendType" SG_ 1420 KST_KL15LockStatus 0;
BA_ "GenSigSwitchedByIgnition" SG_ 1420 KST_KL15LockStatus 0;
BA_ "GenSigSendType" SG_ 1420 KST_Txt_Komfortabschaltung 3;
BA_ "GenSigSwitchedByIgnition" SG_ 1420 KST_Txt_Komfortabschaltung 0;
BA_ "GenSigSendType" SG_ 1420 KST_Txt_P_Gang 3;
BA_ "GenSigSwitchedByIgnition" SG_ 1420 KST_Txt_P_Gang 0;
BA_ "GenSigSendType" SG_ 1420 KST_Txt_Panikabschaltung 3;
BA_ "GenSigSwitchedByIgnition" SG_ 1420 KST_Txt_Panikabschaltung 0;
BA_ "GenSigSendType" SG_ 1420 KST_Txt_Werkstatt 3;
BA_ "GenSigSwitchedByIgnition" SG_ 1420 KST_Txt_Werkstatt 0;
BA_ "GenSigSendType" SG_ 1420 KST_Unterdr_Zuendungsmeldung 3;
BA_ "GenSigSwitchedByIgnition" SG_ 1420 KST_Unterdr_Zuendungsmeldung 0;
BA_ "GenSigSendType" SG_ 1420 KST_ZAT_betaetigt 3;
BA_ "GenSigSwitchedByIgnition" SG_ 1420 KST_ZAT_betaetigt 0;
BA_ "GenSigSendType" SG_ 1420 KST_Zuendungswarnung 4;
BA_ "GenSigSwitchedByIgnition" SG_ 1420 KST_Zuendungswarnung 0;
BA_ "GenSigSendType" SG_ 1420 Relais_VoKo_angesteuert 3;
BA_ "GenSigSwitchedByIgnition" SG_ 1420 Relais_VoKo_angesteuert 0;
BA_ "GenSigSendType" SG_ 1420 RSt_Anforderung_HMS 3;
BA_ "GenSigSwitchedByIgnition" SG_ 1420 RSt_Anforderung_HMS 0;
BA_REL_ "GenSigTimeoutTime" BU_SG_REL_ Fahrerdisplay_Kombi SG_ 324 GE_Ausleuchtung_Fahrstufe 500;
BA_REL_ "GenSigTimeoutTime" BU_SG_REL_ Fahrerdisplay_Kombi SG_ 324 Getriebe_16_BZ 500;
BA_REL_ "GenSigTimeoutTime" BU_SG_REL_ Fahrerdisplay_Kombi SG_ 324 Getriebe_16_CRC 500;
BA_REL_ "GenSigTimeoutTime" BU_SG_REL_ Fahrerdisplay_Kombi SG_ 960 ZAS_Kl_15 1000;
BA_REL_ "GenSigTimeoutTime" BU_SG_REL_ Fahrerdisplay_Kombi SG_ 1283 HVK_01_BZ 1000;
BA_REL_ "GenSigTimeoutTime" BU_SG_REL_ Fahrerdisplay_Kombi SG_ 1283 HVK_01_CRC 1000;
BA_REL_ "GenSigTimeoutTime" BU_SG_REL_ Fahrerdisplay_Kombi SG_ 1283 HVK_HV_Netz_Warnungen 1000;
BA_REL_ "GenSigTimeoutTime" BU_SG_REL_ Fahrerdisplay_Kombi SG_ 2589283617 DBK_Fahrerwarnung 5000;
BA_REL_ "GenSigTimeoutTime" BU_SG_REL_ Fahrerdisplay_Kombi SG_ 2589283617 ESP_30_BZ 5000;
BA_REL_ "GenSigTimeoutTime" BU_SG_REL_ Fahrerdisplay_Kombi SG_ 2589283617 ESP_30_CRC 5000;
BA_REL_ "GenSigTimeoutTime" BU_SG_REL_ HUD SG_ 960 ZAS_Kl_15 1000;
BA_REL_ "GenSigTimeoutTime" BU_SG_REL_ HUD SG_ 960 ZAS_Kl_S 1000;
BA_REL_ "GenSigTimeoutTime" BU_SG_REL_ ICAS3_Gateway SG_ 588 ASW_Ton_Richtung_HL 500;
BA_REL_ "GenSigTimeoutTime" BU_SG_REL_ ICAS3_Gateway SG_ 588 ASW_Ton_Richtung_HR 500;
BA_REL_ "GenSigTimeoutTime" BU_SG_REL_ ICAS3_Gateway SG_ 588 ASW_Ton_Richtung_VL 500;
BA_REL_ "GenSigTimeoutTime" BU_SG_REL_ ICAS3_Gateway SG_ 588 ASW_Ton_Richtung_VR 500;
BA_REL_ "GenSigTimeoutTime" BU_SG_REL_ ICAS3_Gateway SG_ 960 ZAS_Kl_15 1000;
BA_REL_ "GenSigTimeoutTime" BU_SG_REL_ ICAS3_Gateway SG_ 960 ZAS_Kl_S 1000;
BA_REL_ "GenSigTimeoutTime" BU_SG_REL_ ICAS3_Gateway SG_ 960 ZAS_Kl_X 1000;
BA_REL_ "GenSigTimeoutTime" BU_SG_REL_ ICAS3_Gateway SG_ 988 ESP_07_alt 500;
BA_REL_ "GenSigTimeoutTime" BU_SG_REL_ ICAS3_Gateway SG_ 988 ESP_Rollenmodus_Deaktivieren 500;
BA_REL_ "GenSigTimeoutTime" BU_SG_REL_ ICAS3_Gateway SG_ 2589283684 FoD_Transmission_Info 5000;
BA_REL_ "GenSigTimeoutTime" BU_SG_REL_ ICC_IO_Node SG_ 960 ZAS_Kl_15 1000;
BA_REL_ "GenSigTimeoutTime" BU_SG_REL_ ICC_IO_Node SG_ 960 ZAS_Kl_S 1000;
BA_REL_ "GenSigTimeoutTime" BU_SG_REL_ Kombi SG_ 324 GE_Ausleuchtung_Fahrstufe 500;
BA_REL_ "GenSigTimeoutTime" BU_SG_REL_ Kombi SG_ 324 Getriebe_16_BZ 500;
BA_REL_ "GenSigTimeoutTime" BU_SG_REL_ Kombi SG_ 324 Getriebe_16_CRC 500;
BA_REL_ "GenSigTimeoutTime" BU_SG_REL_ Kombi SG_ 588 ASW_Kombitexte 500;
BA_REL_ "GenSigTimeoutTime" BU_SG_REL_ Kombi SG_ 588 HRE_Anzeigetexte 500;
BA_REL_ "GenSigTimeoutTime" BU_SG_REL_ Kombi SG_ 588 Heckradar_Kombitexte 500;
BA_REL_ "GenSigTimeoutTime" BU_SG_REL_ Kombi SG_ 588 RCTA_Kombitexte 500;
BA_REL_ "GenSigTimeoutTime" BU_SG_REL_ Kombi SG_ 588 SWA_Anzeigen 500;
BA_REL_ "GenSigTimeoutTime" BU_SG_REL_ Kombi SG_ 588 SWA_Sta_aktiv 500;
BA_REL_ "GenSigTimeoutTime" BU_SG_REL_ Kombi SG_ 588 SWA_Sta_passiv 500;
BA_REL_ "GenSigTimeoutTime" BU_SG_REL_ Kombi SG_ 589 SWA_Infostufe_SWA_li 500;
BA_REL_ "GenSigTimeoutTime" BU_SG_REL_ Kombi SG_ 589 SWA_Infostufe_SWA_re 500;
BA_REL_ "GenSigTimeoutTime" BU_SG_REL_ Kombi SG_ 589 SWA_Warnung_SWA_li 500;
BA_REL_ "GenSigTimeoutTime" BU_SG_REL_ Kombi SG_ 589 SWA_Warnung_SWA_re 500;
BA_REL_ "GenSigTimeoutTime" BU_SG_REL_ Kombi SG_ 960 Klemmen_Status_01_BZ 1000;
BA_REL_ "GenSigTimeoutTime" BU_SG_REL_ Kombi SG_ 960 Klemmen_Status_01_CRC 1000;
BA_REL_ "GenSigTimeoutTime" BU_SG_REL_ Kombi SG_ 960 ZAS_Kl_15 1000;
BA_REL_ "GenSigTimeoutTime" BU_SG_REL_ Kombi SG_ 960 ZAS_Kl_S 1000;
BA_REL_ "GenSigTimeoutTime" BU_SG_REL_ Kombi SG_ 988 ESP_07_alt 500;
BA_REL_ "GenSigTimeoutTime" BU_SG_REL_ Kombi SG_ 988 ESP_Rollenmodus_Deaktivieren 500;
BA_REL_ "GenSigTimeoutTime" BU_SG_REL_ Kombi SG_ 1283 HVK_Gesamtst_Spgfreiheit 1000;
BA_REL_ "GenSigTimeoutTime" BU_SG_REL_ Kombi SG_ 1283 HVK_HV_Netz_Warnungen 1000;
BA_REL_ "GenSigTimeoutTime" BU_SG_REL_ Kombi SG_ 1420 KST_Fahrer_Info_Text 5000;
BA_REL_ "GenSigTimeoutTime" BU_SG_REL_ Kombi SG_ 1420 KST_Txt_Panikabschaltung 5000;
BA_REL_ "GenSigTimeoutTime" BU_SG_REL_ Kombi SG_ 1420 KST_Txt_Werkstatt 5000;
BA_REL_ "GenSigTimeoutTime" BU_SG_REL_ Kombi SG_ 1420 KST_Zuendungswarnung 5000;
BA_REL_ "GenSigTimeoutTime" BU_SG_REL_ Kombi SG_ 2527679583 IPA_Anf_Meldungen 5000;
BA_REL_ "GenSigTimeoutTime" BU_SG_REL_ Kombi SG_ 2589283617 DBK_Fahrerwarnung 5000;
BA_REL_ "GenSigTimeoutTime" BU_SG_REL_ Kombi SG_ 2589283617 ESC_MBK_Meldungen 5000;
BA_REL_ "GenSigTimeoutTime" BU_SG_REL_ Kombi SG_ 2589283617 ESP_30_BZ 5000;
BA_REL_ "GenSigTimeoutTime" BU_SG_REL_ Kombi SG_ 2589283617 ESP_30_CRC 5000;
BA_REL_ "GenSigTimeoutTime" BU_SG_REL_ Kombi SG_ 2589283617 RLE_Anzeigen 5000;
BA_REL_ "GenSigTimeoutTime" BU_SG_REL_ Kombi SG_ 2589283684 FoD_Anz_Funktionsabschaltung 5000;
BA_REL_ "GenSigTimeoutTime" BU_SG_REL_ SmartLight_01 SG_ 960 ZAS_Kl_15 1000;
BA_REL_ "GenSigTimeoutTime" BU_SG_REL_ ZR_MIB_TOP_ab_Gen3 SG_ 588 ASW_Ton_Richtung_HL 500;
BA_REL_ "GenSigTimeoutTime" BU_SG_REL_ ZR_MIB_TOP_ab_Gen3 SG_ 588 ASW_Ton_Richtung_HR 500;
BA_REL_ "GenSigTimeoutTime" BU_SG_REL_ ZR_MIB_TOP_ab_Gen3 SG_ 588 ASW_Ton_Richtung_VL 500;
BA_REL_ "GenSigTimeoutTime" BU_SG_REL_ ZR_MIB_TOP_ab_Gen3 SG_ 588 ASW_Ton_Richtung_VR 500;
BA_REL_ "GenSigTimeoutTime" BU_SG_REL_ ZR_MIB_TOP_ab_Gen3 SG_ 960 ZAS_Kl_15 1000;
BA_REL_ "GenSigTimeoutTime" BU_SG_REL_ ZR_MIB_TOP_ab_Gen3 SG_ 960 ZAS_Kl_50_Startanforderung 1000;
BA_REL_ "GenSigTimeoutTime" BU_SG_REL_ ZR_MIB_TOP_ab_Gen3 SG_ 960 ZAS_Kl_S 1000;
BA_REL_ "GenSigTimeoutTime" BU_SG_REL_ ZR_MIB_TOP_ab_Gen3 SG_ 960 ZAS_Kl_X 1000;
BA_REL_ "GenSigTimeoutTime" BU_SG_REL_ ZR_MIB_TOP_ab_Gen3 SG_ 988 ESP_07_alt 500;
BA_REL_ "GenSigTimeoutTime" BU_SG_REL_ ZR_MIB_TOP_ab_Gen3 SG_ 988 ESP_Rollenmodus_Deaktivieren 500;
BA_REL_ "GenSigTimeoutTime" BU_SG_REL_ ZR_MIB_TOP_ab_Gen3 SG_ 988 GE_Fahrstufe 500;
BA_REL_ "GenSigTimeoutTime" BU_SG_REL_ ZR_MIB_TOP_ab_Gen3 SG_ 988 MO_QBit_Drehzahl_01 500;
BA_REL_ "GenSigTimeoutTime" BU_SG_REL_ ZR_MIB_TOP_ab_Gen3 SG_ 988 Motor_12_alt 500;
BA_REL_ "GenSigTimeoutTime" BU_SG_REL_ ZR_MIB_TOP_ab_Gen3 SG_ 2589283684 FoD_Transmission_Info 5000;
VAL_ 2589283617 DBK_Fahrerwarnung 0 "kein_Anfordern" 1 "Warnung_Aufforderung_Anhalten" 2 "Warnung_Aufforderung_Werkstatt" 3 "nicht_belegt" ;
VAL_ 2589283617 EDS_Charisma_FahrPr 0 "keine_Funktion" 1 "Programm_1" 2 "Programm_2" 3 "Programm_3" 4 "Programm_4" 5 "Programm_5" 6 "Programm_6" 7 "Programm_7" 8 "Programm_8" 9 "Programm_9" 10 "Programm_10" 11 "Programm_11" 12 "Programm_12" 13 "Programm_13" 14 "Programm_14" 15 "Programm_15" ;
VAL_ 2589283617 EDS_Charisma_Status 0 "Init" 1 "verfuegbar" 2 "nicht_verfuegbar" 3 "asynchron_durch_Fahrerwunsch" ;
VAL_ 2589283617 ESC_Anf_KV 0 "kein_Oeffnen" 1 "Oeffnen" ;
VAL_ 2589283617 ESC_FBA_Meldungen 0 "kein_Text" 1 "FBA_Warnung_aktiv_MT" 2 "FBA_Warnung_aktiv_AT" ;
VAL_ 2589283617 ESC_Lernfreigabe_Abrollumfang 0 "keine_Lernfreigabe" 1 "Lernfreigabe" ;
VAL_ 2589283617 ESC_MBK_Meldungen 0 "kein_Text" 1 "MBK_Hinweis_aktiv" 2 "MBK_Eskalation1_aktiv" ;
VAL_ 2589283617 ESC_Texte_eBKV_Betaetigung 0 "keine_Anzeige" 1 "Halten_ueber_Schaltwippen_aktiv" 2 "Beide_Schaltwippen_betaetigen" 3 "Abbr_Halten_ueber_Schaltwippen" 4 "Bremspedal_betaetigen" 5 "Fahrpedal_loesen_Bremse_treten" ;
VAL_ 2589283617 HHC_Charisma_FahrPr 0 "keine_Funktion" 1 "Programm_1" 2 "Programm_2" 3 "Programm_3" 4 "Programm_4" 5 "Programm_5" 6 "Programm_6" 7 "Programm_7" 8 "Programm_8" 9 "Programm_9" 10 "Programm_10" 11 "Programm_11" 12 "Programm_12" 13 "Programm_13" 14 "Programm_14" 15 "Programm_15" ;
VAL_ 2589283617 HHC_Charisma_Status 0 "Init" 1 "verfuegbar" 2 "nicht_verfuegbar" 3 "asynchron_durch_Fahrerwunsch" ;
VAL_ 2589283617 HMS_EML_Steig_Exkl 0 "Init" 1023 "Fehler" ;
VAL_ 2589283617 RLE_Anzeigen 0 "keine_Anzeige" 1 "Rad_lose_allgemein" 2 "Rad_VL_lose" 3 "Rad_VR_lose" 4 "Rad_HL_lose" 5 "Rad_HR_lose" 6 "RLE_Pruefphase" 7 "RLE_Systemstoerung" ;
VAL_ 2527679740 KBI_aktive_Laengsfunktion_02 0 "Init" 1 "Speedlimiter" 2 "GRA_oder_ACC" 3 "PACCh" 4 "HDC" 5 "p_GRA" 6 "p_Lim" 7 "ACC_im_GRA_Modus" 8 "Travel_Assist" 9 "RHP" ;
VAL_ 2527679740 KBI_Anzeigefehler_LDW 0 "nicht vorhanden bzw. unterstï?½tzt" 1 "Anzeige iO" 2 "Anzeigefehler" 3 "nicht definiert" ;
VAL_ 2527679740 KBI_Anzeigestatus_ACC 0 "keine_ACC_Anzeige" 1 "ACC_Anzeige_aktiv" ;
VAL_ 2527679740 KBI_Anzeigestatus_GRA 0 "nicht_vorhanden" 1 "Anzeigemoeglichkeit_vorhanden" 2 "reserviert" 3 "Fehler" ;
VAL_ 2527679740 KBI_Anzeigestatus_LIM 0 "nicht_vorhanden" 1 "Anzeigemoeglichkeit_vorhanden" 2 "reserviert" 3 "Fehler" ;
VAL_ 2527679740 KBI_Fehler_Anzeige_ACC 0 "" ;
VAL_ 2527679740 KBI_Konsistenz_ACC 0 "ACC Botschaft konsistent" 1 "ACC Botschaft inkonsistent" ;
VAL_ 2589283684 FoD_Anz_Funktionsabschaltung 0 "Init" 1 "Popup_aufschalten" ;
VAL_ 2589283684 FoD_State_IPA_RPA 0 "default" 1 "nicht_aktiv" 2 "IPA_aktiv" 3 "IPA_und_RPA_aktiv" ;
VAL_ 2589283684 FoD_State_TopView_SideView_RVC 0 "default" 1 "RVC_TopView_SideView_nicht_aktiv" 2 "RVC_aktiv" 3 "RVC_nicht_aktiv" 4 "TopView_SideView_nicht_aktiv" 5 "RVC_TopView_aktiv" 6 "SideView_aktiv" 7 "RVC_SideView_aktiv" 8 "RVC_TopView_SideView_aktiv" ;
VAL_ 2589283684 FoD_State_TPA_rTPA 0 "default" 1 "nicht_aktiv" 2 "TPA_aktiv" 3 "TPA_und_rTPA_aktiv" ;
VAL_ 2589283684 FoD_Transmission_Info 0 "Initwert" 1 "start_transmission" 2 "finish_transmission" ;
VAL_ 2589283684 GRA_FoD_Status 0 "Init" 1 "Funktion_inaktiv" 2 "Funktion_aktiv" ;
VAL_ 2549875476 FoD_Kombi_Req_Data 0 "Init" ;
VAL_ 2550006548 FoD_Kombi_Resp_Data 0 "Init" ;
VAL_ 986 ABS_Bremsung 0 "keine_ABS_Regelung" 1 "ABS_Regelung_aktiv" ;
VAL_ 986 ECD_Bremslicht 0 "Aus" 1 "Ein" ;
VAL_ 986 EPB_01_alt 0 "aktuell" 1 "veraltet" ;
VAL_ 986 EPB_Pedalweg_Kuppl 0 "Init" 255 "Fehler" ;
VAL_ 986 EPB_QBit_Pedalweg_Kuppl 0 "gï?½ltiger Wert" 1 "Ersatz-, Init- oder Fehlerwert" ;
VAL_ 986 EPB_Status 0 "offen" 1 "Bremse_geschl_(Spannkraft_voll/reduziert)" 2 "Aktuator_im_Lauf" 3 "Fehler_oder_unbekannt" ;
VAL_ 986 ESP_05_alt 0 "aktuell" 1 "veraltet" ;
VAL_ 986 ESP_21_alt 0 "aktuell" 1 "veraltet" ;
VAL_ 986 ESP_Eingriff 0 "kein_ESP_Eingriff" 1 "ESP_Eingriff_aktiv" ;
VAL_ 986 ESP_HDC_Standby 0 "HDC_Funktion_nicht_im_Standby" 1 "HDC_Funktion_im_Standby" ;
VAL_ 986 ESP_MKB_Abbruch_Geschw 0 "MKB_nicht_beendet_wg_v_Schwelle" 1 "MKB_beendet_wg_v_Schwelle" ;
VAL_ 986 ESP_QBit_v_Signal 0 "gueltiger_Wert" 1 "Ersatz_Init_oder_Fehlerwert" ;
VAL_ 986 ESP_v_Signal 65533 "Unterspannung" 65534 "Init" 65535 "Fehler" ;
VAL_ 986 Kamera_FSH_aktiv 0 "Kamera_Frontscheibenheizung_nicht_aktiviert" 1 "Kamera_Frontscheibenheizung_aktiviert" ;
VAL_ 986 Kamera_Status_alt 0 "aktuell" 1 "veraltet" ;
VAL_ 986 LWI_01_alt 0 "aktuell" 1 "veraltet" ;
VAL_ 986 LWI_Lenkradwinkel 8190 "Init" 8191 "Fehler" ;
VAL_ 986 LWI_QBit_Lenkradwinkel 0 "gï?½ltiger Wert" 1 "ausserhalb der Spezifikation" ;
VAL_ 986 LWI_Sensorstatus 0 "iO" 1 "nicht kalibriert" ;
VAL_ 986 LWI_VZ_Lenkradwinkel 0 "positiv_links_von_der_Nullstellung" 1 "negativ" ;
VAL_ 986 Parkhilfe_01_alt 0 "aktuell" 1 "veraltet" ;
VAL_ 986 PH_Anf_Audioabsenkung 0 "Keine_Audioabsenkung" 1 "Anforderung_Audioabsenkung" ;
VAL_ 986 PH_Systemzustand 0 "Anlage aus" 1 "Anlage durch einlegen R-Gang aktiviert" 2 "Anlage manuell durch Taster aktiviert" 3 "Anlage automatisch aktiviert" 4 "Anlage durch ARA aktiviert" 6 "Init - Initialisierungsphase nach Kl. 15 ein / Reset" 7 "Fehler-/gestï?½rt Zustand, System noch aktiv" ;
VAL_ 986 PH_Taster 0 "Taster_nicht_gedrueckt" 1 "Taster_gedrueckt" 2 "reserviert" 3 "Fehler" ;
VAL_ 986 PLA_Anf_Aufschaltung_RVC 0 "Keine_RVC_Aufschalteanf" 1 "RVC_Aufschalteanforderung" ;
VAL_ 988 ACC_18_alt 0 "aktuell" 1 "veraltet" ;
VAL_ 988 ACC_Status_ACC 0 "ACC_OFF_Hauptschalter_aus" 1 "ACC_INIT" 2 "ACC_STANDBY" 3 "ACC_AKTIV_regelt" 4 "ACC_OVERRIDE" 5 "ACC_Abschaltreaktion" 6 "reversibler_Fehler_im_ACC_System" 7 "irreversibler_Fehler_im_ACC_System" ;
VAL_ 988 EPB_Status_02 0 "offen" 1 "geschlossen_Parken" 2 "teilgespannt_Halten" 3 "im_Lauf_oeffnen" 4 "im_Lauf_schliessen" 5 "tbd" 6 "Init" 7 "unbekannt" ;
VAL_ 988 ESP_07_alt 0 "aktuell" 1 "veraltet" ;
VAL_ 988 ESP_50_alt 0 "aktuell" 1 "veraltet" ;
VAL_ 988 ESP_Rollenmodus_Deaktivieren 0 "keine_Aenderung" 1 "Abbruch" ;
VAL_ 988 ESP_Status_Bremsentemp_02 0 "nicht_erhoeht" 1 "Schwelle_1" 2 "Schwelle_2" ;
VAL_ 988 GE_Fahrstufe 0 "Zwischenstellung" 1 "Init" 5 "Position_P" 6 "Position_R" 7 "Position_N" 8 "Position_D" 9 "Position_S" 10 "Effizienz" 13 "Tipp_in_S" 14 "Tipp_in_D" 15 "Fehler" ;
VAL_ 988 GE_Freilauf_Status 0 "Freilauf_inaktiv_aber_moeglich" 1 "Freilauf_aktiv" 2 "Freilauf_nicht_moegl_1Verhinderer" 3 "Freilauf_nicht_moegl_gr_1Verhinderer" 7 "Fehler" ;
VAL_ 988 GE_Notlauf 0 "kein Notlauf / Init" 1 "Getriebe im Notlauf" ;
VAL_ 988 GE_Sperr_Info_WFS 0 "nicht_gesperrt" 1 "gesperrt" ;
VAL_ 988 GE_Ursache_Fahrstufe_N 0 "Fahrstufe_N_mit_Fahrerwunsch" 1 "Fahrstufe_N_ohne_Fahrerwunsch" ;
VAL_ 988 Getriebe_11_alt 0 "aktuell" 1 "veraltet" ;
VAL_ 988 Getriebe_13_alt 0 "aktuell" 1 "veraltet" ;
VAL_ 988 Getriebe_14_alt 0 "aktuell" 1 "veraltet" ;
VAL_ 988 Getriebe_17_alt 0 "aktuell" 1 "veraltet" ;
VAL_ 988 MKE_Stufe 0 "deaktiviert" 1 "nicht_verfï?½gbar" 2 "Stufe_1" 3 "Stufe_2" 4 "Stufe_3" 5 "Stufe_4" 6 "reserviert" 7 "reserviert" ;
VAL_ 988 MKE_Texte 0 "keine_Anzeige" 1 "Warnstufe_1" 2 "Warnstufe_2" ;
VAL_ 988 MO_QBit_Drehzahl_01 0 "gueltiger_Wert" 1 "Ersatz_Init_oder_Fehlerwert" ;
VAL_ 988 Motor_12_alt 0 "aktuell" 1 "veraltet" ;
VAL_ 988 TSK_06_alt 0 "aktuell" 1 "veraltet" ;
VAL_ 988 TSK_Hauptschalter_GRA_ACC 0 "Init" 1 "Aus" 2 "Ein" 3 "Fehler" ;
VAL_ 988 TSK_Limiter_ausgewaehlt 0 "kein_Limiter_ausgewaehlt" 1 "Limiter_ausgewaehlt" ;
VAL_ 324 GE_Ausleuchtung_blinkend 0 "kein_Blinken" 1 "Blinken" ;
VAL_ 324 GE_Ausleuchtung_Fahrstufe 0 "Init" 5 "D" 6 "N" 7 "R" 8 "P" 10 "Tipp_Plus" 11 "Tipp_Minus" 12 "S" 13 "Kurz_Manuell_Programm" 14 "Tipp_Gasse" 15 "Fehler" ;
VAL_ 324 GE_N_Haltephase 0 "nicht_aktiv" 1 "aktiv" ;
VAL_ 324 GE_Soll_Haltemagnet 0 "Init_nicht_verwendet" 1 "nicht_halten" 2 "halten" 3 "keine_Vorgabe" ;
VAL_ 324 GE_Test_Freigabe 0 "kein Test" 1 "gï?½ltige Testparameter" ;
VAL_ 324 GE_WH_Abschalten 0 "Wï?½hlhebel-SG ein" 1 "Wï?½hlhebel-SH aus" ;
VAL_ 324 GE_WH_Mute 0 "Senden_ein" 1 "Senden_aus" ;
VAL_ 324 GE_WH_Shiftlock 0 "Waehlhebel_sperren" 1 "Waehlhebel_freigeben" ;
VAL_ 324 WH_Warnung_02 0 "Keine_Anzeige" 1 "Waehlhebel_defekt_Weiterfahrt_moeglich" 2 "Waehlhebel_in_Automatgasse_zurueckstellen" 3 "P_Taste_defekt" 4 "Zeitueberschr_P_wird_eingelegt" 5 "Wegrollgefahr__P_nicht_moeglich" ;
VAL_ 588 ASW_Kombiausgabe 0 "Keine_Anzeige" 1 "zur_Zeit_nicht_verfuegbar" 2 "Systemfehler" 3 "Sensor_blockiert" 4 "Anhaengerbetrb_nicht_verfuegbar" ;
VAL_ 588 ASW_Kombitexte 0 "keine Anzeige. // Prio 5" 1 "Text_1_ASW_zur_Zeit_nicht_verfuegbar_und_Akustik // Prio 2" 2 "Text_2_ASW_Systemfehler_und_Akustik // Prio 1" 3 "Text_3_ASW_Sensor_blockiert_und_Akustik // Prio 3" 4 "Text_4_ASW_im_Anhaengerbetrieb_nicht_verfuegbar_und_Akustik // Prio 4" 5 "Text_5_ASW_Warnung_FS_und_Akustik" 6 "Text_6_ASW_Warnung_BFS_und_Akustik" 7 "Text_7_ASW_aus" ;
VAL_ 588 ASW_Modus 0 "kein_Fehler_KL15" 1 "kein_Fehler_KL30" 2 "reserve" 3 "Anhaengerbetrieb" 4 "Init_nicht_codiert" 5 "keine_Sensorsicht_blindheit" 6 "Zur_zeit_nicht_verfuegbar_temp_Fehler" 7 "Systemstoerung_dauer_fehler" ;
VAL_ 588 ASW_Status 0 "Passiv" 1 "Aktiv" 2 "Fehler" 3 "AUS" ;
VAL_ 588 ASW_Ton_Richtung_HL 0 "kein_Warnton" 1 "Warnton" ;
VAL_ 588 ASW_Ton_Richtung_HR 0 "kein_Warnton" 1 "Warnton" ;
VAL_ 588 ASW_Ton_Richtung_VL 0 "kein_Warnton" 1 "Warnton" ;
VAL_ 588 ASW_Ton_Richtung_VR 0 "kein_Warnton" 1 "Warnton" ;
VAL_ 588 ASW_Warnung_BFS 0 "inaktiv" 1 "aktiv" ;
VAL_ 588 ASW_Warnung_FS 0 "inaktiv" 1 "aktiv" ;
VAL_ 588 Heckradar_Kombitexte 0 "keine Anzeige. // Prio 5" 1 "Text_1_SWA_und_ASW_zur_Zeit_nicht_verfuegbar_und_Akustik // Prio 2" 2 "Text_2_SWA_und_ASW_Systemfehler_und_Akustik // Prio 1" 3 "Text_3_SWA_und_ASW_Sensor_blockiert_und_Akustik // Prio 3" 4 "Text_4_SWA_und_ASW_im_Anhaengerbetrieb_nicht_verfuegbar_und_Akustik // Prio 4" 5 "Text_1_SWA_und_RCTA_zur_Zeit_nicht_verfuegbar_und_Akustik // Prio 2" 6 "Text_2_SWA_und_RCTA_Systemfehler_und_Akustik // Prio 1" 7 "" ;
VAL_ 588 HRE_Anzeigetexte 0 "keine_Anzeige" 1 "BSD_RTA_zZt_nicht_verfuegbar" 2 "BSD_RTA_Systemfehler" 3 "BSD_RTA_Sensor_blockiert" 4 "BSD_RTA_Anhaengerbetrieb" 5 "RTA_Warnung" 6 "BSD_Warnung" 7 "Fahreruebernahme_Notbremsung" 8 "RTA_nicht_verfuegbar" 9 "BSD_RTA_ASW_zZt_nicht_verfuegbar" 10 "BSD_RTA_ASW_Systemfehler" 11 "BSD_RTA_ASW_Sensor_blockiert" 12 "BSD_RTA_ASW_Anhaengerbetrieb" ;
VAL_ 588 RCTA_Kombitexte 0 "keine_Anzeige" 1 "RCTA_zur_Zeit_nicht_verfuegbar" 2 "RCTA_Systemfehler" 3 "RCTA_Sensor_blockiert" 4 "RCTA_im_Anhaengerbetrieb" 5 "RTA_Warnung" 6 "Fahreruebernahme_Notbremsung" 7 "Eingeschraenkt_verfuegbar_ESCaus" ;
VAL_ 588 SWA_Anzeigen 0 "keine_Anzeige" 1 "Text_1_SWA_zurzeit_nicht_verfuegbar" 2 "Text_2_SWA_Systemstoerung" 3 "Text_3_SWA_zurzeit_nicht_verfuegbar_Keine_Sensorsicht" 4 "Text_4_SWA_zurzeit_nicht_verfuegbar_Anhaengerbetrieb" 5 "Text_5_SWA_Eskalation" 6 "Text_6_SWA_eingeschrï?½nkt" ;
VAL_ 588 SWA_Blindheit_erkannt 0 "nicht erkannt" 1 "erkannt" ;
VAL_ 588 SWA_Blindheitsverdacht 0 "kein_Blindheitsverdacht_erkannt" 1 "Blindheitsverdacht_erkannt" ;
VAL_ 588 SWA_Brightness_Mode_FPM 0 "Init" 1 "No_error" 2 "Trailer_active" 3 "Muted_by_driver" 4 "Blind" 5 "not_selectable" 6 "not_available" 7 "Privacy_Mode" 8 "No_License" 9 "License_expired" 14 "Temporary_error" 15 "Fehler" ;
VAL_ 588 SWA_FT_RueckLED 0 "inaktiv" 1 "aktiv" ;
VAL_ 588 SWA_Infostufe_Assist_li 0 "keine_Infostufe" 1 "Infostufe_aktiv" ;
VAL_ 588 SWA_Infostufe_Assist_re 0 "keine_Infostufe" 1 "Infostufe_aktiv" ;
VAL_ 588 SWA_Kombiausgabe 0 "Keine_Anzeige" 1 "zur_Zeit_nicht_verfuegbar" 2 "Systemfehler" 3 "Sensor_blockiert" 4 "Anhaengerbetrb_nicht_verfuegbar" 5 "Sensor_teilweise_blockiert" ;
VAL_ 588 SWA_LED_Hell_BFS 126 "Init" 127 "Fehler" ;
VAL_ 588 SWA_LED_Hell_FS 126 "Init" 127 "Fehler" ;
VAL_ 588 SWA_LED_Modus_BFS 0 "LED_aus" 1 "Infostufe" 2 "Warnstufe" 3 "Aufpruefen_Kl15" 4 "Aufpruefen_BAP" ;
VAL_ 588 SWA_LED_Modus_FS 0 "LED_aus" 1 "Infostufe" 2 "Warnstufe" 3 "Aufpruefen_Kl15" 4 "Aufpruefen_BAP" ;
VAL_ 588 SWA_Modus 0 "kein_Fehler_verfuegbar" 1 "kein_Fehler_eingeschr_Reichweite" 2 "reserve" 3 "Anhaengerbetrieb" 4 "Init_nicht_codiert" 5 "keine_Sensorsicht_blindheit" 6 "Zur_zeit_nicht_verfuegbar_temp_Fehler" 7 "Systemstoerung_dauer_fehler" ;
VAL_ 588 SWA_Modus_System 0 "nicht_verfuegbar" 1 "verfuegbar" 2 "Anhaengerbetrieb" 3 "eingeschraenkte_Sensorsicht" 4 "keine_Sensorsicht" 5 "reserved" 6 "temporaerer_Fehler" 7 "dauerhafter_Fehler" ;
VAL_ 588 SWA_rel_Fehler 0 "kein Fehler" 1 "Fehler" ;
VAL_ 588 SWA_rel_Nichtverf 0 "verfuegbar" 1 "nicht verfuegbar" ;
VAL_ 588 SWA_Sta_aktiv 0 "Aus" 1 "Ein" ;
VAL_ 588 SWA_Sta_passiv 0 "Aus" 1 "Ein" ;
VAL_ 588 SWA_Standziele_li 0 "Abstand i.O." 1 "Abstand zu gering" ;
VAL_ 588 SWA_Standziele_re 0 "Abstand i.O." 1 "Abstand zu gering" ;
VAL_ 588 SWA_Status 0 "aus" 1 "passiv" 2 "aktiv" 3 "Fehler" ;
VAL_ 588 SWA_Status_KuFu 0 "aus" 1 "passiv" 2 "aktiv" 3 "Fehler" ;
VAL_ 588 SWA_Status_System 0 "aus" 1 "passiv" 2 "aktiv" 3 "Fehler" ;
VAL_ 588 SWA_Warnstufe_Assist_li 0 "keine_Warnstufe" 1 "Warnstufe_aktiv" ;
VAL_ 588 SWA_Warnstufe_Assist_re 0 "keine_Warnstufe" 1 "Warnstufe_aktiv" ;
VAL_ 589 SWA_Infostufe_SWA_li 0 "keine_Aktion" 1 "Aktion" ;
VAL_ 589 SWA_Infostufe_SWA_re 0 "keine_Aktion" 1 "Aktion" ;
VAL_ 589 SWA_Kolonne_li 0 "zwei_oder_weniger_Fahrzeuge_auf_der_Spur" 1 "mehr_als_zwei_Fahrzeuge_auf_der_Spur" ;
VAL_ 589 SWA_Kolonne_mi 0 "zwei_oder_weniger_Fahrzeuge_auf_der_Spur" 1 "mehr_als_zwei_Fahrzeuge_auf_der_Spur" ;
VAL_ 589 SWA_Kolonne_re 0 "zwei_oder_weniger_Fahrzeuge_auf_der_Spur" 1 "mehr_als_zwei_Fahrzeuge_auf_der_Spur" ;
VAL_ 589 SWA_Obj_01_Breite 127 "Init" ;
VAL_ 589 SWA_Obj_01_Existenzwahrsch 127 "Init" ;
VAL_ 589 SWA_Obj_01_Gemessen 0 "ObjektpositionY_geschaetzt" 1 "ObjektpositionY_bestaetigt" ;
VAL_ 589 SWA_Obj_01_GeschwRelX 511 "Init" ;
VAL_ 589 SWA_Obj_01_GeschwRelY 511 "Init" ;
VAL_ 589 SWA_Obj_01_ID 0 "kein_Objekt_enthalten" 31 "Init" ;
VAL_ 589 SWA_Obj_01_Laenge 127 "Init" ;
VAL_ 589 SWA_Obj_01_Objektklasse 0 "unbekannt" 1 "dynamisch" 2 "VRU" 3 "Fussgaenger" 4 "Fussgaengergruppe" 5 "Radfahrer" 6 "Motorrad" 7 "PKW" 8 "mindestens_Vierrad" 9 "LKW" 10 "Zweirad" 11 "Tier" 12 "mindestens_Zweirad" 13 "Objektcluster" 15 "Init" ;
VAL_ 589 SWA_Obj_01_PositionX 511 "Init" ;
VAL_ 589 SWA_Obj_01_PositionY 255 "Init" ;
VAL_ 589 SWA_Obj_01_ReferenzPkt 0 "unbekannt" 1 "vorne_links" 2 "vorne_mitte" 3 "vorne_rechts" 4 "mitte_rechts" 5 "hinten_rechts" 6 "hinten_mitte" 7 "hinten_links" 8 "mitte_links" 9 "objekt_mitte" 15 "Init" ;
VAL_ 589 SWA_Obj_02_Breite 127 "Init" ;
VAL_ 589 SWA_Obj_02_Existenzwahrsch 127 "Init" ;
VAL_ 589 SWA_Obj_02_Gemessen 0 "ObjektpositionY_geschaetzt" 1 "ObjektpositionY_bestaetigt" ;
VAL_ 589 SWA_Obj_02_GeschwRelX 511 "Init" ;
VAL_ 589 SWA_Obj_02_GeschwRelY 511 "Init" ;
VAL_ 589 SWA_Obj_02_ID 0 "kein_Objekt_enthalten" 31 "Init" ;
VAL_ 589 SWA_Obj_02_Laenge 127 "Init" ;
VAL_ 589 SWA_Obj_02_Objektklasse 0 "unbekannt" 1 "dynamisch" 2 "VRU" 3 "Fussgaenger" 4 "Fussgaengergruppe" 5 "Radfahrer" 6 "Motorrad" 7 "PKW" 8 "mindestens_Vierrad" 9 "LKW" 10 "Zweirad" 11 "Tier" 12 "mindestens_Zweirad" 13 "Objektcluster" 15 "Init" ;
VAL_ 589 SWA_Obj_02_PositionX 511 "Init" ;
VAL_ 589 SWA_Obj_02_PositionY 255 "Init" ;
VAL_ 589 SWA_Obj_02_ReferenzPkt 0 "unbekannt" 1 "vorne_links" 2 "vorne_mitte" 3 "vorne_rechts" 4 "mitte_rechts" 5 "hinten_rechts" 6 "hinten_mitte" 7 "hinten_links" 8 "mitte_links" 9 "objekt_mitte" 15 "Init" ;
VAL_ 589 SWA_Obj_03_Breite 127 "Init" ;
VAL_ 589 SWA_Obj_03_Existenzwahrsch 127 "Init" ;
VAL_ 589 SWA_Obj_03_Gemessen 0 "ObjektpositionY_geschaetzt" 1 "ObjektpositionY_bestaetigt" ;
VAL_ 589 SWA_Obj_03_GeschwRelX 511 "Init" ;
VAL_ 589 SWA_Obj_03_GeschwRelY 511 "Init" ;
VAL_ 589 SWA_Obj_03_ID 0 "kein_Objekt_enthalten" 31 "Init" ;
VAL_ 589 SWA_Obj_03_Laenge 127 "Init" ;
VAL_ 589 SWA_Obj_03_Objektklasse 0 "unbekannt" 1 "dynamisch" 2 "VRU" 3 "Fussgaenger" 4 "Fussgaengergruppe" 5 "Radfahrer" 6 "Motorrad" 7 "PKW" 8 "mindestens_Vierrad" 9 "LKW" 10 "Zweirad" 11 "Tier" 12 "mindestens_Zweirad" 13 "Objektcluster" 15 "Init" ;
VAL_ 589 SWA_Obj_03_PositionX 511 "Init" ;
VAL_ 589 SWA_Obj_03_PositionY 255 "Init" ;
VAL_ 589 SWA_Obj_03_ReferenzPkt 0 "unbekannt" 1 "vorne_links" 2 "vorne_mitte" 3 "vorne_rechts" 4 "mitte_rechts" 5 "hinten_rechts" 6 "hinten_mitte" 7 "hinten_links" 8 "mitte_links" 9 "objekt_mitte" 15 "Init" ;
VAL_ 589 SWA_Obj_04_Breite 127 "Init" ;
VAL_ 589 SWA_Obj_04_Existenzwahrsch 127 "Init" ;
VAL_ 589 SWA_Obj_04_Gemessen 0 "ObjektpositionY_geschaetzt" 1 "ObjektpositionY_bestaetigt" ;
VAL_ 589 SWA_Obj_04_GeschwRelX 511 "Init" ;
VAL_ 589 SWA_Obj_04_GeschwRelY 511 "Init" ;
VAL_ 589 SWA_Obj_04_ID 0 "kein_Objekt_enthalten" 31 "Init" ;
VAL_ 589 SWA_Obj_04_Laenge 127 "Init" ;
VAL_ 589 SWA_Obj_04_Objektklasse 0 "unbekannt" 1 "dynamisch" 2 "VRU" 3 "Fussgaenger" 4 "Fussgaengergruppe" 5 "Radfahrer" 6 "Motorrad" 7 "PKW" 8 "mindestens_Vierrad" 9 "LKW" 10 "Zweirad" 11 "Tier" 12 "mindestens_Zweirad" 13 "Objektcluster" 15 "Init" ;
VAL_ 589 SWA_Obj_04_PositionX 511 "Init" ;
VAL_ 589 SWA_Obj_04_PositionY 255 "Init" ;
VAL_ 589 SWA_Obj_04_ReferenzPkt 0 "unbekannt" 1 "vorne_links" 2 "vorne_mitte" 3 "vorne_rechts" 4 "mitte_rechts" 5 "hinten_rechts" 6 "hinten_mitte" 7 "hinten_links" 8 "mitte_links" 9 "objekt_mitte" 15 "Init" ;
VAL_ 589 SWA_Obj_05_Breite 127 "Init" ;
VAL_ 589 SWA_Obj_05_Existenzwahrsch 127 "Init" ;
VAL_ 589 SWA_Obj_05_Gemessen 0 "ObjektpositionY_geschaetzt" 1 "ObjektpositionY_bestaetigt" ;
VAL_ 589 SWA_Obj_05_GeschwRelX 511 "Init" ;
VAL_ 589 SWA_Obj_05_GeschwRelY 511 "Init" ;
VAL_ 589 SWA_Obj_05_ID 0 "kein_Objekt_enthalten" 31 "Init" ;
VAL_ 589 SWA_Obj_05_Laenge 127 "Init" ;
VAL_ 589 SWA_Obj_05_Objektklasse 0 "unbekannt" 1 "dynamisch" 2 "VRU" 3 "Fussgaenger" 4 "Fussgaengergruppe" 5 "Radfahrer" 6 "Motorrad" 7 "PKW" 8 "mindestens_Vierrad" 9 "LKW" 10 "Zweirad" 11 "Tier" 12 "mindestens_Zweirad" 13 "Objektcluster" 15 "Init" ;
VAL_ 589 SWA_Obj_05_PositionX 511 "Init" ;
VAL_ 589 SWA_Obj_05_PositionY 255 "Init" ;
VAL_ 589 SWA_Obj_05_ReferenzPkt 0 "unbekannt" 1 "vorne_links" 2 "vorne_mitte" 3 "vorne_rechts" 4 "mitte_rechts" 5 "hinten_rechts" 6 "hinten_mitte" 7 "hinten_links" 8 "mitte_links" 9 "objekt_mitte" 15 "Init" ;
VAL_ 589 SWA_Obj_06_Breite 127 "Init" ;
VAL_ 589 SWA_Obj_06_Existenzwahrsch 127 "Init" ;
VAL_ 589 SWA_Obj_06_Gemessen 0 "ObjektpositionY_geschaetzt" 1 "ObjektpositionY_bestaetigt" ;
VAL_ 589 SWA_Obj_06_GeschwRelX 511 "Init" ;
VAL_ 589 SWA_Obj_06_GeschwRelY 511 "Init" ;
VAL_ 589 SWA_Obj_06_ID 0 "kein_Objekt_enthalten" 31 "Init" ;
VAL_ 589 SWA_Obj_06_Laenge 127 "Init" ;
VAL_ 589 SWA_Obj_06_Objektklasse 0 "unbekannt" 1 "dynamisch" 2 "VRU" 3 "Fussgaenger" 4 "Fussgaengergruppe" 5 "Radfahrer" 6 "Motorrad" 7 "PKW" 8 "mindestens_Vierrad" 9 "LKW" 10 "Zweirad" 11 "Tier" 12 "mindestens_Zweirad" 13 "Objektcluster" 15 "Init" ;
VAL_ 589 SWA_Obj_06_PositionX 511 "Init" ;
VAL_ 589 SWA_Obj_06_PositionY 255 "Init" ;
VAL_ 589 SWA_Obj_06_ReferenzPkt 0 "unbekannt" 1 "vorne_links" 2 "vorne_mitte" 3 "vorne_rechts" 4 "mitte_rechts" 5 "hinten_rechts" 6 "hinten_mitte" 7 "hinten_links" 8 "mitte_links" 9 "objekt_mitte" 15 "Init" ;
VAL_ 589 SWA_Obj_Kurvenradius 65535 "Init" ;
VAL_ 589 SWA_StrukturLinks_querAbstand 511 "Init" ;
VAL_ 589 SWA_StrukturLinks_Typ 0 "inaktiv" 1 "durchgehend_baulich" 2 "verkettet_baulich" 3 "unregelmaessig_oder_unbekannt" 4 "punktfoermig" 5 "verdeckt" 6 "frei" ;
VAL_ 589 SWA_StrukturRechts_querAbstand 511 "Init" ;
VAL_ 589 SWA_StrukturRechts_Typ 0 "inaktiv" 1 "durchgehend_baulich" 2 "verkettet_baulich" 3 "unregelmaessig_oder_unbekannt" 4 "punktfoermig" 5 "verdeckt" 6 "frei" ;
VAL_ 589 SWA_Umfeld_Zeitstempel_Status 0 "reserved" 1 "Zeitstempel_PLT_synchro" 2 "Zeitstempel_Datenalter" 3 "reserved" 4 "Fehler_Sync_fehlerhaft" 5 "reserved" 6 "reserved" 7 "init" ;
VAL_ 589 SWA_Warnung_SWA_li 0 "keine Warnung" 1 "Warnung aktiv" ;
VAL_ 589 SWA_Warnung_SWA_re 0 "keine Warnung" 1 "Warnung aktiv" ;
VAL_ 1283 HV_Bordnetz_aktiv 0 "inaktiv" 1 "aktiv" ;
VAL_ 1283 HV_Bordnetz_Fehler 0 "kein_Fehler" 1 "Fehler" ;
VAL_ 1283 HVK_AktiveEntladung_Anf 0 "nicht_angefordert" 1 "angefordert" ;
VAL_ 1283 HVK_BMS_Sollmodus 0 "HV_Off" 1 "HV_On" 3 "AC_Laden_erw" 4 "AC_Laden" 6 "DC_Laden" 7 "Init" ;
VAL_ 1283 HVK_DCDC_Sollmodus 0 "Standby" 1 "HV_On_Vorladen" 2 "Tiefsetzen" 3 "Hochsetzen" 4 "Pruefpuls_12V" 6 "Pruefpuls_DC_Laden" 7 "Initialisierung" ;
VAL_ 1283 HVK_EKK_Sollmodus 0 "Keine_Freigabe" 1 "Freigabe" 2 "Freigabe_ausgesetzt" 7 "Init" ;
VAL_ 1283 HVK_Gesamtst_Spgfreiheit 0 "Funktion_Init__ohne_Funktion" 1 "HV_System_spannungsfrei" 2 "HV_System_nicht_spannungsfrei" 3 "Fehler" ;
VAL_ 1283 HVK_HV_Netz_Warnungen 0 "Keine_Warnung" 1 "Warntext_HV_Netz_Anf" 2 "Fehlertext_HV_Netz_Anf" 3 "Warnung_Kein_Wiederstart_moeglich" ;
VAL_ 1283 HVK_HVEM_Freigabe 0 "keine_Freigabe" 1 "Freigabe" 2 "Init" ;
VAL_ 1283 HVK_HVLM_Sollmodus 0 "keine_Freigabe" 1 "Freigabe_Lademanager" 2 "Vorladung_AC_Pfad" 7 "Init" ;
VAL_ 1283 HVK_HVPTC_Sollmodus 0 "Keine_Freigabe" 1 "Freigabe" 2 "Freigabe_ausgesetzt" 7 "Init" ;
VAL_ 1283 HVK_Iso_Messung_Start 0 "keine_Messung" 1 "Messung_HV_Netz_1" 2 "Messung_HV_Netz_2" 4 "deaktiviert" ;
VAL_ 1283 HVK_Istmodus_Anf 0 "nicht_angefordert" 1 "angefordert" ;
VAL_ 1283 HVK_Ladebereit 0 "Init_oder_nicht_Ladebereit" 1 "AC_Ladebereit" 2 "DC_Ladebereit" 3 "AC_und_DC_Ladebereit" 4 "Induktiv_Ladebereit" 5 "AC_und_Induktiv_Ladebereit" 6 "DC_und_Induktiv_Ladebereit" 7 "AC_DC_und_Induktiv_Ladebereit" ;
VAL_ 1283 HVK_Notabschaltung_Anf 0 "keine_Anforderung_Notabschaltung" 1 "Anforderung_Notabschaltung" 2 "Reserve" 3 "Init" ;
VAL_ 1283 HVK_PPulsFreigabe 0 "keine_Freigabe" 1 "Freigabe" 2 "Reserve" 3 "Init" ;
VAL_ 1283 HVK_TN1_Sollmodus 0 "HV_Off" 1 "HV_On" 2 "reserviert" 3 "Initialisierung" ;
VAL_ 1283 HVK_Vorladung_aktiv 0 "Vorladung_nicht_aktiv" 1 "Vorladung_aktiv" ;
VAL_ 2527679583 FoD_DTC_IPA_EPH 0 "Kein_DTC" 1 "IPA_DTC_vorhanden" ;
VAL_ 2527679583 FoD_DTC_RPA_EPH 0 "Kein_DTC" 1 "RPA_DTC_vorhanden" ;
VAL_ 2527679583 FoD_DTC_TPA_rTPA_EPH 0 "Kein_DTC" 1 "TPA_DTC_vorhanden" 2 "rTPA_DTC_vorhanden" 3 "TPA_und_rTPA_DTC_vorhanden" ;
VAL_ 2527679583 IPA_Anf_Meldungen 0 "keine Meldung" 1 "beendet" 2 "Fahrinf_Bremse_FT_betaetigen" 3 "Suche_fortsetzen_ESC_Eingriff" 4 "n_a_temp_ESC_deaktiviert" 5 "n_a_temp_Anhaengerbetrieb" 6 "Suche_Zeitlimit_ueberschritten" 7 "Undefined" 8 "Fahrinf_PaLueSu_aufschalten" 9 "RPARemoteWunschAbgebrochen" 10 "IPAGeschwindigkeitReduzieren" 11 "IPARPAAktivierung2" 12 "AP_nicht_moeglich" 13 "RPAGarageStart" 14 "n_a_temp_Tuer_Heckklappe_offen" 15 "Stby_Tuer_Heckklappe_schliessen" 16 "PP_aktiv_nur_aussen_bedienbar" 17 "RPAUebergabe2" 18 "n_a_Offroad_Modus" 19 "PP_Schluessel_oder_App_bedienen" 20 "RPAUebergabe1" 21 "PP_Schluessel_bedienen" 22 "IPAAbbruchSuchfahrt" 23 "Systemstoerung_Service" 24 "n_a_temp_Sensorsicht" 25 "IPAAbbruchSuchfahrtLadestecke" 26 "IPAPausierenWeiterfahrt" 27 "n_a_temp_FAS_aktiv" 28 "PP_BT_unterbrochen" 29 "Hindernis_in_Fahrtrichtung" 30 "IPAAusparkenBlinker" 31 "RPAUebernahme" 32 "Suche_Rangierflaeche_zu_klein" 33 "n_a_temp_Drive_Select" 34 "IPAAktivierung1" 35 "Fahrinf_Fahrtrichtungswechsel" 36 "RPARemoteWunsch" 37 "GP_Fzgposition_vor_Garage" 38 "GP_RT_Garage_oeffnen" 39 "GP_Kein_Zuparken" 40 "Suche_Fahrinfo_beachten" 41 "GP_Fzgposition_freie_Parkflaeche" 42 "GP_n_a_temp_Laser" 43 "Geschwindigkeitsueberschreitung" 44 "Fahrinf_Weiter_vorfahren" 45 "RPAAktivierung1" 46 "Fahrinf_Anhalten" 47 "GP_AP_nicht_moeglich_Fahrweg" 48 "PP_Gang_Schluesselauthentifizier" 49 "Fahrhinweis_FT_betaetigen" 50 "PP_aktiv_Hinweis_FUEN" 128 "Disclaimer_LP_rechts" 129 "Disclaimer_LP_links" 130 "Disclaimer_RQ_rechts" 131 "Disclaimer_RQ_links" 132 "Disclaimer_VQ_rechts" 133 "Disclaimer_VQ_links" 134 "Disclaimer_AP_rechts" 135 "Disclaimer_AP_links" 136 "IPARPAAktivierung3" 137 "IPAAbbruchLenkeingriff" 138 "IPAAbbruchAnhaenger" 139 "IPARPAAktivierung4" 140 "IPAAbbruchZeitlimit" 141 "IPAFahrzeugAusgeparkt" 142 "IPAFahrzeugEingeparkt" 143 "IPAPausieren" 144 "IPAAbbruchESC" 145 "Stby_Verkehr_erkannt" 146 "MAAbbruchLenkeingriff" 147 "IPAAbbruchSchaltung" 148 "IPAAbbruchParklueckeKlein" 149 "IPABordsteinheber2" 150 "IPAAbbruchSensorsicht" 151 "Beendet_Stoerung_Fzgverbindung" 152 "Beendet_selbst_bremsen" 153 "IPAAbbruchFahrdynamischerEing" 154 "IPAAbbruchFalscheBewegungsric" 155 "IPAAbbruchDiETaSchliesskreuz" 156 "IPAPausierenHindernis" 157 "FUEN_moeglich" 158 "IPABordsteinheber4" 159 "IPAAbbruchOffroadModus" 160 "IPABordsteinheber5" 161 "PP_Fehler_Schluesselautorisier" 162 "IPABordsteinheber6" 163 "IPABordsteinheber7" 164 "Stby_FT_oder_RT_betaetigen" 165 "Stby_Hindernis_Richtungswechsel" 166 "Stby_erhoehter_Fahrwiderstand" 167 "Abbruch_EPB_aktiviert" 168 "Abbruch_MO_nicht_bereit" 169 "IPAAbbruchPDC" 170 "Abbruch_Gurtschloss_gesteckt" 171 "IPAAbbruchGeschwindigkeitHoch" 172 "IPAPausierenTueren" 173 "IPAAbbruchNotstopp" 174 "IPAAbbruchFahrerabwesenheit" 175 "IPAAbbruchSystempartner" 176 "PosOK_Lenkrad_loslassen_Bremse" 177 "PosOK_Lenkrad_loslassen_FT" 178 "Wiederaufnahme_FT_betaetigen" 179 "IPABordsteinheber9" 180 "IPAAbbruchKlemme15Aus" 181 "IPABordsteinheber8" 192 "TPA_aborted_deviated_from_trajec" 193 "TPA_aborted_limited_visibility" 194 "TPA_aborted_localization_failure" 195 "TPA_aborted_System_error" 196 "TPA_aborted_TPA_canceled" 197 "TPA_unavlbl_localization_failure" 198 "TPA_unavlbl_limited_visibility" 199 "TPA_unavlbl_System_error" 200 "TPA_temp_unavailable" 201 "TPA_Platzhalter_1" 202 "TPA_Platzhalter_2" 203 "TPA_Platzhalter_3" 204 "TPA_Platzhalter_4" 205 "TPA_Platzhalter_5" 206 "TPA_Platzhalter_6" 207 "TPA_Platzhalter_7" ;
VAL_ 2527679583 Parken_aktives_System_02 0 "Init" 1 "Keine_Aktivitaet" 2 "RPA" 3 "IPA" 4 "MA" 5 "TP" 6 "rTP" 7 "AAA" 8 "rAAA" 9 "ARA_1" 10 "PLA" 11 "RBF" 12 "PHP" 13 "RA" ;
VAL_ 2527679583 Parken_Aktivierungslicht_Anf 0 "keine_Anforderung" 1 "Aktivierungslicht" ;
VAL_ 2527679583 Parken_Bestaetigungsblinken_Anf 0 "keine_Anforderung" 1 "Erfolgsblinken_Einparken" 2 "Abbruchsblinken" 3 "Erfolgsblinken_Ausparken" ;
VAL_ 2527679583 Parken_Fahrbereitschaftlicht_Anf 0 "keine_Anforderung" 1 "Fahrbereitschaftslicht" ;
VAL_ 2527679583 Parken_Fahrerhinweise_Anf 0 "keine_Anforderung" 1 "Fahrerhinweise_anzeigen" ;
VAL_ 2527679583 Parken_Fahrtrichtungslicht_Anf 0 "keine_Anforderung" 1 "Vorwaerts" 2 "Rueckwaerts" ;
VAL_ 2527679583 Parken_FFB_LED_Anf 0 "keine_Anforderung" 1 "Abbruch_Fehler" 2 "Bereit_OK" 3 "Beendet" ;
VAL_ 2527679583 Parken_Lichtnachlauf_Anf 0 "keine_Anforderung" 1 "Anforderung_Lichtnachlauf" ;
VAL_ 2527679583 Parken_Lichtsteuerung_Anf 0 "keine_Anforderung" 1 "Automatik_Lichtmodus_aktivieren" ;
VAL_ 2527679583 Parken_Schluesselsuche_Anf 0 "keine_Anforderung" 1 "Anforderung_Schluesselsuche" ;
VAL_ 2527679583 Parken_Seitenspiegel_Anf 0 "Keine_Anforderung" 1 "Seitenspiegel_anklappen" 2 "Seitenspiegel_abklappen" ;
VAL_ 2527679583 Parken_Wegfahrsperren_Anf 0 "keine_Anforderung" 1 "Anforderung_Fahreruebernahme" 2 "Anforderung_Fahreruebergabe" ;
VAL_ 2527679583 Parken_ZR_Sondermodus_Anf 0 "Init" 1 "Keine_Anforderung" 2 "Anforderung_Sondermodus" ;
VAL_ 2527679583 Parken_ZV_Schliessen 0 "Keine_Anforderung" 1 "ZV_verriegeln" 2 "ZV_safen" ;
VAL_ 2527679583 RA_Anf_Meldung 0 "keine_Meldung" 1 "RA_Aktivierung_1" 2 "RA_Aktivierung_2" 3 "RA_Aktiv" 4 "RA_beendet" 5 "RA_Geschwindigkeit_reduzieren" 6 "RA_Hinweis_Ladestecker" 7 "RA_Bremse" 8 "RA_Abbruch_vorAktivierung" 9 "RA_Abbruch_Timeout" 10 "RA_Abbruch_Lenkeingriff" 11 "RA_Abbruch_Anhaenger" 12 "RA_Abbruch_ESC" 13 "RA_Abbruch_Gangwechsel" 14 "RA_Abbruch_Sensorsicht" 15 "RA_Abbruch_Fahrdynamischer_Eingr" 16 "RA_Abbruch_generisch_mA" 17 "RA_Abbruch_Hindernis_1" 18 "RA_Abbruch_Hindernis_2" 19 "RA_Abbruch_Geschwindigkeit_hoch" 20 "RA_Abbruch_Tueren" 21 "RA_Abbruch_Fahrerabwesenheit" 22 "RA_Deaktivierung_1" 23 "RA_Deaktivierung_2" 24 "RA_Abbruch_Trajektorie_1" 25 "RA_Nichtverfuegbarkeit" 26 "RA_Abbruch_Gurt" 27 "RA_Abbruch_Moduswechsel" 28 "RA_Moduswechsel" 29 "RA_Abbbruch_Wischwasser" 30 "RA_Abbruch_Wischer_defekt" 31 "RA_Gurt" 32 "RA_Wischwasser" 33 "RA_Wischer_defekt" 34 "RA_Abbruch_Aussenlichtsteuerung" 35 "RA_Aussenlichtsteuerung_defekt" 36 "RA_Abbruch_Trajektorie_2" 37 "RA_Abbruch_generisch_oA" 38 "RA_Uebernahme" 39 "RA_Geschwindigkeit_hoch" 40 "RA_Ladeklappe" 41 "RA_Abbruch_Ladeklappe" 42 "RA_RGang_einlegen" 43 "RA_Meldung_1" 44 "RA_Meldung_2" 45 "RA_Meldung_3" 46 "RA_Meldung_4" 47 "RA_Meldung_5" 48 "RA_Meldung_6" 49 "RA_Meldung_7" 50 "RA_Meldung_8" 51 "RA_Meldung_9" 52 "RA_Meldung_10" 53 "RA_Meldung_11" 54 "RA_Meldung_12" 55 "RA_Meldung_13" 56 "RA_Meldung_14" 57 "RA_Meldung_15" 58 "RA_Meldung_16" 59 "RA_Meldung_17" 60 "RA_Meldung_18" 61 "RA_Meldung_19" 62 "RA_Meldung_20" 63 "RA_Meldung_21" 64 "RA_Meldung_22" 65 "RA_Meldung_23" 66 "RA_Meldung_24" 67 "RA_Meldung_25" 68 "RA_Meldung_26" 69 "RA_Meldung_27" 70 "RA_Meldung_28" ;
VAL_ 1426 KY_Aktive_LFScans 0 "Init" 1 "Entry_Exit_Scan_1" 2 "Entry_Exit_Scan_2" 3 "GO_Scan_1" 4 "GO_Scan_2" 5 "Keyminder_Scan" 6 "ServiceKey1_Scan" 7 "ServiceKey2_Scan" 8 "Komfortlauf_RW_Begrenzer" 9 "Komfortlauf_RW_Begrenzer_EHeck" 10 "RSSI_Scan_EasyClose" 11 "PU_Scan" 12 "Diagnose_Scan" ;
VAL_ 1426 KY_AnzKoord_Info 0 "Init" 1 "Keyminder_Suche_erfolgreich" 2 "Keyminder_Suche_negativ" ;
VAL_ 1426 KY_EasyClose_Abbruch 0 "EasyClose_kein_Abbruch" 1 "EasyClose_Abbruch" ;
VAL_ 1426 KY_EasyClose_Status 0 "Lampe_AUS" 1 "Lampe_EIN" 2 "Lampe_NORMAL" 3 "Lampe_HEKTIK" 4 "Akustik_Verweigerung" ;
VAL_ 1426 KY_Fzg_Verlassen_erkannt 0 "nicht_erkannt" 1 "erkannt" ;
VAL_ 1426 KY_Fzg_Zugang_erkannt 0 "nicht_erkannt" 1 "erkannt" ;
VAL_ 1426 KY_Gestik_HD 0 "inaktiv" 1 "aktiv" ;
VAL_ 1426 KY_Gong_600 0 "inaktiv" 1 "aktiv" ;
VAL_ 1426 KY_HD_Auffahrt 0 "keine_Anforderung" 1 "HD_Auffahrt_angefordert" ;
VAL_ 1426 KY_HD_Zufahrt 0 "keine_Anforderung" 1 "HD_Zufahrt_angefordert" ;
VAL_ 1426 KY_ID_Geber1_im_Fzg 0 "inaktiv" 1 "aktiv" ;
VAL_ 1426 KY_ID_Geber2_im_Fzg 0 "inaktiv" 1 "aktiv" ;
VAL_ 1426 KY_ID_Geber3_im_Fzg 0 "inaktiv" 1 "aktiv" ;
VAL_ 1426 KY_ID_Geber4_im_Fzg 0 "inaktiv" 1 "aktiv" ;
VAL_ 1426 KY_ID_Geber_Suche 0 "inaktiv" 1 "aktiv" ;
VAL_ 1426 KY_LF_Aktiv 0 "Funktempfang_nicht_aktiv" 1 "LF_Funkempfang_aktiv" ;
VAL_ 1426 KY_Meldungen 0 "keine_Meldung" 1 "Schluessel_nicht_gefunden" 2 "Schluessel_im_Kofferraum" 3 "Schluessel_im_Fahrzeug" 4 "Kessy_defekt" ;
VAL_ 1426 KY_Passiv_Autolock 0 "inaktiv" 1 "aktiv" ;
VAL_ 1426 KY_Passiv_Autolock_Akt 0 "inaktiv" 1 "aktiv" ;
VAL_ 1426 KY_Passiv_Autolock_Menue 0 "inaktiv" 1 "aktiv" ;
VAL_ 1426 KY_Passiv_Autounlock 0 "inaktiv" 1 "aktiv" ;
VAL_ 1426 KY_Schluesselposition_1 0 "nicht_gefunden" 1 "im_Innenraum_gefunden" 2 "im_Aussenraum_gefunden_nah" 3 "im_Aussenraum_gefunden_fern" ;
VAL_ 1426 KY_Schluesselposition_2 0 "nicht_gefunden" 1 "im_Innenraum_gefunden" 2 "im_Aussenraum_gefunden_nah" 3 "im_Aussenraum_gefunden_fern" ;
VAL_ 1426 KY_Schluesselposition_3 0 "nicht_gefunden" 1 "im_Innenraum_gefunden" 2 "im_Aussenraum_gefunden_nah" 3 "im_Aussenraum_gefunden_fern" ;
VAL_ 1426 KY_Schluesselposition_4 0 "nicht_gefunden" 1 "im_Innenraum_gefunden" 2 "im_Aussenraum_gefunden_nah" 3 "im_Aussenraum_gefunden_fern" ;
VAL_ 1426 KY_Schluesselposition_5 0 "nicht_gefunden" 1 "im_Innenraum_gefunden" 2 "im_Aussenraum_gefunden_nah" 3 "im_Aussenraum_gefunden_fern" ;
VAL_ 1426 KY_Schluesselposition_6 0 "nicht_gefunden" 1 "im_Innenraum_gefunden" 2 "im_Aussenraum_gefunden_nah" 3 "im_Aussenraum_gefunden_fern" ;
VAL_ 1426 KY_Schluesselposition_7 0 "nicht_gefunden" 1 "im_Innenraum_gefunden" 2 "im_Aussenraum_gefunden_nah" 3 "im_Aussenraum_gefunden_fern" ;
VAL_ 1426 KY_Schluesselposition_8 0 "nicht_gefunden" 1 "im_Innenraum_gefunden" 2 "im_Aussenraum_gefunden_nah" 3 "im_Aussenraum_gefunden_fern" ;
VAL_ 1426 KY_Schluesselposition_9 0 "nicht_gefunden" 1 "im_Innenraum_gefunden" 2 "im_Aussenraum_gefunden_nah" 3 "im_Aussenraum_gefunden_fern" ;
VAL_ 1426 KY_Startknopf_Bel 0 "inaktiv" 1 "aktiv" ;
VAL_ 1426 KY_StartStopp_Info 0 "Motorlauf_nicht_notwendig_(Stoppfreigabe)" 1 "Motoranlauf_nicht_zwingend_notwendig_(Stoppverbot,keine_Startanforderung)" 2 "Motoranlauf_zwingend_notwendig_(Startanforderung)" 3 "Systemfehler" ;
VAL_ 960 BCM_Ausparken_Betrieb 0 "kein_Betrieb" 1 "Ausparkvorgang_aktiv" ;
VAL_ 960 KST_Fahrerhinweis_1 0 "inaktiv" 1 "aktiv" ;
VAL_ 960 KST_Fahrerhinweis_2 0 "inaktiv" 1 "aktiv" ;
VAL_ 960 KST_Fahrerhinweis_4 0 "inaktiv" 1 "aktiv" ;
VAL_ 960 KST_Fahrerhinweis_5 0 "inaktiv" 1 "aktiv" ;
VAL_ 960 KST_Fahrerhinweis_6 0 "inaktiv" 1 "aktiv" ;
VAL_ 960 KST_Warn_P1_ZST_def 0 "nicht_defekt" 1 "defekt" ;
VAL_ 960 KST_Warn_P2_ZST_def 0 "nicht_defekt" 1 "defekt" ;
VAL_ 960 RSt_Fahrerhinweise 0 "Init" 1 "Fahreruebernahme_Hinweis_ZAT_Automat_ohne_Gong" 2 "Fahreruebernahme_Hinweis_ZAT_Automat_mit_Gong" 3 "Fahreruebernahme_Hinweis_ZAT_Handschalter_ohne_Gong" 4 "Fahreruebernahme_Hinweis_ZAT_Handschalter_mit_Gong" 5 "Fahreruebernahme_Hinweis_ZAS_Automat_ohne_Gong" 6 "Fahreruebernahme_Hinweis_ZAS_Automat_mit_Gong" 7 "Fahreruebernahme_Hinweis_ZAS_Handschalter_ohne_Gong" 8 "Fahreruebernahme_Hinweis_ZAS_Handschalter_mit_Gong" 9 "RemoteStart_aktiv_ohne_Gong" 10 "RemoteStart_aktiv_mit_Gong" 11 "void" 12 "void" 13 "void" 14 "void" 15 "void" ;
VAL_ 960 ZAS_Kl_15 0 "aus" 1 "ein" ;
VAL_ 960 ZAS_Kl_50_Startanforderung 0 "aus" 1 "KL50_ein_Startwunsch_Fahrer" ;
VAL_ 960 ZAS_Kl_Infotainment 0 "inaktiv" 1 "aktiv" ;
VAL_ 960 ZAS_Kl_S 0 "aus" 1 "S_Kontakt_ein" ;
VAL_ 960 ZAS_Kl_X 0 "aus" 1 "ein" ;
VAL_ 2463978753 KST_ComfortReadyStatus 0 "aus" 1 "ComfortReadyStatus_ein" ;
VAL_ 2463978753 KST_Sonderzustand_Anforderung 0 "Init" 1 "RemoteStart" 2 "RemoteParkAssist" 3 "IntelligentParkAssist" 4 "TrainiertesParken" 5 "OnlineRemoteUpdate" 6 "Einfrierschutz" 7 "Klemme15ViaDiagnose" 8 "RueckwandklappenSicherungPDC" 9 "ParkHausPilot" 10 "AnhaengerAnkuppelAssistent" 11 "MotorWeiterlaufSchaltung" 31 "Fehler" ;
VAL_ 2463978753 KST_Sonderzustand_Status 0 "Init" 1 "Uebergang_neue_Anforderung" 2 "Aktiv" 3 "Fehler" ;
VAL_ 2463978753 KST_WFS_Fahrfreigabe_Anforderung 0 "Keine" 1 "Uneingeschraenkt" 2 "Eingeschraenkt" ;
VAL_ 1420 KST_Anf_Klemme_15 0 "nicht_angefordert" 1 "angefordert" ;
VAL_ 1420 KST_Anf_Klemme_50 0 "nicht_angefordert" 1 "angefordert" ;
VAL_ 1420 KST_Anf_Klemme_S 0 "nicht_angefordert" 1 "angefordert" ;
VAL_ 1420 KST_Anf_Klemmenfreigabe_ELV 0 "nicht_angefordert" 1 "angefordert" ;
VAL_ 1420 KST_Anf_Klemmenfreigabe_WFS 0 "nicht_angefordert" 1 "angefordert" ;
VAL_ 1420 KST_Anf_ZV_Verriegelung 0 "inaktiv" 1 "aktiv" ;
VAL_ 1420 KST_aut_Abschaltung_Zuendung 0 "Zuendung_wird_bei_Verl_nicht_deaktiviert" 1 "Zuendung_wird_bei_Verl_deaktiviert" ;
VAL_ 1420 KST_Fahrer_Info_Text 0 "nicht_Aktiv" 1 "Fahrerhinweis_1" 2 "Fahrerhinweis_2" ;
VAL_ 1420 KST_KL15LockStatus 0 "Idle" 1 "LockReleased" 2 "LockActive" ;
VAL_ 1420 KST_Txt_Komfortabschaltung 0 "inaktiv" 1 "aktiv" ;
VAL_ 1420 KST_Txt_P_Gang 0 "Aus" 1 "Ein" ;
VAL_ 1420 KST_Txt_Panikabschaltung 0 "Aus" 1 "Ein" ;
VAL_ 1420 KST_Txt_Werkstatt 0 "Aus" 1 "Ein" ;
VAL_ 1420 KST_Unterdr_Zuendungsmeldung 0 "keine_Unterdr_der_Zuendungsmeldung" 1 "Unterdr_der_Zuendungsmeldung_aktiv" ;
VAL_ 1420 KST_ZAT_betaetigt 0 "Aus" 1 "Ein" ;
VAL_ 1420 KST_Zuendungswarnung 0 "keine_Ausgabe_Zuendungswarnung" 1 "Ausg_Zuendungswarnung_Stillstand" 2 "Ausg_Zuendungswarnung_Fahrt" 3 "reserved" ;
VAL_ 1420 Relais_VoKo_angesteuert 0 "nicht_angesteuert" 1 "angesteuert" ;
VAL_ 1420 RSt_Anforderung_HMS 0 "keine_Anforderung" 1 "halten" 2 "parken" 3 "halten_Standby" 4 "anfahren" 5 "Loesen_ueber_Rampe" 6 "Parken_mit_P" ;
